VERSION "HNNBNNNYNNNNNNNNNNNNNNNNNNNNNNNNNNNNNNNNNN/4/%%%/4/'%**4NNN///"

NS_ :

BS_:

BU_: AEM BAP_Tester E_Sound FBK FLA Gateway Gateway_PAG ISE MRR_HL MRR_HR NightVision RDK SAK SAK2 SCR STH_MLBevo TopView

BO_ 917 LWR_AFS_01: 8 Gateway
 SG_ AFS_Abbiegelicht_li_Anf : 0|1@1+ (1.0,0.0) [0.0|1] ""  Vector__XXX
 SG_ AFS_Abbiegelicht_re_Anf : 1|1@1+ (1.0,0.0) [0.0|1] ""  Vector__XXX
 SG_ AFS_Abbiegelicht_Dimm_Anf : 2|1@1+ (1.0,0.0) [0.0|1] ""  Vector__XXX
 SG_ AFS_Verfuegbarkeit_GLW : 3|1@1+ (1.0,0.0) [0.0|1] ""  Vector__XXX
 SG_ AFS_Status_adaptive_LV : 4|1@1+ (1.0,0.0) [0.0|1] ""  Vector__XXX
 SG_ AFS_Fernlicht_li_defekt : 5|1@1+ (1.0,0.0) [0.0|1] ""  Vector__XXX
 SG_ AFS_Fernlicht_re_defekt : 6|1@1+ (1.0,0.0) [0.0|1] ""  Vector__XXX
 SG_ AFS_Fernlicht_Status : 7|1@1+ (1.0,0.0) [0.0|1] ""  Vector__XXX
 SG_ LWR_AFS_01_BZ : 8|4@1+ (1,0) [0|15] ""  Vector__XXX
 SG_ AFS_Lampe : 12|1@1+ (1.0,0.0) [0.0|1] ""  Vector__XXX
 SG_ LWR_Lampe : 13|1@1+ (1.0,0.0) [0.0|1] ""  Vector__XXX
 SG_ AFS_Fehlertext : 14|1@1+ (1.0,0.0) [0.0|1] ""  Vector__XXX
 SG_ AFS_LED_Blinkmode : 15|1@1+ (1.0,0.0) [0.0|1] ""  Vector__XXX
 SG_ LWR_Touristenmodus_aktiv : 16|1@1+ (1.0,0.0) [0.0|1] ""  Vector__XXX
 SG_ AFS_Charisma_FahrPr : 17|4@1+ (1.0,0.0) [0.0|15] ""  Vector__XXX
 SG_ AFS_Charisma_Status : 21|2@1+ (1.0,0.0) [0.0|3] ""  Vector__XXX
 SG_ LWR_Sicherheitsposition_re : 23|1@1+ (1.0,0.0) [0.0|1] ""  Vector__XXX
 SG_ AFS_Allwetterlicht : 24|1@1+ (1.0,0.0) [0.0|1] ""  Vector__XXX
 SG_ LWR_Touristenmodus_verbaut : 25|1@1+ (1.0,0.0) [0.0|1] ""  Vector__XXX
 SG_ AFS_adaptive_LV_verbaut : 26|1@1+ (1.0,0.0) [0.0|1] ""  Vector__XXX
 SG_ LWR_Reisemodus_Texte : 27|2@1+ (1.0,0.0) [0.0|3] ""  Vector__XXX
 SG_ GLW_Sensor_blockiert : 29|1@1+ (1.0,0.0) [0.0|1] ""  Vector__XXX
 SG_ AFS_Charisma_Umschaltung : 30|2@1+ (1.0,0.0) [0.0|3] ""  Vector__XXX
 SG_ LWR_Pos_Schrittmotor : 32|8@1+ (0.4,0) [0.0|100.0] "Unit_PerCent"  Vector__XXX
 SG_ LWR_Hoehenwert_VL : 40|8@1+ (1,-127) [-127|126] ""  NightVision,TopView
 SG_ LWR_Hoehenwert_HL : 48|8@1+ (1,-127) [-127|126] ""  NightVision,TopView
 SG_ AFS_Ersatzlicht_Links : 56|1@1+ (1.0,0.0) [0.0|1] ""  Vector__XXX
 SG_ AFS_Ersatzlicht_Rechts : 57|1@1+ (1.0,0.0) [0.0|1] ""  Vector__XXX
 SG_ LWR_AFS_Grundeinstellung : 58|1@1+ (1.0,0.0) [0.0|1] ""  NightVision
 SG_ LWR_AFS_Parametrisierung : 59|1@1+ (1.0,0.0) [0.0|1] ""  Vector__XXX
 SG_ LWR_Initialisierungslauf : 60|1@1+ (1.0,0.0) [0.0|1] ""  Vector__XXX
 SG_ LWR_Sicherheitsposition_li : 61|1@1+ (1.0,0.0) [0.0|1] ""  Vector__XXX
 SG_ LWR_Modus : 62|1@1+ (1.0,0.0) [0.0|1] ""  Vector__XXX

BO_ 1153 MainUnit_01: 8 Gateway
 SG_ ZR_LoGeWa_Event_Kombiwarnung : 0|4@1+ (1.0,0.0) [0.0|15] ""  Vector__XXX
 SG_ Nav_FoD_Status : 4|3@1+ (1.0,0.0) [0.0|7] ""  NightVision
 SG_ MIB_Tongenerator_PH_verfuegbar : 9|3@1+ (1.0,0.0) [0.0|7] ""  Vector__XXX
 SG_ MMI_Counter_Bedienevent : 12|4@1+ (1.0,0.0) [0.0|15] ""  Vector__XXX
 SG_ DSSS_Warning : 16|5@1+ (1.0,0.0) [0.0|31] ""  Vector__XXX
 SG_ ZR_Kindersicherung_RSE : 21|1@1+ (1.0,0.0) [0.0|1] ""  Vector__XXX
 SG_ ZR_RSE_aktivieren : 22|1@1+ (1.0,0.0) [0.0|1] ""  Vector__XXX
 SG_ MMI_SDS_aktiv : 23|1@1+ (1.0,0.0) [0.0|1] ""  Vector__XXX
 SG_ MU_SecondDisplay : 24|3@1+ (1.0,0.0) [0.0|7] ""  Vector__XXX
 SG_ MMI_Telefon_aktiv : 27|1@1+ (1.0,0.0) [0.0|1] ""  Vector__XXX
 SG_ MMI_Gurt_Mic_ref : 28|1@1+ (1.0,0.0) [0.0|1] ""  Vector__XXX
 SG_ ZR_Sta_Inszenierung : 29|2@1+ (1.0,0.0) [0.0|3] ""  Vector__XXX
 SG_ MMI_Gauges_active : 31|1@1+ (1.0,0.0) [0.0|1] ""  Vector__XXX
 SG_ MU_Update_Time : 32|8@1+ (0.1,0) [0.0|25.5] "Unit_Hours"  Vector__XXX
 SG_ ZR_MXB_Manoever_Ansage : 42|2@1+ (1.0,0.0) [0.0|3] ""  Vector__XXX
 SG_ ZR_LAPP_Sondermodus_Status : 44|2@1+ (1.0,0.0) [0.0|3] ""  Vector__XXX
 SG_ MMI_StartStopp_Info : 46|2@1+ (1.0,0.0) [0.0|3] ""  Vector__XXX
 SG_ ZR_Parken_Sondermodus : 48|4@1+ (1.0,0.0) [0.0|15] ""  Vector__XXX
 SG_ ZR_Rundenbewertung : 52|4@1+ (1.0,0.0) [0.0|15] ""  Vector__XXX
 SG_ ZR_Rundenfortschritt : 56|8@1+ (0.5,0) [0.0|100.0] "Unit_PerCent"  Vector__XXX

BO_ 1600 Motor_07: 8 Gateway
 SG_ MO_QBit_Ansaugluft_Temp : 0|1@1+ (1.0,0.0) [0.0|1] ""  Vector__XXX
 SG_ MO_QBit_Oel_Temp : 1|1@1+ (1.0,0.0) [0.0|1] ""  Vector__XXX
 SG_ MO_QBit_Kuehlmittel_Temp : 2|1@1+ (1.0,0.0) [0.0|1] ""  STH_MLBevo
 SG_ MO_KL15_Abschaltempfehlung : 3|1@1+ (1.0,0.0) [0.0|1] ""  Vector__XXX
 SG_ MO_HYB_Fehler_HV_Netz : 4|1@1+ (1.0,0.0) [0.0|1] ""  Vector__XXX
 SG_ MO_aktives_Getriebeheizen : 5|1@1+ (1.0,0.0) [0.0|1] ""  Vector__XXX
 SG_ MO_Absperrventil_oeffnen : 6|2@1+ (1.0,0.0) [0.0|3] ""  STH_MLBevo
 SG_ MO_Ansaugluft_Temp : 8|8@1+ (0.75,-48) [-48.00|141.75] "Unit_DegreCelsi"  Vector__XXX
 SG_ MO_Oel_Temp : 16|8@1+ (1,-60) [-60|192] "Unit_DegreCelsi"  AEM
 SG_ MO_Kuehlmittel_Temp : 24|8@1+ (0.75,-48) [-48.00|141.75] "Unit_DegreCelsi"  AEM,STH_MLBevo
 SG_ MO_Hoeheninfo : 32|8@1+ (0.00781,0) [0.00000|1.98374] ""  STH_MLBevo
 SG_ MO_Kennfeldk : 40|1@1+ (1.0,0.0) [0.0|1] ""  Vector__XXX
 SG_ MO_Versionsinfo_02 : 41|5@1+ (1.0,0.0) [0.0|31] ""  Vector__XXX
 SG_ MO_QBit_Hoeheninfo : 46|1@1+ (1.0,0.0) [0.0|1] ""  Vector__XXX
 SG_ MO_Getriebe_kuehlen : 47|1@1+ (1.0,0.0) [0.0|1] ""  Vector__XXX
 SG_ MO_Mom_Traegheit_02 : 48|5@1+ (0.01,0) [0.00|0.31] "Unit_KiloGramMeterSquar"  Vector__XXX
 SG_ MO_Heizungspumpenansteuerung : 53|4@1+ (10,0) [0|100] "Unit_PerCent"  STH_MLBevo
 SG_ MO_SpannungsAnf : 57|1@1+ (1.0,0.0) [0.0|1] ""  Vector__XXX
 SG_ MO_Nachlaufzeit_Heizungspumpe : 58|6@1+ (15,0) [0|945] "Unit_Secon"  STH_MLBevo

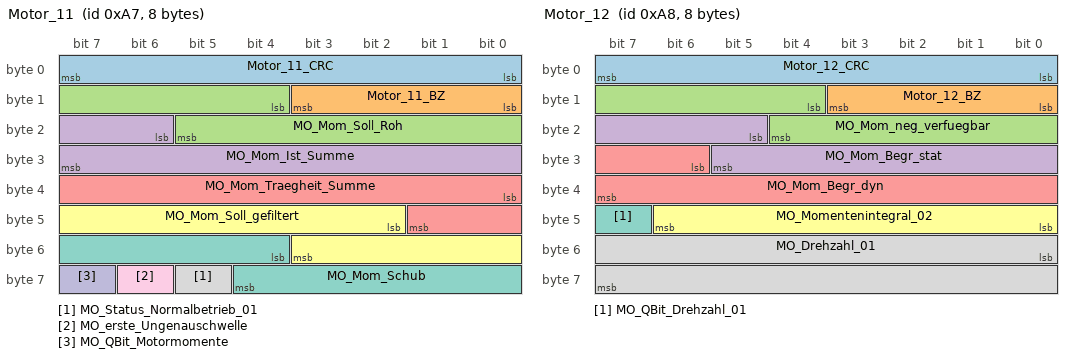
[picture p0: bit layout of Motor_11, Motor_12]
BO_ 167 Motor_11: 8 Gateway
 SG_ Motor_11_CRC : 0|8@1+ (1,0) [0|255] ""  Vector__XXX
 SG_ Motor_11_BZ : 8|4@1+ (1,0) [0|15] ""  Vector__XXX
 SG_ MO_Mom_Soll_Roh : 12|10@1+ (1,-509) [-509|509] ""  Vector__XXX
 SG_ MO_Mom_Ist_Summe : 22|10@1+ (1,-509) [-509|509] ""  AEM,E_Sound,ISE,SAK,SAK2
 SG_ MO_Mom_Traegheit_Summe : 32|10@1+ (1,-509) [-509|509] ""  Vector__XXX
 SG_ MO_Mom_Soll_gefiltert : 42|10@1+ (1,-509) [-509|509] ""  Vector__XXX
 SG_ MO_Mom_Schub : 52|9@1+ (1,-509) [-509|0] ""  Vector__XXX
 SG_ MO_Status_Normalbetrieb_01 : 61|1@1+ (1.0,0.0) [0.0|1] ""  Vector__XXX
 SG_ MO_erste_Ungenauschwelle : 62|1@1+ (1.0,0.0) [0.0|1] ""  Vector__XXX
 SG_ MO_QBit_Motormomente : 63|1@1+ (1.0,0.0) [0.0|1] ""  AEM

BO_ 168 Motor_12: 8 Gateway
 SG_ Motor_12_CRC : 0|8@1+ (1,0) [0|255] ""  Vector__XXX
 SG_ Motor_12_BZ : 8|4@1+ (1,0) [0|15] ""  Vector__XXX
 SG_ MO_Mom_neg_verfuegbar : 12|9@1+ (1,-509) [-509|0] ""  Vector__XXX
 SG_ MO_Mom_Begr_stat : 21|9@1+ (1,0) [0|509] ""  Vector__XXX
 SG_ MO_Mom_Begr_dyn : 30|10@1+ (1,-509) [-509|509] ""  Vector__XXX
 SG_ MO_Momentenintegral_02 : 40|7@1+ (1,0) [0|100] "Unit_PerCent"  Vector__XXX
 SG_ MO_QBit_Drehzahl_01 : 47|1@1+ (1.0,0.0) [0.0|1] ""  AEM,SCR,STH_MLBevo
 SG_ MO_Drehzahl_01 : 48|16@1+ (0.25,0) [0.00|16383.00] "Unit_MinutInver"  AEM,E_Sound,ISE,SAK,SAK2,SCR,STH_MLBevo

BO_ 958 Motor_14: 8 Gateway
 SG_ Motor_14_CRC : 0|8@1+ (1,0) [0|255] ""  Vector__XXX
 SG_ Motor_14_BZ : 8|4@1+ (1,0) [0|15] ""  Vector__XXX
 SG_ MO_StartStopp_Status : 12|2@1+ (1.0,0.0) [0.0|3] ""  AEM,SCR
 SG_ MO_StartStopp_Wiederstart : 14|1@1+ (1.0,0.0) [0.0|1] ""  AEM,FLA,SCR,STH_MLBevo
 SG_ MO_StartStopp_Motorstopp : 15|1@1+ (1.0,0.0) [0.0|1] ""  AEM,NightVision,SCR,STH_MLBevo
 SG_ MO_Freig_Reku : 16|2@1+ (1.0,0.0) [0.0|3] ""  Vector__XXX
 SG_ MO_Kl_75 : 18|1@1+ (1.0,0.0) [0.0|1] ""  AEM,FLA,SCR
 SG_ MO_Kl_50 : 19|1@1+ (1.0,0.0) [0.0|1] ""  AEM
 SG_ MO_Gangposition : 20|4@1+ (1.0,0.0) [0.0|15] ""  E_Sound,FLA,ISE,NightVision,SAK2
 SG_ MO_StartStopp_Fahrerwunsch : 24|2@1+ (1.0,0.0) [0.0|3] ""  AEM,SCR
 SG_ MO_HYB_Fahrbereitschaft : 26|1@1+ (1.0,0.0) [0.0|1] ""  E_Sound,ISE
 SG_ MO_Ext_E_Fahrt_aktiv : 27|1@1+ (1.0,0.0) [0.0|1] ""  Vector__XXX
 SG_ MO_Fahrer_bremst : 28|1@1+ (1.0,0.0) [0.0|1] ""  Vector__XXX
 SG_ MO_QBit_Fahrer_bremst : 29|1@1+ (1.0,0.0) [0.0|1] ""  Vector__XXX
 SG_ MO_BLS : 30|1@1+ (1.0,0.0) [0.0|1] ""  Vector__XXX
 SG_ MO_Konsistenz_Bremsped : 31|1@1+ (1.0,0.0) [0.0|1] ""  Vector__XXX
 SG_ MO_KomFehler_ESP : 32|1@1+ (1.0,0.0) [0.0|1] ""  Vector__XXX
 SG_ MO_Klima_Eingr : 33|2@1+ (1.0,0.0) [0.0|3] ""  Vector__XXX
 SG_ MO_Aussp_Anlass : 35|1@1+ (1.0,0.0) [0.0|1] ""  Vector__XXX
 SG_ MO_Freig_Anlass : 36|1@1+ (1.0,0.0) [0.0|1] ""  Vector__XXX
 SG_ MO_Kuppl_schalter : 37|1@1+ (1.0,0.0) [0.0|1] ""  SAK,SAK2
 SG_ MO_Interlock : 38|1@1+ (1.0,0.0) [0.0|1] ""  Vector__XXX
 SG_ MO_Motor_laeuft : 39|1@1+ (1.0,0.0) [0.0|1] ""  AEM,STH_MLBevo
 SG_ MO_Kickdown : 40|1@1+ (1.0,0.0) [0.0|1] ""  Vector__XXX
 SG_ MO_QBit_KL_75 : 41|1@1+ (1.0,0.0) [0.0|1] ""  SCR
 SG_ MO_EKlKomLeiRed : 42|2@1+ (1.0,0.0) [0.0|3] ""  Vector__XXX
 SG_ MO_Handshake_STH : 44|1@1+ (1.0,0.0) [0.0|1] ""  STH_MLBevo
 SG_ MO_BKV_Unterdruckwarnung : 45|1@1+ (1.0,0.0) [0.0|1] ""  Vector__XXX
 SG_ MO_Freigabe_Segeln : 46|1@1+ (1.0,0.0) [0.0|1] ""  Vector__XXX
 SG_ MO_PTC_Status : 47|3@1+ (1.0,0.0) [0.0|7] ""  Vector__XXX
 SG_ MO_QBit_Gangposition : 50|1@1+ (1.0,0.0) [0.0|1] ""  Vector__XXX
 SG_ MO_Signalquelle_Gangposition : 51|1@1+ (1.0,0.0) [0.0|1] ""  Vector__XXX
 SG_ MO_Remotestart_Betrieb : 52|1@1+ (1.0,0.0) [0.0|1] ""  Vector__XXX
 SG_ MO_Remotestart_moeglich : 53|1@1+ (1.0,0.0) [0.0|1] ""  Vector__XXX
 SG_ MO_Text_Geschw_red : 54|1@1+ (1.0,0.0) [0.0|1] ""  Vector__XXX
 SG_ MO_FMAus_aktiv : 55|1@1+ (1.0,0.0) [0.0|1] ""  Vector__XXX
 SG_ MO_FMAus_Startvariante : 56|2@1+ (1.0,0.0) [0.0|3] ""  Vector__XXX
 SG_ MO_BMS_NV_Anf_stuetzen : 58|1@1+ (1.0,0.0) [0.0|1] ""  Vector__XXX
 SG_ MO_Zylinderabschaltung : 59|2@1+ (1.0,0.0) [0.0|3] ""  AEM,SAK,SAK2
 SG_ MO_HYB_VM_aktiv : 61|1@1+ (1.0,0.0) [0.0|1] ""  E_Sound,ISE,SAK,SAK2
 SG_ MO_StartVorauss_erfuellt : 62|2@1+ (1.0,0.0) [0.0|3] ""  Vector__XXX

BO_ 1648 Motor_18: 8 Gateway
 SG_ MO_max_Ladedruck : 0|6@1+ (0.1,0) [0.0|6.3] "Unit_Bar"  Vector__XXX
 SG_ MO_ANC_Kennfeld_Anf : 6|2@1+ (1.0,0.0) [0.0|3] ""  Vector__XXX
 SG_ MO_Bremslicht_Reku : 8|1@1+ (1.0,0.0) [0.0|1] ""  Vector__XXX
 SG_ MO_StartStopp_PopUp : 9|2@1+ (1.0,0.0) [0.0|3] ""  Vector__XXX
 SG_ MO1_Sperr_Info_WFS : 11|1@1+ (1.0,0.0) [0.0|1] ""  Vector__XXX
 SG_ MO1_Freigabe_Info_WFS : 12|1@1+ (1.0,0.0) [0.0|1] ""  Vector__XXX
 SG_ MO_EPCL : 13|3@1+ (1.0,0.0) [0.0|7] ""  Vector__XXX
 SG_ MO_Zylabsch_Texte_02 : 16|4@1+ (1.0,0.0) [0.0|15] ""  Vector__XXX
 SG_ MO_Fahrzeugtyp : 20|3@1+ (1.0,0.0) [0.0|7] ""  Vector__XXX
 SG_ MO_NMAX_Schaltanzeige : 23|9@1+ (25,0) [0|12775] "Unit_MinutInver"  Vector__XXX
 SG_ MO_Abstellzeit : 32|8@1+ (8,0) [0|2024] "Unit_Minut"  SCR
 SG_ MO_Abstellzeit_Status : 40|2@1+ (1.0,0.0) [0.0|3] ""  SCR
 SG_ MO1_Freigabe_Verfallsinfo_WFS : 42|1@1+ (1.0,0.0) [0.0|1] ""  Vector__XXX
 SG_ MO_Hybrid_StartStopp_LED : 43|2@1+ (1.0,0.0) [0.0|3] ""  Vector__XXX
 SG_ MO_Fehler_Zylabsch : 45|2@1+ (1.0,0.0) [0.0|3] ""  Vector__XXX
 SG_ MO_Anzahl_Abgesch_Zyl : 47|3@1+ (1.0,0.0) [0.0|7] ""  Vector__XXX
 SG_ MO_Zylabsch_Texte : 50|2@1+ (1.0,0.0) [0.0|3] ""  Vector__XXX
 SG_ MO_Ethanol_BS_Texte : 52|3@1+ (1.0,0.0) [0.0|7] ""  Vector__XXX
 SG_ MO_Drehzahl_Warnung : 55|1@1+ (1.0,0.0) [0.0|1] ""  Vector__XXX
 SG_ MO_obere_Drehzahlgrenze : 56|8@1+ (50,0) [50|12750] "Unit_MinutInver"  Vector__XXX

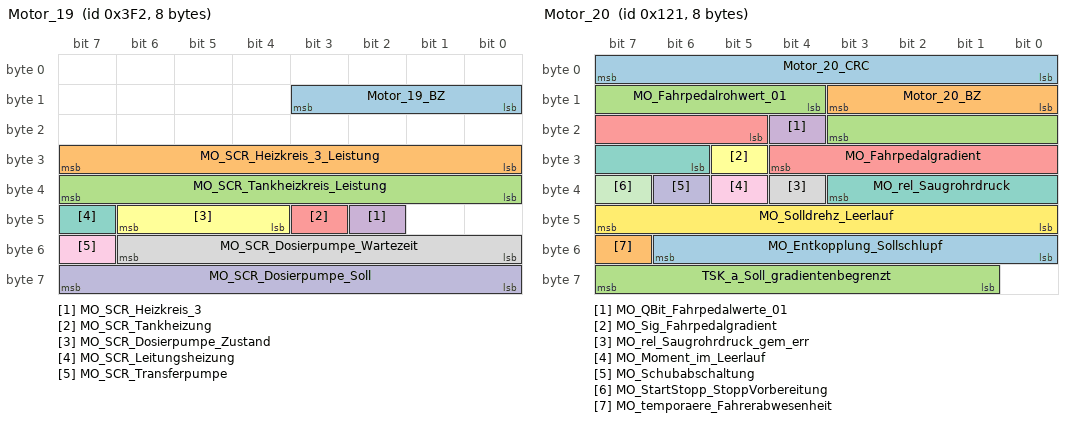
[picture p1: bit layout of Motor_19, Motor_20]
BO_ 1010 Motor_19: 8 Gateway
 SG_ Motor_19_BZ : 8|4@1+ (1,0) [0|15] ""  SCR
 SG_ MO_SCR_Heizkreis_3_Leistung : 24|8@1+ (1,0) [0|150] "Unit_Watt"  SCR
 SG_ MO_SCR_Tankheizkreis_Leistung : 32|8@1+ (1,0) [0|150] "Unit_Watt"  SCR
 SG_ MO_SCR_Heizkreis_3 : 42|1@1+ (1.0,0.0) [0.0|1] ""  SCR
 SG_ MO_SCR_Tankheizung : 43|1@1+ (1.0,0.0) [0.0|1] ""  SCR
 SG_ MO_SCR_Dosierpumpe_Zustand : 44|3@1+ (1.0,0.0) [0.0|7] ""  SCR
 SG_ MO_SCR_Leitungsheizung : 47|1@1+ (1.0,0.0) [0.0|1] ""  SCR
 SG_ MO_SCR_Dosierpumpe_Wartezeit : 48|7@1+ (1,0) [0|120] "Unit_Secon"  SCR
 SG_ MO_SCR_Transferpumpe : 55|1@1+ (1.0,0.0) [0.0|1] ""  Vector__XXX
 SG_ MO_SCR_Dosierpumpe_Soll : 56|8@1+ (0.4,0) [0.0|100.0] "Unit_PerCent"  SCR

BO_ 289 Motor_20: 8 Gateway
 SG_ Motor_20_CRC : 0|8@1+ (1,0) [0|255] ""  Vector__XXX
 SG_ Motor_20_BZ : 8|4@1+ (1,0) [0|15] ""  Vector__XXX
 SG_ MO_Fahrpedalrohwert_01 : 12|8@1+ (0.4,0) [0.0|101.6] "Unit_PerCent"  E_Sound,ISE,SAK,SAK2
 SG_ MO_QBit_Fahrpedalwerte_01 : 20|1@1+ (1.0,0.0) [0.0|1] ""  Vector__XXX
 SG_ MO_Fahrpedalgradient : 21|8@1+ (25,0) [0|6350] "Unit_PerCentPerSecon"  Vector__XXX
 SG_ MO_Sig_Fahrpedalgradient : 29|1@1+ (1.0,0.0) [0.0|1] ""  Vector__XXX
 SG_ MO_rel_Saugrohrdruck : 30|6@1+ (18,0) [0|1116] "Unit_MilliBar"  Vector__XXX
 SG_ MO_rel_Saugrohrdruck_gem_err : 36|1@1+ (1.0,0.0) [0.0|1] ""  Vector__XXX
 SG_ MO_Moment_im_Leerlauf : 37|1@1+ (1.0,0.0) [0.0|1] ""  Vector__XXX
 SG_ MO_Schubabschaltung : 38|1@1+ (1.0,0.0) [0.0|1] ""  Vector__XXX
 SG_ MO_StartStopp_StoppVorbereitung : 39|1@1+ (1.0,0.0) [0.0|1] ""  Vector__XXX
 SG_ MO_Solldrehz_Leerlauf : 40|8@1+ (10,0) [0|2540] "Unit_MinutInver"  Vector__XXX
 SG_ MO_Entkopplung_Sollschlupf : 48|7@1+ (20,0) [0|2480] "Unit_MinutInver"  Vector__XXX
 SG_ MO_temporaere_Fahrerabwesenheit : 55|1@1+ (1.0,0.0) [0.0|1] ""  Vector__XXX
 SG_ TSK_a_Soll_gradientenbegrenzt : 57|7@1+ (0.1,-7.2) [-7.2|5.4] "Unit_MeterPerSeconSquar"  Vector__XXX

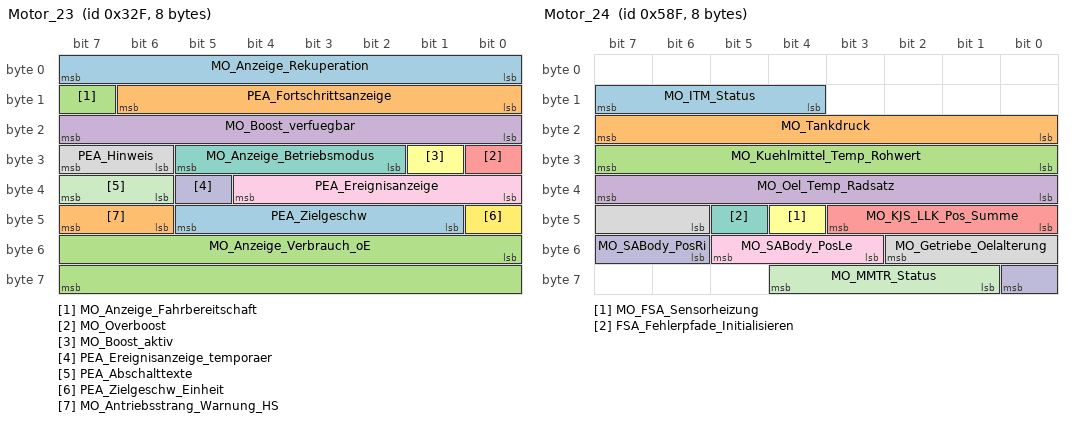
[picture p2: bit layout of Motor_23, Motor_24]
BO_ 815 Motor_23: 8 Gateway
 SG_ MO_Anzeige_Rekuperation : 0|8@1+ (0.5,-0.5) [0.0|100.0] "Unit_PerCent"  Vector__XXX
 SG_ PEA_Fortschrittsanzeige : 8|7@1+ (1,0) [0|100] "Unit_PerCent"  Vector__XXX
 SG_ MO_Anzeige_Fahrbereitschaft : 15|1@1+ (1.0,0.0) [0.0|1] ""  Vector__XXX
 SG_ MO_Boost_verfuegbar : 16|8@1+ (0.4,-0.4) [0.0|100.4] "Unit_PerCent"  Vector__XXX
 SG_ MO_Overboost : 24|1@1+ (1.0,0.0) [0.0|1] ""  Vector__XXX
 SG_ MO_Boost_aktiv : 25|1@1+ (1.0,0.0) [0.0|1] ""  E_Sound,ISE
 SG_ MO_Anzeige_Betriebsmodus : 26|4@1+ (1.0,0.0) [0.0|15] ""  Vector__XXX
 SG_ PEA_Hinweis : 30|2@1+ (1.0,0.0) [0.0|3] ""  Vector__XXX
 SG_ PEA_Ereignisanzeige : 32|5@1+ (1.0,0.0) [0.0|31] ""  Vector__XXX
 SG_ PEA_Ereignisanzeige_temporaer : 37|1@1+ (1.0,0.0) [0.0|1] ""  Vector__XXX
 SG_ PEA_Abschalttexte : 38|2@1+ (1.0,0.0) [0.0|3] ""  Vector__XXX
 SG_ PEA_Zielgeschw_Einheit : 40|1@1+ (1.0,0.0) [0.0|1] ""  Vector__XXX
 SG_ PEA_Zielgeschw : 41|5@1+ (1.0,0.0) [0.0|31] ""  Vector__XXX
 SG_ MO_Antriebsstrang_Warnung_HS : 46|2@1+ (1.0,0.0) [0.0|3] ""  Vector__XXX
 SG_ MO_Anzeige_Verbrauch_oE : 48|16@1+ (0.005,0) [0.000|327.675] "Unit_None"  Vector__XXX

BO_ 1423 Motor_24: 8 Gateway
 SG_ MO_ITM_Status : 12|4@1+ (1.0,0.0) [0.0|15] ""  Vector__XXX
 SG_ MO_Tankdruck : 16|8@1+ (2,-250) [-250|256] "Unit_MilliBar"  STH_MLBevo
 SG_ MO_Kuehlmittel_Temp_Rohwert : 24|8@1+ (0.75,-48) [-48.00|141.75] "Unit_DegreCelsi"  Vector__XXX
 SG_ MO_Oel_Temp_Radsatz : 32|8@1+ (1,-60) [-60|193] "Unit_DegreCelsi"  Vector__XXX
 SG_ MO_KJS_LLK_Pos_Summe : 40|4@1+ (10,0) [0|100] "Unit_PerCent"  Vector__XXX
 SG_ MO_FSA_Sensorheizung : 44|1@1+ (1.0,0.0) [0.0|1] ""  Vector__XXX
 SG_ FSA_Fehlerpfade_Initialisieren : 45|1@1+ (1.0,0.0) [0.0|1] ""  Vector__XXX
 SG_ MO_Getriebe_Oelalterung : 46|5@1+ (5,0) [0|100] "Unit_PerCent"  Vector__XXX
 SG_ MO_SABody_PosLe : 51|3@1+ (20,-20) [0|100] "Unit_PerCent"  Vector__XXX
 SG_ MO_SABody_PosRi : 54|3@1+ (20,-20) [0|100] "Unit_PerCent"  Vector__XXX
 SG_ MO_MMTR_Status : 57|4@1+ (1.0,0.0) [0.0|15] ""  Vector__XXX

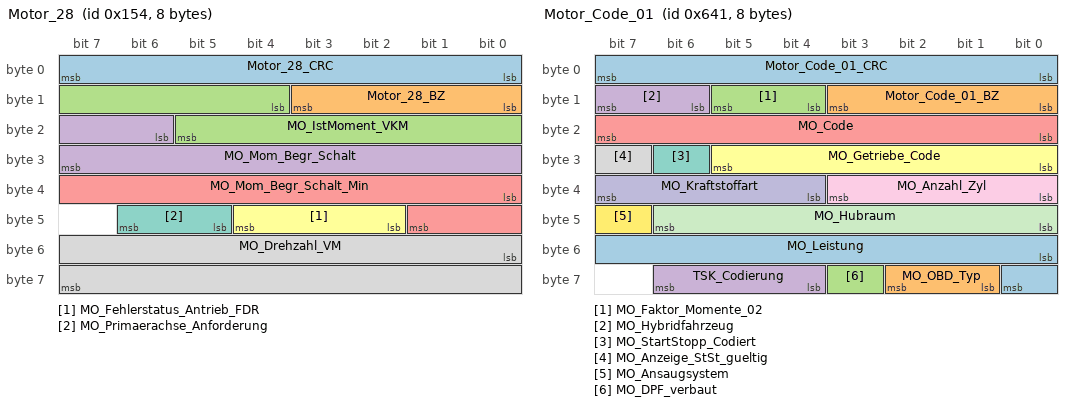
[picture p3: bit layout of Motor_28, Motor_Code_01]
BO_ 340 Motor_28: 8 Gateway
 SG_ Motor_28_CRC : 0|8@1+ (1,0) [0|255] ""  Vector__XXX
 SG_ Motor_28_BZ : 8|4@1+ (1,0) [0|15] ""  Vector__XXX
 SG_ MO_IstMoment_VKM : 12|10@1+ (1,-509) [-509|509] ""  Vector__XXX
 SG_ MO_Mom_Begr_Schalt : 22|10@1+ (1,-509) [-509|509] ""  Vector__XXX
 SG_ MO_Mom_Begr_Schalt_Min : 32|10@1+ (1,-509) [-509|509] ""  Vector__XXX
 SG_ MO_Fehlerstatus_Antrieb_FDR : 42|3@1+ (1.0,0.0) [0.0|7] ""  Vector__XXX
 SG_ MO_Primaerachse_Anforderung : 45|2@1+ (1.0,0.0) [0.0|3] ""  Vector__XXX
 SG_ MO_Drehzahl_VM : 48|16@1+ (0.25,0) [0.00|16383.00] "Unit_MinutInver"  AEM

BO_ 1601 Motor_Code_01: 8 Gateway
 SG_ Motor_Code_01_CRC : 0|8@1+ (1,0) [0|255] ""  Vector__XXX
 SG_ Motor_Code_01_BZ : 8|4@1+ (1,0) [0|15] ""  Vector__XXX
 SG_ MO_Faktor_Momente_02 : 12|2@1+ (1,0) [1|3] "Unit_NewtoMeter"  AEM
 SG_ MO_Hybridfahrzeug : 14|2@1+ (1.0,0.0) [0.0|3] ""  Vector__XXX
 SG_ MO_Code : 16|8@1+ (1,0) [0|255] ""  E_Sound,ISE,SAK,SAK2
 SG_ MO_Getriebe_Code : 24|6@1+ (1.0,0.0) [0.0|63] ""  Vector__XXX
 SG_ MO_StartStopp_Codiert : 30|1@1+ (1.0,0.0) [0.0|1] ""  Vector__XXX
 SG_ MO_Anzeige_StSt_gueltig : 31|1@1+ (1.0,0.0) [0.0|1] ""  Vector__XXX
 SG_ MO_Anzahl_Zyl : 32|4@1+ (1.0,0.0) [0.0|15] ""  Vector__XXX
 SG_ MO_Kraftstoffart : 36|4@1+ (1.0,0.0) [0.0|15] ""  STH_MLBevo
 SG_ MO_Hubraum : 40|7@1+ (0.1,0) [0.0|12.7] "Unit_Liter"  Vector__XXX
 SG_ MO_Ansaugsystem : 47|1@1+ (1.0,0.0) [0.0|1] ""  Vector__XXX
 SG_ MO_Leistung : 48|9@1+ (1,0) [0|511] "Unit_KiloWatt"  SAK,SAK2
 SG_ MO_OBD_Typ : 57|2@1+ (1.0,0.0) [0.0|3] ""  SCR
 SG_ MO_DPF_verbaut : 59|1@1+ (1.0,0.0) [0.0|1] ""  Vector__XXX
 SG_ TSK_Codierung : 60|3@1+ (1.0,0.0) [0.0|7] ""  Vector__XXX

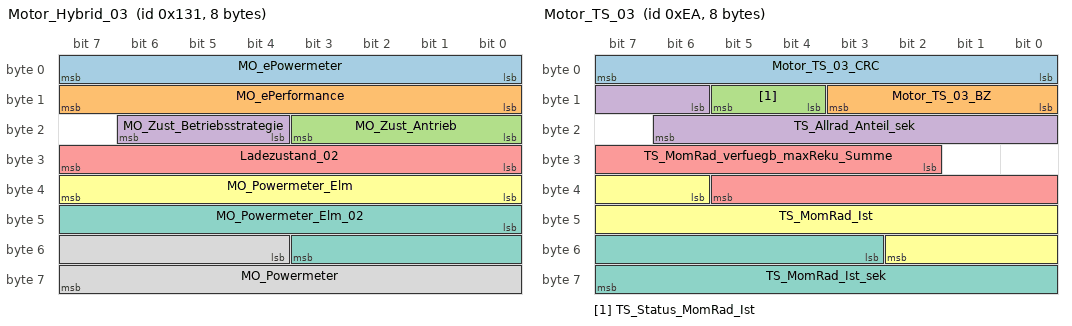
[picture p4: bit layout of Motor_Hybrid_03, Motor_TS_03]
BO_ 305 Motor_Hybrid_03: 8 Gateway
 SG_ MO_ePowermeter : 0|8@1+ (0.4,-0.4) [0.0|100.8] "Unit_PerCent"  Vector__XXX
 SG_ MO_ePerformance : 8|8@1+ (0.4,-0.4) [0.0|100.8] "Unit_PerCent"  Vector__XXX
 SG_ MO_Zust_Antrieb : 16|4@1+ (1.0,0.0) [0.0|15] ""  Vector__XXX
 SG_ MO_Zust_Betriebsstrategie : 20|3@1+ (1.0,0.0) [0.0|7] ""  Vector__XXX
 SG_ Ladezustand_02 : 24|8@1+ (0.5,0) [0.0|100.0] "Unit_PerCent"  Vector__XXX
 SG_ MO_Powermeter_Elm : 32|8@1+ (1,-128) [-100|100] "Unit_PerCent"  Vector__XXX
 SG_ MO_Powermeter_Elm_02 : 40|12@1+ (0.05,-102.4) [-100.00|100.00] "Unit_PerCent"  Vector__XXX
 SG_ MO_Powermeter : 52|12@1+ (1,0) [0|4092] ""  SAK,SAK2

BO_ 394 Motor_Hybrid_11: 8 Gateway
 SG_ MO_Ablaufstatus : 12|4@1+ (1.0,0.0) [0.0|15] ""  Vector__XXX
 SG_ MO_Ablaufstrg_Betriebszustand : 16|3@1+ (1.0,0.0) [0.0|7] ""  Vector__XXX
 SG_ MO_Ablaufstrg_Zustand_VKM_Ist : 19|1@1+ (1.0,0.0) [0.0|1] ""  Vector__XXX
 SG_ MO_Ablaufstrg_Kraftschluss_Ist : 20|1@1+ (1.0,0.0) [0.0|1] ""  Vector__XXX
 SG_ MO_Ablaufstrg_Zustand_K0_Ist : 21|1@1+ (1.0,0.0) [0.0|1] ""  Vector__XXX
 SG_ MO_Ablaufstrg_Kraftschluss2_Ist : 22|1@1+ (1.0,0.0) [0.0|1] ""  Vector__XXX
 SG_ MO_HYB_LowSpeedModus : 23|1@1+ (1.0,0.0) [0.0|1] ""  Vector__XXX
 SG_ MO_Ablaufstrg_Zustand_VKM_Ziel : 24|1@1+ (1.0,0.0) [0.0|1] ""  Vector__XXX
 SG_ MO_Ablaufstrg_Kraftschluss_Ziel : 25|1@1+ (1.0,0.0) [0.0|1] ""  Vector__XXX
 SG_ MO_Ablaufstrg_Zustand_K0_Ziel : 26|1@1+ (1.0,0.0) [0.0|1] ""  Vector__XXX
 SG_ MO_Ablaufstrg_Kraftschluss2_Ziel : 27|1@1+ (1.0,0.0) [0.0|1] ""  Vector__XXX
 SG_ MO_HYB_Stoppmodus : 28|1@1+ (1.0,0.0) [0.0|1] ""  Vector__XXX
 SG_ MO_Auth_Aufforderung_WFS : 29|1@1+ (1.0,0.0) [0.0|1] ""  Vector__XXX
 SG_ MO_Start_Dynamik : 30|3@1+ (1.0,0.0) [0.0|7] ""  Vector__XXX
 SG_ MO_Start_Art : 33|3@1+ (1.0,0.0) [0.0|7] ""  SCR
 SG_ MO_Abstellposition_02 : 36|8@1+ (2,0) [0|508] "Unit_DegreOfArc"  Vector__XXX
 SG_ MO_Mom_Freiheit_Sekundaerachse : 44|1@1+ (1.0,0.0) [0.0|1] ""  Vector__XXX
 SG_ MO_Nachlaufzeit_Kuehlerluefter : 45|6@1+ (15,0) [0|945] "Unit_Secon"  Vector__XXX
 SG_ MO_Tankklappensteuerung : 51|2@1+ (1.0,0.0) [0.0|3] ""  Vector__XXX
 SG_ MO_HYB_E_Faktor : 53|4@1+ (1.0,0.0) [0.0|15] ""  Vector__XXX
 SG_ MO_HYB_EMode_Info : 57|2@1+ (1.0,0.0) [0.0|3] ""  Vector__XXX
 SG_ MO_HYB_Adaption_aktiv : 59|1@1+ (1.0,0.0) [0.0|1] ""  Vector__XXX

BO_ 234 Motor_TS_03: 8 Gateway
 SG_ Motor_TS_03_CRC : 0|8@1+ (1,0) [0|255] ""  Vector__XXX
 SG_ Motor_TS_03_BZ : 8|4@1+ (1,0) [0|15] ""  Vector__XXX
 SG_ TS_Status_MomRad_Ist : 12|2@1+ (1.0,0.0) [0.0|3] ""  Vector__XXX
 SG_ TS_Allrad_Anteil_sek : 14|9@1+ (0.2,0) [0.0|100.0] "Unit_PerCent"  Vector__XXX
 SG_ TS_MomRad_verfuegb_maxReku_Summe : 26|12@1+ (3,-12279) [-12279|0] ""  Vector__XXX
 SG_ TS_MomRad_Ist : 38|13@1+ (3,-12279) [-12279|12279] "Unit_None"  Vector__XXX
 SG_ TS_MomRad_Ist_sek : 51|13@1+ (3,-12279) [-12279|12279] "Unit_None"  E_Sound,ISE

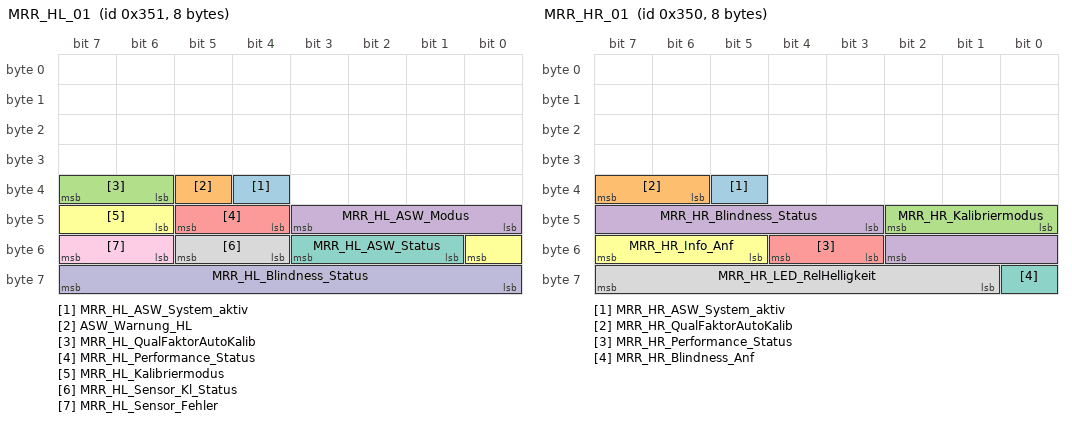
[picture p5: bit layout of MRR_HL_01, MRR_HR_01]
BO_ 849 MRR_HL_01: 8 MRR_HL
 SG_ MRR_HL_ASW_System_aktiv : 36|1@1+ (1.0,0.0) [0.0|1] ""  Gateway,Gateway_PAG,MRR_HR
 SG_ ASW_Warnung_HL : 37|1@1+ (1.0,0.0) [0.0|1] ""  Gateway,Gateway_PAG,MRR_HR
 SG_ MRR_HL_QualFaktorAutoKalib : 38|2@1+ (1.0,0.0) [0.0|3] ""  Gateway,Gateway_PAG,MRR_HR
 SG_ MRR_HL_ASW_Modus : 40|4@1+ (1.0,0.0) [0.0|15] ""  Gateway,Gateway_PAG,MRR_HR
 SG_ MRR_HL_Performance_Status : 44|2@1+ (1.0,0.0) [0.0|3] ""  Gateway,Gateway_PAG,MRR_HR
 SG_ MRR_HL_Kalibriermodus : 46|3@1+ (1.0,0.0) [0.0|7] ""  Gateway,Gateway_PAG,MRR_HR
 SG_ MRR_HL_ASW_Status : 49|3@1+ (1.0,0.0) [0.0|7] ""  Gateway,Gateway_PAG,MRR_HR
 SG_ MRR_HL_Sensor_Kl_Status : 52|2@1+ (1.0,0.0) [0.0|3] ""  Gateway,Gateway_PAG,MRR_HR
 SG_ MRR_HL_Sensor_Fehler : 54|2@1+ (1.0,0.0) [0.0|3] ""  Gateway,Gateway_PAG,MRR_HR
 SG_ MRR_HL_Blindness_Status : 56|8@1+ (1,0) [0|255] "Unit_None"  Gateway,Gateway_PAG,MRR_HR

BO_ 2463978596 MRR_HL_Info: 8 MRR_HL
 SG_ MRR_HL_Info1 : 0|32@1+ (1,0) [1|4294967295] "Unit_None"  MRR_HR

BO_ 848 MRR_HR_01: 8 MRR_HR
 SG_ MRR_HR_ASW_System_aktiv : 37|1@1+ (1.0,0.0) [0.0|1] ""  MRR_HL
 SG_ MRR_HR_QualFaktorAutoKalib : 38|2@1+ (1.0,0.0) [0.0|3] ""  MRR_HL
 SG_ MRR_HR_Kalibriermodus : 40|3@1+ (1.0,0.0) [0.0|7] ""  MRR_HL
 SG_ MRR_HR_Blindness_Status : 43|8@1+ (1,0) [0|255] "Unit_None"  MRR_HL
 SG_ MRR_HR_Performance_Status : 51|2@1+ (1.0,0.0) [0.0|3] ""  MRR_HL
 SG_ MRR_HR_Info_Anf : 53|3@1+ (1.0,0.0) [0.0|7] ""  MRR_HL
 SG_ MRR_HR_Blindness_Anf : 56|1@1+ (1.0,0.0) [0.0|1] ""  MRR_HL
 SG_ MRR_HR_LED_RelHelligkeit : 57|7@1+ (1,0) [0|127] "Unit_None"  MRR_HL

BO_ 1696 NightVision_01: 8 NightVision
 SG_ NV_aktiv : 12|1@1+ (1.0,0.0) [0.0|1] ""  Gateway,Gateway_PAG
 SG_ NV_Texte : 13|3@1+ (1.0,0.0) [0.0|7] ""  Gateway,Gateway_PAG
 SG_ NV_Gong : 16|2@1+ (1.0,0.0) [0.0|3] ""  Gateway,Gateway_PAG
 SG_ NV_Symbol : 18|1@1+ (1.0,0.0) [0.0|1] ""  Gateway,Gateway_PAG
 SG_ NV_Hinweise : 19|2@1+ (1.0,0.0) [0.0|3] ""  Gateway,Gateway_PAG
 SG_ NV_Piktogramm_aktiv : 21|1@1+ (1.0,0.0) [0.0|1] ""  Gateway,Gateway_PAG
 SG_ NV_Akustik_deaktiviert_Icon : 22|1@1+ (1.0,0.0) [0.0|1] ""  Gateway,Gateway_PAG
 SG_ NV_FGM_deaktiviert_Icon : 23|1@1+ (1.0,0.0) [0.0|1] ""  Gateway,Gateway_PAG
 SG_ NV_Markierungslicht_links : 24|1@1+ (1.0,0.0) [0.0|1] ""  Gateway,Gateway_PAG
 SG_ NV_Markierungslicht_rechts : 25|1@1+ (1.0,0.0) [0.0|1] ""  Gateway,Gateway_PAG
 SG_ NV_Symbol_Tierwarnung : 26|1@1+ (1.0,0.0) [0.0|1] ""  Gateway,Gateway_PAG
 SG_ NV_Anf_Prefill : 27|1@1+ (1.0,0.0) [0.0|1] ""  Gateway,Gateway_PAG
 SG_ NV_HBA_Parameter : 28|2@1+ (1.0,0.0) [0.0|3] ""  Gateway,Gateway_PAG
 SG_ NV_LED_Leiste : 30|2@1+ (1.0,0.0) [0.0|3] ""  Gateway,Gateway_PAG
 SG_ NV_PreSense_Status : 32|2@1+ (1.0,0.0) [0.0|3] ""  Gateway,Gateway_PAG
 SG_ NV_PreSense_Modus_System : 34|1@1+ (1.0,0.0) [0.0|1] ""  Gateway,Gateway_PAG
 SG_ NV_PreSense_Modus_Warnung : 35|3@1+ (1.0,0.0) [0.0|7] ""  Gateway,Gateway_PAG
 SG_ NV_FAS_Fkt_Status : 38|2@1+ (1.0,0.0) [0.0|3] ""  Gateway,Gateway_PAG
 SG_ NV_Akt_Status_MMI : 40|2@1+ (1.0,0.0) [0.0|3] ""  Gateway,Gateway_PAG
 SG_ NV_AnforderungBildaufschaltung : 42|1@1+ (1.0,0.0) [0.0|1] ""  Gateway,Gateway_PAG

BO_ 2600468496 NMH_Gateway: 8 Gateway
 SG_ NM_Gateway_SNI : 0|8@1+ (1.0,0.0) [0.0|255] ""  E_Sound,ISE,MRR_HL,MRR_HR,NightVision,RDK,SCR,STH_MLBevo,TopView
 SG_ NM_Gateway_CBV_AWB : 12|1@1+ (1.0,0.0) [0.0|1] ""  Vector__XXX
 SG_ NM_Gateway_CBV_CRI : 14|1@1+ (1.0,0.0) [0.0|1] ""  E_Sound,ISE,MRR_HL,MRR_HR,NightVision,RDK,SCR,STH_MLBevo,TopView
 SG_ NM_Gateway_NM_State : 16|6@1+ (1.0,0.0) [0.0|63] ""  Vector__XXX
 SG_ NM_Gateway_Car_Wakeup : 22|1@1+ (1.0,0.0) [0.0|1] ""  Vector__XXX
 SG_ NM_Gateway_UDS_CC : 23|1@1+ (1.0,0.0) [0.0|1] ""  Vector__XXX
 SG_ NM_Gateway_NM_aktiv_KL15 : 24|1@1+ (1.0,0.0) [0.0|1] ""  Vector__XXX
 SG_ NM_Gateway_NM_aktiv_Diagnose : 25|1@1+ (1.0,0.0) [0.0|1] ""  Vector__XXX
 SG_ NM_Gateway_NM_aktiv_Tmin : 26|1@1+ (1.0,0.0) [0.0|1] ""  Vector__XXX
 SG_ NM_Gateway_NM_aktiv_CWU : 27|1@1+ (1.0,0.0) [0.0|1] ""  Vector__XXX
 SG_ NM_Gateway_NM_aktiv_FC : 28|1@1+ (1.0,0.0) [0.0|1] ""  Vector__XXX
 SG_ NM_Gateway_NM_aktiv_Connect : 29|1@1+ (1.0,0.0) [0.0|1] ""  Vector__XXX
 SG_ NM_Gateway_NM_aktiv_EM : 30|1@1+ (1.0,0.0) [0.0|1] ""  Vector__XXX
 SG_ NM_Gateway_NM_aktiv_OBDC : 31|1@1+ (1.0,0.0) [0.0|1] ""  Vector__XXX
 SG_ NM_Gateway_NM_aktiv_Buskopplung : 32|1@1+ (1.0,0.0) [0.0|1] ""  Vector__XXX
 SG_ NM_Gateway_NM_aktiv_LIN2 : 33|1@1+ (1.0,0.0) [0.0|1] ""  Vector__XXX
 SG_ NM_Gateway_NM_aktiv_Fremdladung : 34|1@1+ (1.0,0.0) [0.0|1] ""  Vector__XXX
 SG_ NM_Gateway_CAB : 40|24@1+ (1.0,0.0) [0.0|16777215] ""  E_Sound,ISE,MRR_HL,MRR_HR,NightVision,RDK,SCR,STH_MLBevo,TopView

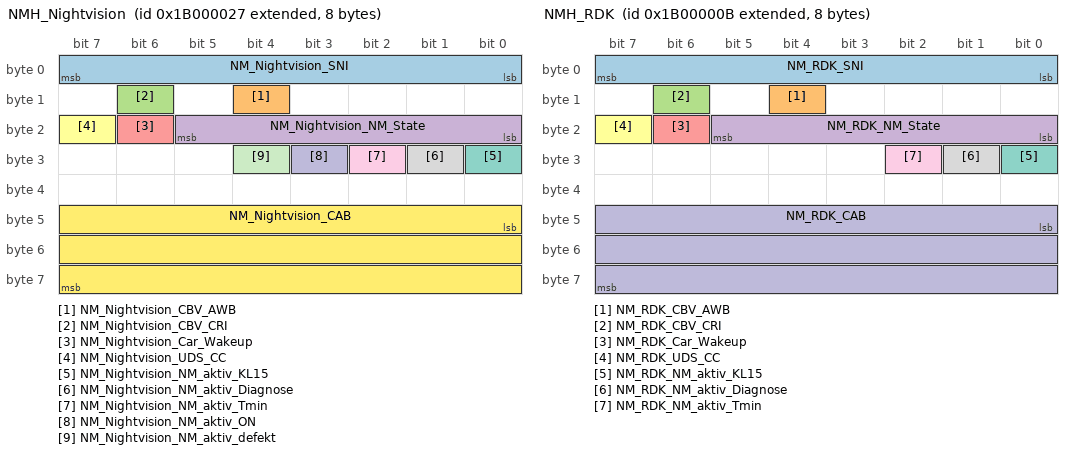
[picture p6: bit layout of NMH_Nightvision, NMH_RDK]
BO_ 2600468519 NMH_Nightvision: 8 NightVision
 SG_ NM_Nightvision_SNI : 0|8@1+ (1.0,0.0) [0.0|255] ""  Gateway,Gateway_PAG,MRR_HL,MRR_HR,RDK,SCR,STH_MLBevo,TopView
 SG_ NM_Nightvision_CBV_AWB : 12|1@1+ (1.0,0.0) [0.0|1] ""  Gateway,Gateway_PAG
 SG_ NM_Nightvision_CBV_CRI : 14|1@1+ (1.0,0.0) [0.0|1] ""  Gateway,Gateway_PAG,MRR_HL,MRR_HR,RDK,SCR,STH_MLBevo,TopView
 SG_ NM_Nightvision_NM_State : 16|6@1+ (1.0,0.0) [0.0|63] ""  Vector__XXX
 SG_ NM_Nightvision_Car_Wakeup : 22|1@1+ (1.0,0.0) [0.0|1] ""  Gateway
 SG_ NM_Nightvision_UDS_CC : 23|1@1+ (1.0,0.0) [0.0|1] ""  Vector__XXX
 SG_ NM_Nightvision_NM_aktiv_KL15 : 24|1@1+ (1.0,0.0) [0.0|1] ""  Vector__XXX
 SG_ NM_Nightvision_NM_aktiv_Diagnose : 25|1@1+ (1.0,0.0) [0.0|1] ""  Vector__XXX
 SG_ NM_Nightvision_NM_aktiv_Tmin : 26|1@1+ (1.0,0.0) [0.0|1] ""  Vector__XXX
 SG_ NM_Nightvision_NM_aktiv_ON : 27|1@1+ (1.0,0.0) [0.0|1] ""  Vector__XXX
 SG_ NM_Nightvision_NM_aktiv_defekt : 28|1@1+ (1.0,0.0) [0.0|1] ""  Vector__XXX
 SG_ NM_Nightvision_CAB : 40|24@1+ (1.0,0.0) [0.0|16777215] ""  Gateway,Gateway_PAG,MRR_HL,MRR_HR,RDK,SCR,STH_MLBevo,TopView

BO_ 2600468491 NMH_RDK: 8 RDK
 SG_ NM_RDK_SNI : 0|8@1+ (1.0,0.0) [0.0|255] ""  Gateway,Gateway_PAG,MRR_HL,MRR_HR,NightVision,SCR,STH_MLBevo,TopView
 SG_ NM_RDK_CBV_AWB : 12|1@1+ (1.0,0.0) [0.0|1] ""  Gateway,Gateway_PAG
 SG_ NM_RDK_CBV_CRI : 14|1@1+ (1.0,0.0) [0.0|1] ""  Gateway,Gateway_PAG,MRR_HL,MRR_HR,NightVision,SCR,STH_MLBevo,TopView
 SG_ NM_RDK_NM_State : 16|6@1+ (1.0,0.0) [0.0|63] ""  Vector__XXX
 SG_ NM_RDK_Car_Wakeup : 22|1@1+ (1.0,0.0) [0.0|1] ""  Gateway,Gateway_PAG
 SG_ NM_RDK_UDS_CC : 23|1@1+ (1.0,0.0) [0.0|1] ""  Vector__XXX
 SG_ NM_RDK_NM_aktiv_KL15 : 24|1@1+ (1.0,0.0) [0.0|1] ""  Vector__XXX
 SG_ NM_RDK_NM_aktiv_Diagnose : 25|1@1+ (1.0,0.0) [0.0|1] ""  Vector__XXX
 SG_ NM_RDK_NM_aktiv_Tmin : 26|1@1+ (1.0,0.0) [0.0|1] ""  Vector__XXX
 SG_ NM_RDK_CAB : 40|24@1+ (1.0,0.0) [0.0|16777215] ""  Gateway,Gateway_PAG,MRR_HL,MRR_HR,NightVision,SCR,STH_MLBevo,TopView

BO_TX_BU_ 917 :Gateway,Gateway_PAG;
BO_TX_BU_ 1153 :Gateway,Gateway_PAG;
BO_TX_BU_ 1600 :Gateway,Gateway_PAG;
BO_TX_BU_ 167 :Gateway,Gateway_PAG;
BO_TX_BU_ 168 :Gateway,Gateway_PAG;
BO_TX_BU_ 958 :Gateway,Gateway_PAG;
BO_TX_BU_ 1648 :Gateway,Gateway_PAG;
BO_TX_BU_ 1010 :Gateway,Gateway_PAG;
BO_TX_BU_ 289 :Gateway,Gateway_PAG;
BO_TX_BU_ 815 :Gateway,Gateway_PAG;
BO_TX_BU_ 1423 :Gateway,Gateway_PAG;
BO_TX_BU_ 340 :Gateway,Gateway_PAG;
BO_TX_BU_ 1601 :Gateway,Gateway_PAG;
BO_TX_BU_ 305 :Gateway,Gateway_PAG;
BO_TX_BU_ 394 :Gateway,Gateway_PAG;
BO_TX_BU_ 234 :Gateway,Gateway_PAG;
BO_TX_BU_ 2600468496 :Gateway,Gateway_PAG;
CM_ BO_ 917 "MLB";
CM_ BO_ 1600 "ab MQB mit QBit Höheneinfo und MO_Versionsinfo_02";
CM_ BO_ 168 "Teil 2 neue Momentenschnittstelle MLB";
CM_ BO_ 1648 "Kombischnittstelle";
CM_ BO_ 1010 "SCR-Schnittstelle";
CM_ BO_ 1423 "CAN-Botschaft";
CM_ BO_ 1601 "ab MQB mit CRC-8";
CM_ BO_ 1696 "MLBevo ohne KD-Bit";
CM_ BO_ 2600468519 "CAN_NM_PDU MLBevo";

CM_ SG_ 917 AFS_Abbiegelicht_Dimm_Anf "Beschreibt ob das Abbiegelicht gedimmt oder hart einschalten werden soll. Dimmkurve ist Empfänger hinterlegt.";
CM_ SG_ 917 AFS_Abbiegelicht_li_Anf "Anforderung das Abbiegelicht links einzuschalten";
CM_ SG_ 917 AFS_Abbiegelicht_re_Anf "Anforderung das Abbiegelicht rechts einzuschalten";
CM_ SG_ 917 AFS_adaptive_LV_verbaut "Verfügbarkeit der adaptiven Lichtverteilung im AFS-SG.
(Das BCM steuert mit diesem Signal die Einblendung des entsprechenden Menüs)";
CM_ SG_ 917 AFS_Allwetterlicht "Status ¿Allwetterlicht¿ - Licht für schlechte Sichtverhältnisse
(bei Defekt -> nicht aktiv)";
CM_ SG_ 917 AFS_Charisma_FahrPr "MLBevo: Aktuelles Fahrprogramm des Charisma-Teilnehmers (siehe Systemlastenheft Drive Select)
MQB: Istwert der Kennlinie (siehe Systemlastenheft MQB FPA)";
CM_ SG_ 917 AFS_Charisma_Status "Charisma Systemstatus des Charisma-Teilnehmers

Wert 0x3 ist nur für Fahrzeuge ab MQB relevant";
CM_ SG_ 917 AFS_Charisma_Umschaltung "Erkennung  Umschaltaufforderung des Charisma-Teilnehmers";
CM_ SG_ 917 AFS_Ersatzlicht_Links "Bei aktivierter Ersatzlichtfunktion wird das Abblendlicht ausgeschaltet und eine Ersatzlichtquelle eingeschaltet (z.Zt. B7)";
CM_ SG_ 917 AFS_Ersatzlicht_Rechts "Bei aktivierter Ersatzlichtfunktion wird das Abblendlicht ausgeschaltet und eine Ersatzlichtquelle eingeschaltet (z.Zt. B7)";
CM_ SG_ 917 AFS_Fehlertext "Fehlertext wird im Kombi angezeigt (z.Zt nur bei VW)";
CM_ SG_ 917 AFS_Fernlicht_li_defekt "Beschreibt ob das Fernlicht des linken Scheinwerfers defekt ist";
CM_ SG_ 917 AFS_Fernlicht_re_defekt "Beschreibt ob das Fernlicht des rechten Scheinwerfers defekt ist";
CM_ SG_ 917 AFS_Fernlicht_Status "Beschreibt ob das Fernlicht aktiv oder inaktiv ist";
CM_ SG_ 917 AFS_Lampe "Status der Fehlerlampe: aktuell anliegender Fehlerzustand des dynamischen oder statischen Kurvenlichtes";
CM_ SG_ 917 AFS_LED_Blinkmode "Lampe soll im Warnfall mit 1Hz blinken, wenn das Bit gesetzt ist (z.Zt nur bei VW)";
CM_ SG_ 917 AFS_Status_adaptive_LV "Gibt den Status der adaptiven Lichtverteilung an";
CM_ SG_ 917 AFS_Verfuegbarkeit_GLW "Beschreibt die Verfügbarkeit der Gleitenden Leuchtweite / Fernlichtassistenz - Verfügbarkeit bedeutet, dass die Funktion Gleitende Leuchtweite möglich ist";
CM_ SG_ 917 GLW_Sensor_blockiert "Das Signal zeigt an, dass die Kamera zur Zeit keine Sicht hat. 
Verhalten wie Fernlichassisten. 
Weiterleitung des Signals vom BCM an das KOMBI";
CM_ SG_ 917 LWR_AFS_Grundeinstellung "Grundeinstellung des Abblendlichtes am Lichteinstellkasten im Service oder Bandende mit Tester erfolgt! (auch für das dynamische Kurvernlicht)";
CM_ SG_ 917 LWR_AFS_Parametrisierung "Parametrisierung wählt die Fahrzeugvariante und die AFS-Variante aus";
CM_ SG_ 917 LWR_Hoehenwert_HL "Aktueller Höhensensorwert Hinten Links
MSS LB überträgt den Aktueller Höhensensorwert Vorne Rechts.

0x7F = 0 mm";
CM_ SG_ 917 LWR_Hoehenwert_VL "Aktueller Höhensensorwert Vorne Links

0x7F = 0 mm";
CM_ SG_ 917 LWR_Initialisierungslauf "Initialisierungslauf der Schrittmotoren, erfolgt defaultmäßig beim Motorstart";
CM_ SG_ 917 LWR_Lampe "Status der Fehlerlampe: aktuell anliegender Fehlerzustand";
CM_ SG_ 917 LWR_Modus "Schnelle oder langsame Regelart der LWR";
CM_ SG_ 917 LWR_Pos_Schrittmotor "Position des Aktuators in Prozent des maximalen Stellweges; vor dem Initialisierungslauf (Motorstart) wird der Initwert ausgegeben: 
0% : tiefste Stellung (auf Block) des Schrittmotors;
100% : maximaler Verstellweg des Schrittmotors (nicht die Grenze de";
CM_ SG_ 917 LWR_Reisemodus_Texte "Anzeige der eingestellten Verkehrsart bei aktivem Touristenlicht";
CM_ SG_ 917 LWR_Sicherheitsposition_li "Rechter Scheinwerfer in Sicherheitsposition.";
CM_ SG_ 917 LWR_Sicherheitsposition_re "Rechter Scheinwerfer in Sicherheitsposition.";
CM_ SG_ 917 LWR_Touristenmodus_aktiv "Über MMI sendet BCM1 eine Anforderung Touristenmodus an die LWR. Diese sendet als Rückmeldung an BCM1, dass der Touristenmodus aktiv geschaltet wurde";
CM_ SG_ 917 LWR_Touristenmodus_verbaut "Verfügbarkeit der Touristenfunktion im AFS/LWR-SG.
(Das BCM steuert mit diesem Signal die Einblendung des entsprechenden Menüs)";

CM_ SG_ 1153 DSSS_Warning "DSSS - Driving Safety Support System Meldungen";
CM_ SG_ 1153 MIB_Tongenerator_PH_verfuegbar "Verfügbarkeit des Tongenerators im MIB für die Nutzung durch die Parkhilfe";
CM_ SG_ 1153 MMI_Counter_Bedienevent "Signal wird inkrementiert, wenn Bedienevent stattgefunden hat.";
CM_ SG_ 1153 MMI_Gauges_active "Signal sent from Main Unit to Kombi instrument to give the display status of the additional gauges in the rotating display";
CM_ SG_ 1153 MMI_Gurt_Mic_ref "Referenzsignal für das Gurtmikrofon Steuergerät zur Signalisierung ob der Downlink aktiv oder inaktiv ist";
CM_ SG_ 1153 MMI_SDS_aktiv "Signal wird gesetzt, solange die Sprachbedienung aktiv ist.";
CM_ SG_ 1153 MMI_StartStopp_Info "Stopp-Freigabe und Start-Anforderung an den Start-Stopp-Koordinator
Signal gilt nur für MHEV12V im MLBevo, Stoppverbot darf nur bei Ausstattungsvariante mit 3D-Sound verwendet werden.";
CM_ SG_ 1153 MU_SecondDisplay "Dient zur Überwachung der zweiten LVDS Leitung.";
CM_ SG_ 1153 MU_Update_Time "Ermöglicht auslesen der Historiendaten, wann ein Update lief";
CM_ SG_ 1153 Nav_FoD_Status "FoD Status der Navigation";
CM_ SG_ 1153 ZR_Kindersicherung_RSE "Sperren der Rearseat Unit (Komplette Weckfähigkeit)";
CM_ SG_ 1153 ZR_LAPP_Sondermodus_Status "Statusrückmeldung zum ZR Sondermodus (BT Abschaltung)";
CM_ SG_ 1153 ZR_LoGeWa_Event_Kombiwarnung "Event für Kombiwarnung";
CM_ SG_ 1153 ZR_MXB_Manoever_Ansage "Übertragung der aktuellen Manöver-Ansage für MatrixBeam. Dient zur Veränderung des Lichtbilds abhängig von Navigationsmanövern.";
CM_ SG_ 1153 ZR_Parken_Sondermodus "Rückkanal zum pilotierten Parken zur Signalisierung Status Sondermodus";
CM_ SG_ 1153 ZR_RSE_aktivieren "Weckfähigkeit der RSE";
CM_ SG_ 1153 ZR_Rundenbewertung "Bewertung einer aktuellen Runde (langsamer, gleich schnell, schneller)";
CM_ SG_ 1153 ZR_Rundenfortschritt "Verhältnis von gefahrener Strecke in einer aktuellen Runde zur Länge einer Referenzrunde in Prozent";
CM_ SG_ 1153 ZR_Sta_Inszenierung "MIB sendet Status über Inszenierungssound (welcome sound) an BCM1
Zweck: Synchronisierung mit weiteren Teilnehmern der Startupinszenierung";

CM_ SG_ 1600 MO_Absperrventil_oeffnen "Signal an Klima-SG das Absperrrventil anzusteuern. Ab D4 auch 0x3 Ventil_schließen.

Im MQB wird hier der Soll-Status des Absperrventils ausgegeben.
Achtung: bei z. B. klemmendem Ventil entspricht das Signal nicht dem tatsächlichen Status!";
CM_ SG_ 1600 MO_aktives_Getriebeheizen "Information für Getriebe, ob ein Ventil für Getriebheizen angesteuert werden muss";
CM_ SG_ 1600 MO_Ansaugluft_Temp "In Fahrzeugen ohne Außentemperatur vom Kombi kann aus der Ansauglufttemperatur auf die Außentemperatur geschlossen werden. Beim SDI ist das mit einer gewissen Genauigkeit gegeben. Genutzt wird es vom ASG.";
CM_ SG_ 1600 MO_Getriebe_kuehlen "Anforderung Getriebekühlventilansteuerung";
CM_ SG_ 1600 MO_Heizungspumpenansteuerung "Anforderung Heizungspumpenansteuerung
MQB und Hybrid: Status der Heizungsunterstützungspumpe am MSG
";
CM_ SG_ 1600 MO_Hoeheninfo "Korrekturfaktor Höhe (1 entspricht 1013 mbar)";
CM_ SG_ 1600 MO_HYB_Fehler_HV_Netz "Im HV-Bordnetz ist fehlerbedingt kein generatorischer Betrieb möglich. Das 12V-Bordnetz wird über den DC/DC-Wandler allein aus der Traktionsbatterie gespeist. Um diesen Zustand möglichst lange aufrechterhalten zu können, sollten Komfort-Verbraucher abgesc";
CM_ SG_ 1600 MO_Kennfeldk "Die Kennfeldkühlung ist in diesem Fahrzeug verbaut und hat keinen Systemfehler";
CM_ SG_ 1600 MO_KL15_Abschaltempfehlung "Kessy Abschaltempfehlung nach Verlassen des Fahrzeugs";
CM_ SG_ 1600 MO_Kuehlmittel_Temp "Kuehlmitteltemperatur";
CM_ SG_ 1600 MO_Mom_Traegheit_02 "Massenträgheit (J) der Motors bzw. der Antriebsmaschinen in kgm².

Zur Berücksichtigung des E-Motor in Hybrid-Projekten:
in MLB-Projekten wird nur der J-Wert des Verbrennungsmotors und nicht der J-Wert des E-Motors berücksichtigt.
In MQB/MLBevo-Projek";
CM_ SG_ 1600 MO_Nachlaufzeit_Heizungspumpe "Nachlaufzeit für Heizungspumpe für Turboladerschutz";
CM_ SG_ 1600 MO_Oel_Temp "Realer Meßbereich ca. -40..150 Grad";
CM_ SG_ 1600 MO_QBit_Ansaugluft_Temp "
";
CM_ SG_ 1600 MO_QBit_Hoeheninfo "Qualifizierungsbit der Höheninfo. Gesetzt bei Ersatzwert, Init oder Fehler.";
CM_ SG_ 1600 MO_QBit_Kuehlmittel_Temp "
";
CM_ SG_ 1600 MO_SpannungsAnf "Forderung des Motor-SGs zur Spannungsanhebung";
CM_ SG_ 1600 MO_Versionsinfo_02 "Versioninformation vom Motor zur Steuerung bei inkompatiblen KMatrix-Änderung bzw. Einführung von neuen Funktionen, die in den Empfängern verriegelt werden müssen. Zu jedem Ereignis wird ein fixer Zählerstand zugeordnet, um dem Empfänger die funktionale Ä";

CM_ SG_ 167 MO_erste_Ungenauschwelle "Zusätzliche Ungenauigkeit (zur Grundungenauigkeit). Motormomente ungenau >8% (kleinste Ungenauschwelle)
";
CM_ SG_ 167 MO_Mom_Ist_Summe "Einheitenloser Wert! Faktor in MO_Faktor_Momente_02 in Motor_Code_01 beachten!

Ist-Moment als Summe aus Verbrennungsmotor und E-Motor (bei Hybrid-Konzepten) incl. allen Eingriffen und Korrekturen

In Fahrzeugen mit einer Antriebsachse bzw. mit mechan";
CM_ SG_ 167 MO_Mom_Schub "Einheitenloser Wert! Faktor in MO_Faktor_Momente_02 in Motor_Code_01 beachten!

Moment das sich einstellt, wenn der Fahrer 0% Fahrpedal gibt; bei konventionellen Projekten = alle Verluste (mechanische Reibung und sonstige Verluste) des Verbrennungsmotor";
CM_ SG_ 167 MO_Mom_Soll_gefiltert "Einheitenloser Wert! Faktor in MO_Faktor_Momente_02 in Motor_Code_01 beachten!

MO_Mom_Soll_Roh nach Fahrverhaltensfilter, begrenzt nach oben mit MO_Mom_Begr_dyn, Einrechnung der plausibilisierten Bremsen-Eingriffe; ohne Getriebe-Schalt-Eingriffe, ohne ";
CM_ SG_ 167 MO_Mom_Soll_Roh "Einheitenloser Wert! Faktor in MO_Faktor_Momente_02 in Motor_Code_01 beachten!

Momentenanforderung aus Fahrpedal bzw. von ACC/GRA bzw. aus dem Leerlaufregler (quasistatischer Anteil) bzw. aus Rekuperationsanforderung; keine Begrenzungen, keine Filterun";
CM_ SG_ 167 MO_Mom_Traegheit_Summe "Einheitenloser Wert! Faktor in MO_Faktor_Momente (CAN V6.x) bzw. MO_Faktor_Momente_02 (CAN V7.x) in Motor_Code_01 beachten!

Moment, das zur Beschleunigung der trägen Massen aufgewendet wird bzw. frei wird; Summen aus Anteilen für Verbrennungsmotor und ";
CM_ SG_ 167 MO_QBit_Motormomente "AUDI D4: Zykluszeit: 10ms (siehe Zykluszeit schnell/Cycletime Fast)

Ungenaue Momentenangaben, weil die Momente aus Ersatzwerten berechnet wurden (z.B. HFM ausgefallen). Qualifizierungsbit für die Motormomente.

Achtung:
Reduktion der Zykluszeit Moto";
CM_ SG_ 167 MO_Status_Normalbetrieb_01 "Das Motorsteuergerät sendet das Informationsbit, wenn die Initialisierungsphase des Steuergerätes abgeschlossen ist. Zusätzlich muss die Klemme 15 eingeschalten sein und eine applizierbare Mindestdrehzahlschwelle (Kennlinie in Abh. von der Kühlwassertempe";
CM_ SG_ 167 Motor_11_BZ "Botschaft asynchron geroutet. Zählerwert kann springen.";
CM_ SG_ 167 Motor_11_CRC "Für MLB:
'Berechnung siehe Lastenheft 'Kommunikationsabsicherung für FlexRay und CAN''

Ab MQB und MLBevo:
'Berechnung siehe Lastenheft 'End-to-End Kommunikationsabsicherung''

Endwerte siehe Begleitdokument 'S-PDU Kennungsfolgen'";

CM_ SG_ 168 MO_Drehzahl_01 "Im Fehlerfall wird die Motordrehzahl über die Nockenwellendrehzahl als Ersatzgrösse ausgegeben

Bei Parallelhybrid: Getriebeeingangsdrehzahl (=E-Maschinen Drehzahl)

Hinweis: 
Ehemaliger Fehlerwert 0xFFFF wird senderseitig nicht unterstützt. 
Diesen";
CM_ SG_ 168 MO_Mom_Begr_dyn "Einheitenloser Wert! Faktor in MO_Faktor_Momente (CAN V6.x) bzw. MO_Faktor_Momente_02 (CAN V7.x/V8.x) in Motor_Code_01 beachten!

Bei aktueller Drehzahl kurzfristig (ca. 100..200 ms) max. mögliches Moment (Summe aus Verbrennungsmotor und E-Motor), wird ";
CM_ SG_ 168 MO_Mom_Begr_stat "Einheitenloser Wert! Faktor in MO_Faktor_Momente (CAN V6.x) bzw. MO_Faktor_Momente_02 (CAN V7.x) in Motor_Code_01 beachten!

Bei aktueller Drehzahl quasistationär (nach ca. 3..5 s) max. mögliches Moment (Summe aus max. Moment des Verbrennungsmotors aus ";
CM_ SG_ 168 MO_Mom_neg_verfuegbar "Einheitenloser Wert! Faktor in MO_Faktor_Momente (CAN V6.x) bzw. MO_Faktor_Momente_02 (CAN V7.x) in Motor_Code_01 beachten!

Bei aktueller Drehzahl im nächsten Task (bei CAN-Übertragung z.B. 10ms) tatsächlich verfügbares negatives Moment (Summe aus Verl";
CM_ SG_ 168 MO_Momentenintegral_02 "100  %  entspricht volle Verfügbarkeit aktuell vorhanden. 0 % entspricht Integral bis Limit gefüllt, erhöhender Eingriff kann aktuell nicht berücksichtigt werden oder aufgrund eines Fehlers nicht verfügbar
";
CM_ SG_ 168 MO_QBit_Drehzahl_01 "AUDI D4: Zykluszeit: 10ms (siehe Zykluszeit schnell/Cycletime Fast)

Achtung:
Reduktion der Zykluszeit Motor_03 auf 10ms geplant.
Projektabhängig soll künftig mit 10ms gesendet werden.
Empfänger die in weiteren Konzern-Projekten eingesetzt werden müs";
CM_ SG_ 168 Motor_12_CRC "Für MLB:
'Berechnung siehe Lastenheft 'Kommunikationsabsicherung für FlexRay und CAN''

Ab MQB und MLBevo:
'Berechnung siehe Lastenheft 'End-to-End Kommunikationsabsicherung'

Endwerte siehe Begleitdokument 'S-PDU Kennungsfolgen'";

CM_ SG_ 958 MO_Aussp_Anlass "Das Signal zeigt an, ob die Wiederholstartsperre aktiv ist. D. h. eine Ansteuerung des Anlassers wird auch bei erfüllten Startvoraussetzungen (HS: Interlock betätigt bzw. AT: P/N eingelegt und Bremse betätigt) nicht erfolgen.";
CM_ SG_ 958 MO_BKV_Unterdruckwarnung "Über die Unterdruckwarnung signalisiert das MSG dem ESP, dass kein ausreichender Unterdruck für den BKV zur Verfügung gestellt werden kann.";
CM_ SG_ 958 MO_BLS "Ungefiltertes Rohsignal des Bremslichtschalters, nur wenn HW-Eingang bestückt und ausgewertet wird. Bei Motoren ohne genutzten HW-Eingang wird kein Ersatzwert (bspw. SW-Signal über CAN) ausgegeben!
Bei AUDI muss das Signal wg. Bremslichtfunktion immer be";
CM_ SG_ 958 MO_BMS_NV_Anf_stuetzen "Garantierte Unterstützung des Zusatzspeichers ist erforderlich. Zusatzspeicher muss an das Versorgungsnezt angebunden werden. ";
CM_ SG_ 958 MO_EKlKomLeiRed "Anforderung an die Klimasteuerung, die Leistungsaufnahme des E-Kompressors bei schlechtem SOC und in bestimmten Fahrsituationen zu begrenzen. (Das bereits bestehende Signal 'Klimakompressor aus' als stets umzusetzende Anforderung bleibt unverändert besteh";
CM_ SG_ 958 MO_Ext_E_Fahrt_aktiv "Funktionsrückmeldung zum erw. E-Fahr-Betrieb über Lampe/LED im E-Mode-Taster";
CM_ SG_ 958 MO_Fahrer_bremst "Redundante Bremsinformation vom Motor.

MLB:
AUDI D4: Zykluszeit: 10ms (siehe Zykluszeit schnell/Cycletime Fast)
Im AUDI B8 wird in diesem Bit der Wert der ESP-CAN-Information 'ESP_Fahrer_bremst' ausgegeben.

Achtung:
Reduktion der Zykluszeit Motor";
CM_ SG_ 958 MO_FMAus_aktiv "Das Signal gibt Rückmeldung ob Freilauf Motor aus aktiv ist. Beleibt auch 0km/h (unterhalb der StartStopp Schwelle) weiterhin aktiv.";
CM_ SG_ 958 MO_FMAus_Startvariante "Startvariante beim Motorstart aus der Freilauf-Motor-AUS Phase";
CM_ SG_ 958 MO_Freig_Anlass "Bit wird gesetzt, wenn der Motor beim Automatikstart gestartet werden darf (Motorstillstand, Emissionsmaßnahmen sind erfüllt).";
CM_ SG_ 958 MO_Freig_Reku "Empfehlung des Motor-SG's zur Spannungsabsenkung/-anhebung für den Rekuperationsbetrieb";
CM_ SG_ 958 MO_Freigabe_Segeln "Freigabebit des Segelbetriebs im Getriebe. Bedingt durch bestimmte Diagnosen und Adaptionen des MSGs, die nur im Schub möglich sind, darf nicht jede Schubphase für einen Segelbetrieb genutzt werden. Eine Freigabe bleibt auch außerhalb einer Schubphase bes";
CM_ SG_ 958 MO_Gangposition "MLB:
Stellung des Wählhebels in der Schaltgasse des Handschaltgetriebes.
MLBevo: 
Ausweitung der Bedienung auch auf Automatikgetriebe;
Routing des Signals GE_Fahrstufe: 
1. Position_R (dez. 6) auf MO_Gangposition: Gang_R (dez. 13) wegen Entfall Signa";
CM_ SG_ 958 MO_Handshake_STH "Es gilt: Signalspec MO_Handshake v1.0

Handshake zwischen MSG und STH. Wenn das MSG die EKP aufgrund einer STH-Anforderung ansteuert und kein Fehlereintrag bzgl. EKP/KPE/NDR vorliegt, wird das Bit gesetzt.";
CM_ SG_ 958 MO_HYB_Fahrbereitschaft "Signal steuert u.a. in der Lenkhilfe zusammen mit weiteren Informationen den Modewechsel in den 'Drivemode'
Grüne Anzeige im Kombiinstrument zur Signalisierung der Bereitschaft des Hybridsystems.";
CM_ SG_ 958 MO_HYB_VM_aktiv "0 = VMotor wird nicht aktiv gehalten (nVM < n_min und keine LL-Regelung aktiv)
1 = VMotor aktiv (ab der ersten Einspritzung; gilt auch für Schubbetrieb, wenn VMotor spätestens durch LLRegelung befeuert würde)
Verwendet zur Bestimmung des Ist-Zustandes";
CM_ SG_ 958 MO_Interlock "Das Motorsteuergerät gibt die Information aus, ab wann der Kupplungsschalter durch das Motorsteuergerät als getreten gesehen wird.
Bei Systemen für Start Stopp muss das Interlocksignal für einen Start durch das MSG generiert werden, sobald der Schalthebe";
CM_ SG_ 958 MO_Kickdown "Es gilt: Signalspec MO_Kickdown v1.0";
CM_ SG_ 958 MO_Kl_50 "Klemme 50: Startausführung durch Ritzelstarter

MLB: nicht von allen Motoren gesendet
MQB/MLBevo: gesendet von allen Motoren";
CM_ SG_ 958 MO_Kl_75 "Klemme X
";
CM_ SG_ 958 MO_Klima_Eingr "Eingriffe des Motor bei der Klima";
CM_ SG_ 958 MO_KomFehler_ESP "Anzeige Kommunikationsfehler bei Empfang vom ESP";
CM_ SG_ 958 MO_Konsistenz_Bremsped "MLB:

AUDI D4: Zykluszeit: 10ms (siehe Zykluszeit schnell/Cycletime Fast)
Siehe 'Funktionsspezifikation Bremslichtinfo B8'

Achtung:
Reduktion der Zykluszeit Motor_03 auf 10ms geplant.
Projektabhängig soll künftig mit 10ms gesendet werden.
Empfäng";
CM_ SG_ 958 MO_Kuppl_schalter "MLB:
Das Motorsteuergerät gibt die Information aus, ab wann der Kupplungsschalter durch das Motorsteuergerät als getreten gesehen wird
0x0: Schalter sagt betätigt (Ausgekuppelt)
0x1: Schalter sagt nicht betätigt (Eingekuppelt)

MQB:
Nur Handschalter";
CM_ SG_ 958 MO_Motor_laeuft "Das Motorsteuergerät gibt die Information aus, ab wann der Motor verbrennungsbedingt autark läuft und durch zuschaltbare Nebenaggregate mechanisch belastbar ist (z.B. durch Generator, Klimakompressor, etc.).

Die 'Motor läuft' Information wird ausgegebe";
CM_ SG_ 958 MO_PTC_Status "Status-Rückmeldung vom MSG zum aktuellen PTC-Status (stufiges PTC, Relais am MSG). Bei Ansteuerung eines stufigen PTC durch ein anderes SG beschreibt das Signal die vom MSG freigegebene PTC-Stufe.";
CM_ SG_ 958 MO_QBit_Fahrer_bremst "MLB:
AUDI D4: Zykluszeit: 10ms (siehe Zykluszeit schnell/Cycletime Fast)

Achtung:
Reduktion der Zykluszeit Motor_03 auf 10ms geplant.
Projektabhängig soll künftig mit 10ms gesendet werden.
Empfänger die in weiteren Konzern-Projekten eingesetzt werd";
CM_ SG_ 958 MO_QBit_Gangposition "Qualitätsbit zum Signal MO_Gangposition";
CM_ SG_ 958 MO_QBit_KL_75 "Q - Bit für das KL 75 Signal zur Vermeidung der fehlerhaften Erkennung von Motorstarts. 
Wird auf 1 gesetzt, solange das Motorsteuergerät KL15 = AUS erkannt hat.";
CM_ SG_ 958 MO_Remotestart_Betrieb "Das MSG ist für den Remotestart-Betrieb bereit. Nach Empfang der Motorstartanforderung für RSt-Betrieb durch BCM wird der Fahrzeugmotor gestartet und solange der Motor läuft, bleibt dieses Bit aktiv. Dieses Signal ist nur zur Verwendung durch das BCM zur ";
CM_ SG_ 958 MO_Remotestart_moeglich "Wenn Bit gesetzt, würde das MSG bei entsprechender Anforderung durch das BCM den Remotestartbetrieb einleiten, d.h. das MSG ist remotestartfähig und es liegen aktuell keine relevanten Fehler oder andere Abbruchgründe vor.";
CM_ SG_ 958 MO_Signalquelle_Gangposition "Signalquelle des Signals MO_Gangposition
0: Signalquelle Gangpositionssensor
1: Signalquelle Modellwert (v/n)";
CM_ SG_ 958 MO_StartStopp_Fahrerwunsch "Fahreraktivität Start/Stop";
CM_ SG_ 958 MO_StartStopp_Motorstopp "Motor-Stopp durch Start/Stopp-Koordinator
HYBRID:
Wenn MO_Hybridfahrzeug = 1 gilt:
Verbrennungsmotor durch Hybrid-Koordinator im MSG ausgeschaltet. 
Die definierten Start/Stopp-Signale beziehen sich nur auf den Verbrennungsmotor!";
CM_ SG_ 958 MO_StartStopp_Status "Aktivitätsstatus Start/Stopp-Koordinator
HYBRID:
Wenn MO_Hybridfahrzeug = 1 gilt:
Signal bezieht sich nur auf den Verbrennungsmotor, nicht auf den Hybridantrieb
";
CM_ SG_ 958 MO_StartStopp_Wiederstart "Motorwiederstart durch Start/Stopp-Koordinator
HYBRID:
Wenn MO_Hybridfahrzeug =1 gilt:
Warnung vor Spannungseinbruch beim Zustart des Verbrennungsmotors. 
-nicht relevant, da derzeit kein Start über 12V-Starter geplant-
Dieses Signal wird nur vom Hyb";
CM_ SG_ 958 MO_StartVorauss_erfuellt "Dient der Fallunterscheidung bei ZAT-Betätigung im Zustand 'KL15 ein' (bei nicht gesetztem Signal folgt KL15 aus, bei gesetztem Signal folgt setzen KL50-Anf.)

0: Signal nicht bedient 
1: Voraussetzungen zur Antriebsstrangaktivierung / Startvoraussetzu";
CM_ SG_ 958 MO_Text_Geschw_red "Anforderung an das Kombi die Textmeldung 'Geschwindigkeitsreduzierung' anzuzeigen";
CM_ SG_ 958 MO_Zylinderabschaltung "Status Zylinderabschaltung Motor";
CM_ SG_ 958 Motor_14_CRC "Ab MQB und MLBevo:
'Berechnung siehe Lastenheft 'End-to-End Kommunikationsabsicherung'

Endwerte siehe Begleitdokument 'S-PDU Kennungsfolgen'";

CM_ SG_ 1648 MO1_Freigabe_Info_WFS "WFS-Freigabeinformation";
CM_ SG_ 1648 MO1_Freigabe_Verfallsinfo_WFS "WFS-Freigabeverfallsinformation";
CM_ SG_ 1648 MO1_Sperr_Info_WFS "WFS-Sperrinformation";
CM_ SG_ 1648 MO_Abstellzeit "Abstelldauer nach letztem KL15 aus

Hinweis: 
Ehemaliger Fehlerwert 0xFF wird senderseitig nicht unterstützt. 
Diesen Wert aus Kompatibilitätsgründen nicht neu belegen!";
CM_ SG_ 1648 MO_Abstellzeit_Status "Statusinformation zur Abstellzeit
0: Die dem Status zugeordnete Variable konnte noch nicht berechnet werden. 
1: Die dem Status zugehörige Variable wurde korrekt berechnet. 
2: Der Wert der zugehörigen Variablen ist nur ein Minimalwert. 
3: Der Wert d";
CM_ SG_ 1648 MO_ANC_Kennfeld_Anf "Anforderung ANC Kennfeldumschaltung";
CM_ SG_ 1648 MO_Anzahl_Abgesch_Zyl "Gibt die Anzahl der abgeschalteten Zylinder an. In Übergangszuständen wird der Zielbetriebszustand angezeigt.";
CM_ SG_ 1648 MO_Bremslicht_Reku "Bremslicht (ggf. bei Rekuperation durch E-Motor) wird angesteuert";
CM_ SG_ 1648 MO_Drehzahl_Warnung "Warnhinweis zum Kombi im Fall einer fehlerbehafteten Drehzahlbegrenzung";
CM_ SG_ 1648 MO_EPCL "Die Anforderung der EPC-Lampe vom MSG ans Kombi soll durch das Bus-Signal MO_EPCL gemäß folgender Logik erfolgen:
MO_EPCL = 0 dez -> EPC Lampe aus, kein Text
MO_EPCL = 1 dez -> gelbe EPC-Symbolik, Text „Antrieb: Störung! Bitte Service aufsuchen“
MO_EPC";
CM_ SG_ 1648 MO_Ethanol_BS_Texte "Ethanol Brennstoff-Texte im Kombi

0 = kein Text
1 = E85 Warm_Up
2 = FlexFuel Warnung 3.Stufe (Too cold for ethanol)
3 = Warmfahrempfehlung MQB / FlexFuel Warnung 1.Stufe (Refuel with gasoline)
4 = FlexFuel Warnung 2. Stufe (Refuel with gasoline)
5";
CM_ SG_ 1648 MO_Fahrzeugtyp "Unterscheidet die Fahrzeugtypen bzgl. der Antriebsart";
CM_ SG_ 1648 MO_Fehler_Zylabsch "Fehlerstatus der Funktion Zylinderabschaltung ";
CM_ SG_ 1648 MO_Hybrid_StartStopp_LED "Ansteuerung der Funktions-LED der Hybrid Taste bzw. Start/Stop Deaktivierungstaste.
Der Start/Stopp-Master (derzeit im MSG) (oder ein künftiger Hybrid-Master) soll die Ansteuerung senden.";
CM_ SG_ 1648 MO_max_Ladedruck "maximal möglicher Ladedruck (zur Anpassung des Anzeigebereichs bei absoluter Ladedruckanzeige)";
CM_ SG_ 1648 MO_NMAX_Schaltanzeige "Maximaldrehzahl für Schaltanzeige";
CM_ SG_ 1648 MO_obere_Drehzahlgrenze "obere Drehzahlgrenze des Motors";
CM_ SG_ 1648 MO_StartStopp_PopUp "Das Signal zeigt an, ob der StSt-Status mittels Deaktivierungstaster geändert wurde. Ein Wechsel auf die Werte 01 oder 10 löst im Kombi ein entsprechendes PopUp aus. Bei einem Statuswechsel durch andere Signalquellen (z.B. Charisma, fehlerbedingte Abschal";
CM_ SG_ 1648 MO_Zylabsch_Texte "Zylinderabschaltung mode in Kombi, fuer Zylinderabschaltung";
CM_ SG_ 1648 MO_Zylabsch_Texte_02 "ZAS-Anzeige für den Fahrer im Kombi
0: kein ZAS (generell keinerlei ZAS-Anzeigen)  (Init für nicht ZAS-Motor)
1: ZAS im Vollmotorbetrieb  (Init für ZAS-Motor)
2: ZAS im Abschaltbetrieb: 1 Zyl aktiv
3: ZAS im Abschaltbetrieb: 2 Zyl aktiv
4: ZAS im Abs";

CM_ SG_ 1010 MO_SCR_Dosierpumpe_Soll "Sollwert zur Pumpensteuerung im eingestellten Zustand
Drehzahlregulierung 100% entspricht 4000 1/min
Druckregelung 100% entspricht 10 bar";
CM_ SG_ 1010 MO_SCR_Dosierpumpe_Wartezeit "Zeit nach der bei KL15_AUS das Rücksaugen der Leitung en beginnen soll. Abhängig von der AGA-Temperatur";
CM_ SG_ 1010 MO_SCR_Dosierpumpe_Zustand "In welchen Zustand die  Dosierpumpe geschaltet wird";
CM_ SG_ 1010 MO_SCR_Heizkreis_3 "Heizkreis 3 einschalten";
CM_ SG_ 1010 MO_SCR_Heizkreis_3_Leistung "Sollwert der Heizleistung Tankheizkreis 2";
CM_ SG_ 1010 MO_SCR_Leitungsheizung "Anforderung Leitungsheizung";
CM_ SG_ 1010 MO_SCR_Tankheizkreis_Leistung "der Tankheizer soll Leistungsgeregelt werden";
CM_ SG_ 1010 MO_SCR_Tankheizung "Anforderung Tankheizung";
CM_ SG_ 1010 MO_SCR_Transferpumpe "Ansteuern der Tansferpumpe zum Umpumpen vom Passivtank zum Aktivtank";
CM_ SG_ 1010 Motor_19_BZ "Zähler der von der Applikation inkrementiert wird";

CM_ SG_ 289 MO_Entkopplung_Sollschlupf "MSG fordert von GSG an, das Anfahrelement (Fahr-/Wandlerkupplung) zu entkoppeln; das GSG soll die gesendete Drehzahl als Schlupf einstellen und ggf. die Regler-Parameter umschalten, damit Rucke aus dem Antrieb nicht im Fahrzeug spürbar werden; nutzbar z.B";
CM_ SG_ 289 MO_Fahrpedalgradient "Das Motorsteuergerät besitzt 2 analoge Fahrpedalsignale. Das Signal des ersten Kanals wird alle 4ms abgetastet. Um Bitschwankungen des A/D-Wandler herauszufiltern wird das Signal entjittert. Anschließend wird der Gradient berechnet. Entsprechend der Zyklu";
CM_ SG_ 289 MO_Fahrpedalrohwert_01 "AUDI D4: Zykluszeit: 10ms (siehe Zykluszeit schnell/Cycletime Fast)

Stellung des Fahrpedales (Rohwert, ohne Überlagerung durch GRA-Eingriffe etc.)

Die Funktionen zur Berechung des Fahrpedalrohwerts laufen im 10ms Raster. Der Fahrpedalwert berechnet ";
CM_ SG_ 289 MO_Moment_im_Leerlauf "Fahrerwunschmoment ist minimal: keine Momentenanforderung durch Fahrpedal, ACC oder GRA+; (Das Signal ist unabhängig von Momentenerhöhungen durch Leerlaufregler oder MSR).

AUDI D4: Zykluszeit: 10ms (siehe Zykluszeit schnell/Cycletime Fast)

Achtung:";
CM_ SG_ 289 MO_QBit_Fahrpedalwerte_01 "AUDI D4: Zykluszeit: 10ms (siehe Zykluszeit schnell/Cycletime Fast)

QBit für beide Fahrpedalwerte des Motors (Fahrpedalrohsignal für ESP, EPB, ACC; Fahrpedalwert für Getriebe)

Achtung:
Reduktion der Zykluszeit Motor_03 auf 10ms geplant.
Projektabh";
CM_ SG_ 289 MO_rel_Saugrohrdruck "Der Wert gibt an, um wieviel mbar der Saugrohrdruck unterhalb des Umgebungsdrucks liegt. Überdruck im Saugrohr wird nicht ausgegeben.
0: Saugrohrdruck=Umgebungsdruck";
CM_ SG_ 289 MO_rel_Saugrohrdruck_gem_err "0: mind. eine Modellrechnung wird zur Berechnung des relativen Saugdrucks herangezogen
1: Relativer Saugrohrdruck wird ausschließlich über Messgrößen bestimmt";
CM_ SG_ 289 MO_Schubabschaltung "ESP plausibilisiert Unterdrucksensor nur bei aktiver Schubabschaltung

MLBevo:
Signal wird nur in MLBevo Projekten mit PDKII Getriebe bedient. In allen anderen MLBevo Projekten wird das Signal mit '0' bedient
PDKII berücksichtigt Verzugszeiten, die in";
CM_ SG_ 289 MO_Sig_Fahrpedalgradient "Kennzeichnet das Vorzeichen des Signal 'Fahrpedalgradient'. Die Ausgabe erfolgt nur parallel statisch mit gesendetem Signal: 'Steuerungsbit Fahrpedalgradient' ";
CM_ SG_ 289 MO_Solldrehz_Leerlauf "Leerlaufsolldrehzahl, die im Motor eingestellt ist (Bei Parallelhybrid im E-Fahr-Betrieb Leerlaufsolldrehzahl der E-Maschine). Der Motor paßt aufgrund der Anforderung von anderen Steuergeräten seine Leerlaufsolldrehzahl an, bspw. Kat-Heizen, Anforderung v";
CM_ SG_ 289 MO_StartStopp_StoppVorbereitung "Zeigt allen aktiven Start-/Stoppteilnehmern einen möglichen Motorstopp im Anhaltevorgang an (Empfänger notwendige Vorbereitungen treffen)
Es liegen keine Vetos vor.";
CM_ SG_ 289 MO_temporaere_Fahrerabwesenheit "Das Signal dient zur Signalisierung einer temporären Abwesenheit des Fahrers. In dieser Zeit ist es ihm möglich, sich durch gewisse ¿ im Verlassenskonzept definierte ¿ Fahreraktionen im aktuellen Fahrzyklus zurückzumelden.
Das Signal wird gesetzt, sobald";
CM_ SG_ 289 Motor_20_BZ "Botschaft asynchron geroutet. Zählerwert kann springen.";
CM_ SG_ 289 Motor_20_CRC "Für MLB:
'Berechnung siehe Lastenheft 'Kommunikationsabsicherung für FlexRay und CAN''

Ab MQB und MLBevo:
'Berechnung siehe Lastenheft 'End-to-End Kommunikationsabsicherung'

Endwerte siehe Begleitdokument 'S-PDU Kennungsfolgen'";
CM_ SG_ 289 TSK_a_Soll_gradientenbegrenzt "TSK Sollbeschleunigung für Fahrerassistenzsysteme mit aktiver Längsführung (GRA, ACC, IPA...). Der Wert stellt den ruckbegrenzten Sollwert der TSK-Regelung dar und ist Basis der TSK-Antriebs- und Bremsmomentenvorsteuerung.";

CM_ SG_ 815 MO_Antriebsstrang_Warnung_HS "Status der Fehlerlampen-Ansteuerung und Textausgabe für Fehlerspeichereinträge aus der Kupplungsschutz-Funktion für Handschaltgetriebe.";
CM_ SG_ 815 MO_Anzeige_Betriebsmodus "Info an das Kombi zur Anzeige verschiedener Betriebsmodi";
CM_ SG_ 815 MO_Anzeige_Fahrbereitschaft "Signalisiert dauerhaft an das Kombi, ob die Fahrbereitschaft vorhanden ist (Drehzahlmesser auf READY)";
CM_ SG_ 815 MO_Anzeige_Rekuperation "Signal steht im Kontext zu MO_Anzeige_Verbrauch und wird für die Anzeige des Reku-Bereiches im grafischen Momentanverbrauch verwendet";
CM_ SG_ 815 MO_Anzeige_Verbrauch_oE "Anzeige Verbrauchssignal fürs Kombi. Im Bezug auf Verbrennerbeteiligung. Das Signal ist einheitenlos. Die zugehörige Einheit wird in MO_Anzeige_Verbr_Einheit übertragen.";
CM_ SG_ 815 MO_Boost_aktiv "Anzeige im Kombi ob Boost aktiv ist.
Die Anzeige wird zusätzlich über das Signal MO_Boost_verfuegbar gesteuert.
";
CM_ SG_ 815 MO_Boost_verfuegbar "Anzeige des aktuell verfügbaren Boostpotentials im Kombiinstrument.";
CM_ SG_ 815 MO_Overboost "Nur Turbo. Anzeige eines Overboostpfeils im Kombi während Overboostzustand der Ladedruckregelung.";
CM_ SG_ 815 PEA_Abschalttexte "Das Signal dient dem Anzeigen von Abschalttexten, wenn PEA nicht verfügbar ist";
CM_ SG_ 815 PEA_Ereignisanzeige "Das Signal dient der Anzeige des Hinweisgrundes";
CM_ SG_ 815 PEA_Ereignisanzeige_temporaer "Signal dient zur Steuerung einer TPA Anzeige im Kombi";
CM_ SG_ 815 PEA_Fortschrittsanzeige "Ablaufbalken für PEA-Hinweise";
CM_ SG_ 815 PEA_Hinweis "Aufforderung für Fahrerhandlung durch PEA";
CM_ SG_ 815 PEA_Zielgeschw "Das Signal dient der Anzeige einer Geschwindigkeit eines Geschwindigkeitsereignisses für PEA";
CM_ SG_ 815 PEA_Zielgeschw_Einheit "Einheit der anzuzeigenden Zielgeschwindigkeit für PEA (Prädiktiver Effizienz Assistent)";

CM_ SG_ 1423 FSA_Fehlerpfade_Initialisieren "Aktivierung der Fehlerpfad-Initialisierung  beim FSP Löschen ueber Mode04";
CM_ SG_ 1423 MO_FSA_Sensorheizung "Aktivierung Sensorheizung FSA";
CM_ SG_ 1423 MO_Getriebe_Oelalterung "Prozentualer Alterungswert Getriebeöl";
CM_ SG_ 1423 MO_ITM_Status "Statusinformationen an TME-Steuergerät bzgl. Thermomanagement";
CM_ SG_ 1423 MO_KJS_LLK_Pos_Summe "Aerodynamisch wirksamer Gesamtöffnungswinkel aller Kühlerlüfter- und LLK-Jalousiesteller.

Pos_Frontendverschl_ungenau = 15 zeigt eine Fehlfunktion bzw. unbekannte Position einer oder mehrere Jalousiesteller an.";
CM_ SG_ 1423 MO_Kuehlmittel_Temp_Rohwert "Rohwert Kuehlmitteltemperatur
Das Signal wird derzeit von Diesel-Projekten nicht bedient.";
CM_ SG_ 1423 MO_MMTR_Status "Status des Antriebs zur Funktion Make me track ready";
CM_ SG_ 1423 MO_Oel_Temp_Radsatz "Öltemperatur in PDK Radsatz ";
CM_ SG_ 1423 MO_SABody_PosLe "Öffnungswinkel der Linke Front Diffusor 
(0%= geschlossen, 100% =volle Kühlung)";
CM_ SG_ 1423 MO_SABody_PosRi "Öffnungswinkel der Rechte Front Diffusor 
(0%= geschlossen, 100% =volle Kühlung)";
CM_ SG_ 1423 MO_Tankdruck "Tank Über-/Unterdruck wird für Ansteuerintensität der Treibstoffpumpe der Standheizung benötigt.";

CM_ SG_ 340 MO_Drehzahl_VM "Motordrehzahl des Verbrennungsmotors

für OBD freeze frame

Hinweis: 
Ehemaliger Fehlerwert 0xFFFF wird senderseitig nicht unterstützt. 
Diesen Wert aus Kompatibilitätsgründen nicht neu belegen!";
CM_ SG_ 340 MO_Fehlerstatus_Antrieb_FDR "Fehlerstatus Antrieb - FDR";
CM_ SG_ 340 MO_IstMoment_VKM "Ist-Moment des Verbrennungsmotors

einheitenloser Wert! MO_Faktor_Momente_02 in Motor_Code_01 berücksichtigen!";
CM_ SG_ 340 MO_Mom_Begr_Schalt "Einheitenloser Wert! Faktor in MO_Faktor_Momente (CAN V6.x) bzw. MO_Faktor_Momente_02 (CAN V7.x/8.x) in Motor_Code_01 beachten!

Bei aktueller Drehzahl kurzfristig (ca. 100..200 ms) für momentenerhöhende Getriebeeingriffe max. zur Verfügung stehendes Ge";
CM_ SG_ 340 MO_Mom_Begr_Schalt_Min "Bei aktueller Drehzahl im nächsten Task (im VKM Umsetzung zur nächsten möglichen Verbrennung) minmal stellbares Moment (Summe aus Verbrennungsmotor und E-Motor) aufgrund Momenten-Reduzierungs-Anforderung durch reduzierenden Getriebeeingriff.
Berücksichti";
CM_ SG_ 340 MO_Primaerachse_Anforderung "Das Signal dient der Steuerung der Primärachse. 

Anforderung zum Öffnen/Schließen der Getriebekupplungen und damit An-/Abkuppeln der Primärachse. 
Wird in MHEV-Projekten keine explizite Anforderung gesendet (Wert 0), ist die Freilaufsteuerung aus 'MO_";
CM_ SG_ 340 Motor_28_BZ "Botschaft asynchron geroutet. Zählerwert kann springen.";
CM_ SG_ 340 Motor_28_CRC "Für MLB:
'Berechnung siehe Lastenheft 'Kommunikationsabsicherung für FlexRay und CAN''

Ab MQB und MLBevo:
'Berechnung siehe Lastenheft 'End-to-End Kommunikationsabsicherung''

Endwerte siehe Begleitdokument 'S-PDU Kennungsfolgen'";

CM_ SG_ 1601 MO_Ansaugsystem "Art des Ansaugsystems des Verbrennungsmotors";
CM_ SG_ 1601 MO_Anzahl_Zyl "Zylinderzahl des Verbrennungsmotors";
CM_ SG_ 1601 MO_Anzeige_StSt_gueltig "Zeigt die Gültigkeit der neuen StSt-Anzeigesignale an, MO_Anzeige_StSt_Text und  MO_Anzeige_Symbol. Mo_Text_Motorstart 1..5 sind zu ignorieren.";
CM_ SG_ 1601 MO_Code "Motorcodierinformation Version 16 (Details siehe Anhang)";
CM_ SG_ 1601 MO_DPF_verbaut "Verbauinformation Diesel-Partikel-Filter
";
CM_ SG_ 1601 MO_Faktor_Momente_02 "Dieses Signal schaltet den Wertebereich aller Momente vom Motor, Getriebe, TSK, Bremse ... um! Die Momente besitzen somit einen variablen Wertebereich, weil sich durch den Faktor die Momente sowohl in Auflösung als auch Maximalwerten ändert.

0x0 nicht ";
CM_ SG_ 1601 MO_Getriebe_Code "Getriebecodierung des Motors";
CM_ SG_ 1601 MO_Hubraum "Hubraum des Verbrennungsmotors";
CM_ SG_ 1601 MO_Hybridfahrzeug "Anhand dieses Signals plausibilisiert die Lenkhilfe das Bit Fahrbereitschaft.

Im Projekt Cayenne PHEV (und ggf. auch VW526 PHEV) ist aus Gründen der Abwärtskompatibilität der Wert '2' zu senden.";
CM_ SG_ 1601 MO_Kraftstoffart "Primärkraftstoff zum Antrieb des Fahrzeugs";
CM_ SG_ 1601 MO_Leistung "Nennleistung des Verbrennungsmotors

Im reinen E-Fahrzeug (BEV): Ausgabe der elektrischen Systemleistung";
CM_ SG_ 1601 MO_OBD_Typ "Abgastyp OBD
Hinweis: In Fahrzeugen mit dem Zielmarkt China und einer Zertifizierung ab China 6 muss auf dem Signal 'MO_OBD_Typ' der Wert 'US_OBD' gesendet werden.";
CM_ SG_ 1601 MO_StartStopp_Codiert "Funktion StartStopp im aktuellen Klemmenzyklus verbaut";
CM_ SG_ 1601 Motor_Code_01_CRC "Für MLB:
'Berechnung siehe Lastenheft 'Kommunikationsabsicherung für FlexRay und CAN''

Ab MQB und MLBevo:
'Berechnung siehe Lastenheft 'End-to-End Kommunikationsabsicherung''

Endwerte siehe Begleitdokument 'S-PDU Kennungsfolgen'";
CM_ SG_ 1601 TSK_Codierung "Information über den plausibilisierten Codierungszustand des Triebstrangskoordinators auf ACC oder GRA.";

CM_ SG_ 305 Ladezustand_02 "Aktueller relativer Ladezustand der HV-Batterie
";
CM_ SG_ 305 MO_ePerformance "Zeigt die elektrische Leistungreserve bei BEV und PHEV Projekten an.
Bei Init und Fehler soll keine Anzeige erfolgen. ";
CM_ SG_ 305 MO_ePowermeter "Anzeige ePowermeter (Fahrreserve elektrisch bis Start Verbrennungsmotor (Verbrenner startet bei 100%))";
CM_ SG_ 305 MO_Powermeter "Anzeigewerte im Kombi
0       = Unteres Ende Bremsen/grau;
340   = Unteres Ende CHARGE;
1020 = READY;
1870 = Oberes Ende EFFICIENCY;
3400 = 100%;
4080 = MAX;";
CM_ SG_ 305 MO_Powermeter_Elm "Die Prozentwerte ergeben sich aus dem momentanen Moment der E-Maschine bezogen auf das im aktuellen Arbeitspunkt maximal mögliche Moment der E-Maschine (generatorisch = negativ / motorisch = positiv )";
CM_ SG_ 305 MO_Powermeter_Elm_02 "relatives Moment / relative Leistung der elektrischen Maschine";
CM_ SG_ 305 MO_Zust_Antrieb "Signalisiert die Zuordnung der Antriebsverbräuche zu den Antriebsmaschinen für die Restreichweitenberechnung, nicht gleichbedeutend mit Motorlauf EM oder VM bzw. Brennstoffzelle";
CM_ SG_ 305 MO_Zust_Betriebsstrategie "Signalisiert den aktuellen Zustand der Betriebsstrategie";

CM_ SG_ 394 MO_Ablaufstatus "aktueller Status bezüglich der Ausführung des Sollzustand

detaillierte Beschreibung der einzelnen Übergänge ist in der aktuellsten Version des Lastenhefts 'Funktionslastenheft Betriebsartenkoordination bei elektrifizierten Fahrzeugen_Vxx' zu entnehmen";
CM_ SG_ 394 MO_Ablaufstrg_Betriebszustand "Istzustand Betriebsbereitschaft

1 = Betriebsbereitschaft bedeutet: Alle Komponenten sind betriebsbereit. Fahrzeug kann kein Vortriebsmoment erzeugen.

2 = Fahrbetrieb bedeutet: Fahrzeug kann Vortriebsmoment erzeugen.";
CM_ SG_ 394 MO_Ablaufstrg_Kraftschluss2_Ist "Istzustand des Kraftschlusses der Sekundärachse in der Hybridablaufsteuerung (z.B. el. Hinterachse im B9 eQuattro).
Dieses Signal entspricht nicht einem physikalischen Zustand, sondern den Istzustand der Ablaufsteuerung.

Das Signal darf nur ausgwertet";
CM_ SG_ 394 MO_Ablaufstrg_Kraftschluss2_Ziel "Zielstatus des Kraftschlusses der Sekundärachse in der Hybridablaufsteuerung (z.B. el. Hinterachse im B9 eQuattro).
Mit dem Bit soll das Getriebe Kraftschluss herstellen oder den Kraftschluss unterbrechen.

Das Signal darf nur ausgwertet werden, wenn '";
CM_ SG_ 394 MO_Ablaufstrg_Kraftschluss_Ist "Istzustand des Kraftschlusses in der Hybridablaufsteuerung.
Dieses Signal entspricht nicht einem physikalischen Zustand, sondern den Istzustand der Ablaufsteuerung.

Das Signal darf nur ausgwertet werden, wenn 'MO_Ablaufstrg_Betriebszustand' eine Betri";
CM_ SG_ 394 MO_Ablaufstrg_Kraftschluss_Ziel "Zielstatus des Kraftschlusses in der Hybridablaufsteuerung.
Mit dem Bit soll das Getriebe Kraftschluss herstellen oder den Kraftschluss unterbrechen.

Das Signal darf nur ausgwertet werden, wenn 'MO_Ablaufstrg_Betriebszustand' eine Betriebsbereitschaft";
CM_ SG_ 394 MO_Ablaufstrg_Zustand_K0_Ist "Iststatus der K0 Kupplung in der Hybridablaufsteuerung.
Dieses Signal entspricht nicht einem physikalischen Zustand, sondern den Istzustand der Ablaufsteuerung.

Das Signal darf nur ausgwertet werden, wenn 'MO_Ablaufstrg_Betriebszustand' eine Betriebsb";
CM_ SG_ 394 MO_Ablaufstrg_Zustand_K0_Ziel "Zielstatus der K0 Kupplung in der Hybridablaufsteuerung
K0 Steuerung im Motorsteuergerät:
- Infobit an das Getriebe, dass K0 jetzt geschlossen wird
K0 Steuerung durch anderes Steuergerät:
- Bit um dem anderen SG mitzuteilen, dass dieses die K0 schlies";
CM_ SG_ 394 MO_Ablaufstrg_Zustand_VKM_Ist "Istzustand VKM
Dieses Signal entspricht nicht einem physikalischen Zustand, sondern den Istzustand der Ablaufsteuerung.

Das Signal darf nur ausgewertet werden, wenn 'MO_Ablaufstrg_Betriebszustand' eine Betriebsbereitschaft signalisiert.";
CM_ SG_ 394 MO_Ablaufstrg_Zustand_VKM_Ziel "Zielzustand VKM
Dieses Signal entspricht nicht einem physikalischen Zustand, sondern den Zielzustand der Ablaufsteuerung.

Das Signal darf nur ausgewertet werden, wenn 'MO_Ablaufstrg_Betriebszustand' eine Betriebsbereitschaft signalisiert.";
CM_ SG_ 394 MO_Abstellposition_02 "Winkelabstand (in °KW) des sog. Zielzylinders von seinem ZOT (bspw. nötig um Startmoment bei Schleppstart zu berechnen)

255 = Abstellposition kann nicht genau bestimmt werden (bspw. Rückdrehen des Motors)";
CM_ SG_ 394 MO_Auth_Aufforderung_WFS "WFS-Anforderung für Hybridumfänge";
CM_ SG_ 394 MO_HYB_Adaption_aktiv "Motor fordert Sondermaßnahmen vom Getriebe PDK2 (gültig nur für Hybridprojekte)
Das Signal wird im PDKII dazu verwendet, die Fahrkupplungen bei einem Momentenadaptionswunsch der K0-Trennkupplung nicht zu befüllen";
CM_ SG_ 394 MO_HYB_E_Faktor "Signed Nibble, verwendet vom GSG zur Interpolation zwischen VMKennfeld und dem Rekuperations-Grenzkennfeld (negative Werte des E-Faktors) bzw. dem Boost-Grenzkennfeld (positive Werte des E-Faktors).
0000 = VM-Kennfeld (keine Interpolation)
0001..0111 = ";
CM_ SG_ 394 MO_HYB_EMode_Info "Hybrid-Mode der Motorsteuerung zur Beeinflussung der Schaltkennfelder im Getriebe. Nicht-Hybridfahrzeuge senden den Initwert.";
CM_ SG_ 394 MO_HYB_LowSpeedModus "MSG legt fest:
0 = klassisches Ausrollen/Anfahren mit N_mot >= N_Leerlauf_VM
1 = elektr. Ausrollen/Anfahren mit geschl. Triebstrang mit N_mot < N_Leerlauf_VM";
CM_ SG_ 394 MO_HYB_Stoppmodus "Hybridsteuerung zeigt an, auf welche Weise gestoppt werden soll.";
CM_ SG_ 394 MO_Mom_Freiheit_Sekundaerachse "Signalisiert die Momentenfreiheit der Sekundärachse und ist damit Voraussetzung für das Abkoppeln.";
CM_ SG_ 394 MO_Nachlaufzeit_Kuehlerluefter "Nachlaufzeit Kühlerlüfter MSG für Verwendung im TME SG";
CM_ SG_ 394 MO_Start_Art "Beschreibt Art des Starts näher 

Schlupfstart kann entweder Momentenvorhalt oder Impulsstart sein oder eine Kombination aus beidem.";
CM_ SG_ 394 MO_Start_Dynamik "Zeigt die Start-Variante bzw. Start-Dynamik eines VKM-Starts an";
CM_ SG_ 394 MO_Tankklappensteuerung "Ansteuerungsanforderung der Tankklappe";

CM_ SG_ 234 Motor_TS_03_BZ "Fortlaufender Botschaftszähler";
CM_ SG_ 234 Motor_TS_03_CRC "Für MLB:
'Berechnung siehe Lastenheft 'Kommunikationsabsicherung für FlexRay und CAN''

Ab MQB und MLBevo:
'Berechnung siehe Lastenheft 'End-to-End Kommunikationsabsicherung''

Endwerte siehe Begleitdokument 'S-PDU Kennungsfolgen'";
CM_ SG_ 234 TS_Allrad_Anteil_sek "Vom Antrieb gewünschter prozentualer Anteil der sekundären Antriebsachse am Gesamtmoment";
CM_ SG_ 234 TS_MomRad_Ist "Gesamt-Istmoment der Antriebsmaschinen, umgerechnet auf Radebene, unter Berücksichtigung der Massenträgheiten der Antriebsmaschinen und des Getriebes, unter Berücksichtigung der Verluste der Antriebsmaschinen, der Nebenaggregate und des Getriebes (d.h. ke";
CM_ SG_ 234 TS_MomRad_Ist_sek "Gesamt-Istmoment der Antriebsmaschinen, umgerechnet auf Radebene, unter Berücksichtigung der Massenträgheiten der Antriebsmaschinen und des Getriebes, unter Berücksichtigung der Verluste der Antriebsmaschinen, der Nebenaggregate und des Getriebes.
Zeigt ";
CM_ SG_ 234 TS_MomRad_verfuegb_maxReku_Summe "Im aktuellen Betriebszustand kurzfristig (ca. 100..200 ms) verfügbares max. negatives Summenmoment; definiert auf Bezugsebene Rad.
Faktor in TS_Faktor_Radmomente beachten!";
CM_ SG_ 234 TS_Status_MomRad_Ist "Qualitätsstatus zu TS_MomRad_Ist und TS_MomRad_Ist_Sek
Qualifiziert bei antriebstechnisch getrennten Achsen sowohl das Moment der primären Achse als auch das Moment der sekundären Achse, und bei mechanischem Allradantrieb das Gesamtmoment für beide Achse";

CM_ SG_ 849 ASW_Warnung_HL "Warnung auf der linke Fahrzeugseite";
CM_ SG_ 849 MRR_HL_ASW_Modus "gibt die Verfügbarkeit der ASW Funktion an";
CM_ SG_ 849 MRR_HL_ASW_Status "Funktionstatus";
CM_ SG_ 849 MRR_HL_ASW_System_aktiv "Synchronisierung des Funktionszustands Ausstiegswarnung (ASW) zwischen den Steuergeräten MRR HL und MRR HR";
CM_ SG_ 849 MRR_HL_Blindness_Status "Evaluierung der MRR Blindness Heck-Sensoren";
CM_ SG_ 849 MRR_HL_Kalibriermodus "Aktueller Modus der Autokalibrierung";
CM_ SG_ 849 MRR_HL_Performance_Status "Übertragung der Fehlerzustände im Slave an den Master und umgekehrt";
CM_ SG_ 849 MRR_HL_QualFaktorAutoKalib "Geschätzte Qualität des Faktors der Autokalibrierung";
CM_ SG_ 849 MRR_HL_Sensor_Fehler "Das Signal wird für die Kalibrierung benötigt.";
CM_ SG_ 849 MRR_HL_Sensor_Kl_Status "Vom Sensor erkannter Klemmenstatus";

CM_ SG_ 2463978596 MRR_HL_Info1 "Kompatibilitätcheck";

CM_ SG_ 848 MRR_HR_ASW_System_aktiv "Synchronisierung des Funktionszustands Ausstiegswarnung (ASW) zwischen den Steuergeräten MRR HL und MRR HR";
CM_ SG_ 848 MRR_HR_Blindness_Anf "Triggert die Blindness-Erkennung im Slave.";
CM_ SG_ 848 MRR_HR_Blindness_Status "Evaluierung der MRR Blindness Heck-Sensoren";
CM_ SG_ 848 MRR_HR_Info_Anf "Kompatibilitaetcheck";
CM_ SG_ 848 MRR_HR_Kalibriermodus "Aktueller Modus der Autokalibrierung";
CM_ SG_ 848 MRR_HR_LED_RelHelligkeit "Helligkeit der LEDs";
CM_ SG_ 848 MRR_HR_Performance_Status "Übertragung der Fehlerzustände im Slave an den Master und umgekehrt";
CM_ SG_ 848 MRR_HR_QualFaktorAutoKalib "Geschätzte Qualität des Faktors der Autokalibrierung";

CM_ SG_ 1696 NV_Akt_Status_MMI "Zustand des Nightvison Systems im MMI: Warnalgo & NV-Reiter Ein/Aus

";
CM_ SG_ 1696 NV_aktiv "Nightvision aktiviert (liefert Bild)";
CM_ SG_ 1696 NV_Akustik_deaktiviert_Icon "Ansteuerungssignal für das  Akustik-deaktiviert-Icon";
CM_ SG_ 1696 NV_Anf_Prefill "Anforderung an ESP, dass die Prefill-Funktion aktiviert werden soll.";
CM_ SG_ 1696 NV_AnforderungBildaufschaltung "Automatische Bildaufschaltung im Warnfall";
CM_ SG_ 1696 NV_FAS_Fkt_Status "Signal für FAS Profile-Master";
CM_ SG_ 1696 NV_FGM_deaktiviert_Icon "Ansteuerungssignal für das  Fussgängermarkierung-deaktiviert-Icon";
CM_ SG_ 1696 NV_Gong "Das Signal löst einen Gong des NightVision-Systems im Kombidisplay aus";
CM_ SG_ 1696 NV_HBA_Parameter "Anforderung an ESP, welcher HBA-Parametersatz verwendet werden soll. Die Festlegung der Empfindlichkeitsschwellen der verschiedenen Parametersätze erfolgt mit der Applikation des Gesamtsystems ESP/ACC bzw. des HBA.
Nur Audi B8: Umsetzung der Anforderung ";
CM_ SG_ 1696 NV_Hinweise "Das Signal dient dazu Hinweistexte in das NightVision Bild im Kombiinstrument einzublenden.Die Anzeigedauer der Hinweistexte ist Signalgesteuert. D.h., sie werden angezeigt bis das CAN-Signal s_NV_Texte seinen Wert ändert.";
CM_ SG_ 1696 NV_LED_Leiste "Ansteuerung_LED_Warnleiste";
CM_ SG_ 1696 NV_Markierungslicht_links "Das Signal steuert die Aktivierung des Markierungslicht links bei Fußgängerwarnung";
CM_ SG_ 1696 NV_Markierungslicht_rechts "Das Signal steuert die Aktivierung des Markierungslicht rechts bei Fußgängerwarnung";
CM_ SG_ 1696 NV_Piktogramm_aktiv "Signal sagt, dass das Piktogramm im NightVision-Reiter geändert werden soll";
CM_ SG_ 1696 NV_PreSense_Modus_System "Signal zur Realisierung der BAP-Kommunikation für PreSense";
CM_ SG_ 1696 NV_PreSense_Modus_Warnung "Signal zur Realisierung der BAP-Kommunikation für PreSense";
CM_ SG_ 1696 NV_PreSense_Status "Signal zur Realisierung der BAP-Kommunikation für PreSense";
CM_ SG_ 1696 NV_Symbol "Wenn das NV-System einen Fußgänger findet, fordert es mit dem Signal das HUD auf, ein Symbol zu zeigen";
CM_ SG_ 1696 NV_Symbol_Tierwarnung "Signal zur Anforderung einer Symbolanzeige für Tierwarnung.";
CM_ SG_ 1696 NV_Texte "Angeforderte Textmeldung";

CM_ SG_ 2600468496 NM_Gateway_CAB "CAB = Clusteraktivbits";
CM_ SG_ 2600468496 NM_Gateway_Car_Wakeup "Car Wakeup (Subbusmaster wertet aus)

MQB: 
-Diagnose- oder Komponentenschutzmaster-Funktion weckt den schlafenden Subbus (z.B. MOST)

E3_Volumen:
- Diagnose aktiv -aktive Diagnosekommunikation am OBD-Stecker

MQBw_Baseline:
- Diagnose aktiv -akt";
CM_ SG_ 2600468496 NM_Gateway_CBV_AWB "Das Signal ist zu setzen, wenn das SG aktiv den Bus geweckt hat
0 = Passiver_WakeUp = SG hat das Netzwerk nicht aktiv geweckt
1 = Akitiver_WakeUp = SG hat das Netzwerk aktiv geweckt";
CM_ SG_ 2600468496 NM_Gateway_CBV_CRI "Das Signal ist dauerhaft gesetzt, wenn das NM-Layout Cluster- Anforderungen enthält";
CM_ SG_ 2600468496 NM_Gateway_NM_aktiv_Buskopplung "Nachlauf aufgrund Kopplung zweier Busse. z.B. K-CAN und K2-CAN";
CM_ SG_ 2600468496 NM_Gateway_NM_aktiv_Connect "Nachlauf aufgrund Connect";
CM_ SG_ 2600468496 NM_Gateway_NM_aktiv_CWU "Nachlauf aufgrund CWU Anforderung";
CM_ SG_ 2600468496 NM_Gateway_NM_aktiv_Diagnose "Diagnose befindet sich nach VW80124 in einer NonDefaultDiagnostic-Session, z.B. ExtendedDiagnostic-Session";
CM_ SG_ 2600468496 NM_Gateway_NM_aktiv_EM "Nachlauf aufgrund Energiemanagement";
CM_ SG_ 2600468496 NM_Gateway_NM_aktiv_FC "Nachlauf aufgrund Funktionscluster Anforderung";
CM_ SG_ 2600468496 NM_Gateway_NM_aktiv_Fremdladung "Nachlauf aufgrund Fremdladung";
CM_ SG_ 2600468496 NM_Gateway_NM_aktiv_KL15 "Steuergerät hat KL15-EIN erkannt";
CM_ SG_ 2600468496 NM_Gateway_NM_aktiv_LIN2 "Bus aktiv aufgrund aktivem LIN2 (Hupe betätigt)";
CM_ SG_ 2600468496 NM_Gateway_NM_aktiv_OBDC "Nachlauf aufgrund OBDC";
CM_ SG_ 2600468496 NM_Gateway_NM_aktiv_Tmin "Mindestaktivzeit ist noch nicht abgelaufen (bei jedem Weckereignis wird die Mindestaktivzeit neu gestartet)";
CM_ SG_ 2600468496 NM_Gateway_NM_State "1 = Zustand Repeat Message (<-- Bus-Sleep Mode)
2 = Zustand Repeat Message (<-- Prepare Bus-Sleep Mode)
4 = Zustand Normal Operation (<-- Repeat Message)
8 = Zustand Normal Operation (<-- Ready Sleep)";
CM_ SG_ 2600468496 NM_Gateway_SNI "Source Node-Identifier (SNI) identifiziert den Sender der NM-Botschaft (Knotenadresse) eindeutig im Fahrzeug";
CM_ SG_ 2600468496 NM_Gateway_UDS_CC "Funktionseinschränkung aufgrund aktivem UDS-Communication Control, siehe VW80124";

CM_ SG_ 2600468519 NM_Nightvision_CAB "CAB = Clusteraktivbits";
CM_ SG_ 2600468519 NM_Nightvision_Car_Wakeup "Car Wakeup (Gateway wertet aus)";
CM_ SG_ 2600468519 NM_Nightvision_CBV_AWB "Das Signal ist zu setzen, wenn das SG aktiv den Bus geweckt hat";
CM_ SG_ 2600468519 NM_Nightvision_CBV_CRI "Das Signal ist dauerhaft gesetzt, wenn das NM-Layout dem neuen NM-Layout für Teilnetzbetrieb entspricht";
CM_ SG_ 2600468519 NM_Nightvision_NM_aktiv_defekt "NV hat Fehler erkannt der zu einer Kombimeldung führt";
CM_ SG_ 2600468519 NM_Nightvision_NM_aktiv_Diagnose "Diagnose befindet sich nach VW80124 in einer NonDefaultDiagnostic-Session, z.B. ExtendedDiagnostic-Session";
CM_ SG_ 2600468519 NM_Nightvision_NM_aktiv_KL15 "Steuergerät hat KL15-EIN erkannt";
CM_ SG_ 2600468519 NM_Nightvision_NM_aktiv_ON "Nightvision ist aktiviert";
CM_ SG_ 2600468519 NM_Nightvision_NM_aktiv_Tmin "Mindestaktivzeit ist noch nicht abgelaufen (bei jedem Weckereignis wird die Mindestaktivzeit neu gestartet)";
CM_ SG_ 2600468519 NM_Nightvision_NM_State "1 = Zustand Repeat Message (<-- Bus-Sleep Mode)
2 = Zustand Repeat Message (<-- Prepare Bus-Sleep Mode)
4 = Zustand Normal Operation (<-- Repeat Message)
8 = Zustand Normal Operation (<-- Ready Sleep)
16 = Zustand Repeat Message (<-- Ready Sleep)
32 ";
CM_ SG_ 2600468519 NM_Nightvision_SNI "Source Node-Identifier (SNI) identifiziert den Sender der NM-Botschaft (Knotenadresse) eindeutig im Fahrzeug";
CM_ SG_ 2600468519 NM_Nightvision_UDS_CC "Funktionseinschränkung aufgrund aktivem UDS-Communication Control; siehe VW80124";

CM_ SG_ 2600468491 NM_RDK_CAB "CAB = Clusteraktivbits";
CM_ SG_ 2600468491 NM_RDK_Car_Wakeup "Car Wakeup (Gateway wertet aus)";
CM_ SG_ 2600468491 NM_RDK_CBV_AWB "Das Signal ist zu setzen, wenn das SG aktiv den Bus geweckt hat";
CM_ SG_ 2600468491 NM_RDK_CBV_CRI "Das Signal ist dauerhaft gesetzt, wenn das NM-Layout Cluster- Anforderungen enthält";
CM_ SG_ 2600468491 NM_RDK_NM_aktiv_Diagnose "Diagnose befindet sich nach VW80124 in einer NonDefaultDiagnostic-Session, z.B. ExtendedDiagnostic-Session";
CM_ SG_ 2600468491 NM_RDK_NM_aktiv_KL15 "Steuergerät hat KL15-EIN erkannt";
CM_ SG_ 2600468491 NM_RDK_NM_aktiv_Tmin "Mindestaktivzeit ist noch nicht abgelaufen (bei jedem Weckereignis wird die Mindestaktivzeit neu gestartet)";
CM_ SG_ 2600468491 NM_RDK_NM_State "1 = Zustand Repeat Message (<-- Bus-Sleep Mode)
2 = Zustand Repeat Message (<-- Prepare Bus-Sleep Mode)
4 = Zustand Normal Operation (<-- Repeat Message)
8 = Zustand Normal Operation (<-- Ready Sleep)";
CM_ SG_ 2600468491 NM_RDK_SNI "Source Node-Identifier (SNI) identifiziert den Sender der NM-Botschaft (Knotenadresse) eindeutig im Fahrzeug";
CM_ SG_ 2600468491 NM_RDK_UDS_CC "Funktionseinschränkung aufgrund aktivem UDS-Communication Control, siehe VW80124";
BA_DEF_REL_ BU_SG_REL_  "GenSigTimeoutTime" INT 0 65535;
BA_DEF_ BO_  "DiagRequest" ENUM "No", "Yes";
BA_DEF_ BO_  "DiagResponse" ENUM "No", "Yes";
BA_DEF_ BO_  "DiagState" ENUM "No", "Yes";
BA_DEF_ BO_  "GenMsgChkConstant" HEX 0 4095;
BA_DEF_ BO_  "GenMsgCycleTime" INT 0 65535;
BA_DEF_ BO_  "GenMsgCycleTimeFast" INT 0 65535;
BA_DEF_ BO_  "GenMsgDelayTime" INT 0 100000;
BA_DEF_ BO_  "GenMsgILSupport" ENUM "No", "Yes";
BA_DEF_ BO_  "GenMsgNrOfRepetition" INT 0 100;
BA_DEF_ BO_  "GenMsgPDUConstants" STRING;
BA_DEF_ BO_  "GenMsgSendType" ENUM "Cyclic", "not_used", "not_used", "not_used", "not_used", "not_used", "not_used", "IfActive", "NoMsgSendType";
BA_DEF_ BO_  "GenMsgStartDelayTime" INT 0 100000;
BA_DEF_ BO_  "NmMessage" ENUM "No", "Yes";
BA_DEF_ BO_  "NmhMessage" ENUM "No", "Yes";
BA_DEF_ BO_  "MsgType" ENUM "Application", "NM ", "NMH", "TP2.0", "ISO-TP ", "BAP", "EID", "KS", "XCP_PRE_CONFIGURED", "XCP_RUNTIME_CONFIGURED";
BA_DEF_ BO_  "VAGTP20_API" HEX 0 255;
BA_DEF_ BO_  "VAGTP20_DynConnection" ENUM "No", "Yes";
BA_DEF_ BO_  "VAGTP20_DynSetup" ENUM "No", "Yes";
BA_DEF_ BO_  "VAGTP20_StatConnection" ENUM "No", "Yes";
BA_DEF_ SG_  "GenSigActiveRepetitions" INT -2147483648 2147483647;
BA_DEF_ SG_  "GenSigInactiveValue" INT -2147483648 2147483647;
BA_DEF_ SG_  "GenSigSendType" ENUM "Cyclic", "OnWrite", "OnWriteWithRepetition", "OnChange", "OnChangeWithRepetition", "IfActive", "IfActiveWithRepetition", "NoSigSendType", "OnChangeAndIfActive", "OnChangeAndIfActiveWithRepetition";
BA_DEF_ SG_  "GenSigStartValue" INT -2147483648 2147483647;
BA_DEF_ SG_  "NWM-WakeupAllowed" ENUM "No", "Yes";
BA_DEF_ SG_  "GenSigFuncType" ENUM "NoFunction", "MsgCounter", "CRC-8", "XOR", "XOR-2", "DatedBit", "SW-Kl15", "CHK", "Constant", "Protocol", "CRC-8-SAE_J1850", "CRC-32", "DataLength", "DataID", "MsgCounter16", "SOK-Signatur", "Cluster";
BA_DEF_ SG_  "GenSigSwitchedByIgnition" ENUM "No", "Yes";
BA_DEF_ SG_  "Fehlerwert" HEX 0 2147483647;
BA_DEF_ SG_  "GenSigMissingSourceValue" HEX 0 2147483647;
BA_DEF_DEF_REL_  "GenSigTimeoutTime" 0;
BA_DEF_DEF_  "DiagRequest" "No";
BA_DEF_DEF_  "DiagResponse" "No";
BA_DEF_DEF_  "DiagState" "No";
BA_DEF_DEF_  "GenMsgChkConstant" 0;
BA_DEF_DEF_  "GenMsgCycleTime" 0;
BA_DEF_DEF_  "GenMsgCycleTimeFast" 0;
BA_DEF_DEF_  "GenMsgDelayTime" 0;
BA_DEF_DEF_  "GenMsgILSupport" "No";
BA_DEF_DEF_  "GenMsgNrOfRepetition" 0;
BA_DEF_DEF_  "GenMsgPDUConstants" "";
BA_DEF_DEF_  "GenMsgSendType" "NoMsgSendType";
BA_DEF_DEF_  "GenMsgStartDelayTime" 0;
BA_DEF_DEF_  "NmMessage" "No";
BA_DEF_DEF_  "NmhMessage" "No";
BA_DEF_DEF_  "MsgType" "Application";
BA_DEF_DEF_  "VAGTP20_API" 0;
BA_DEF_DEF_  "VAGTP20_DynConnection" "No";
BA_DEF_DEF_  "VAGTP20_DynSetup" "No";
BA_DEF_DEF_  "VAGTP20_StatConnection" "No";
BA_DEF_DEF_  "GenSigActiveRepetitions" 0;
BA_DEF_DEF_  "GenSigInactiveValue" 0;
BA_DEF_DEF_  "GenSigSendType" "NoSigSendType";
BA_DEF_DEF_  "GenSigStartValue" 0;
BA_DEF_DEF_  "NWM-WakeupAllowed" "No";
BA_DEF_DEF_  "GenSigFuncType" "NoFunction";
BA_DEF_DEF_  "GenSigSwitchedByIgnition" "Yes";
BA_DEF_DEF_  "Fehlerwert" 0;
BA_DEF_DEF_  "GenSigMissingSourceValue" 0;
BA_ "GenMsgCycleTime" BO_ 917 100;
BA_ "GenMsgDelayTime" BO_ 917 10;
BA_ "GenMsgILSupport" BO_ 917 1;
BA_ "GenMsgSendType" BO_ 917 0;
BA_ "GenMsgCycleTime" BO_ 1153 500;
BA_ "GenMsgCycleTimeFast" BO_ 1153 50;
BA_ "GenMsgDelayTime" BO_ 1153 50;
BA_ "GenMsgILSupport" BO_ 1153 1;
BA_ "GenMsgNrOfRepetition" BO_ 1153 5;
BA_ "GenMsgSendType" BO_ 1153 0;
BA_ "GenMsgCycleTime" BO_ 1600 320;
BA_ "GenMsgILSupport" BO_ 1600 1;
BA_ "GenMsgSendType" BO_ 1600 0;
BA_ "GenMsgCycleTime" BO_ 167 20;
BA_ "GenMsgILSupport" BO_ 167 1;
BA_ "GenMsgPDUConstants" BO_ 167 "0xd2,0x3d,0xcd,0x28,0x4c,0x14,0x22,0x4b,0x24,0xac,0xfa,0x55,0x66,0x80,0x0d,0x6c";
BA_ "GenMsgSendType" BO_ 167 0;
BA_ "GenMsgCycleTime" BO_ 168 10;
BA_ "GenMsgILSupport" BO_ 168 1;
BA_ "GenMsgPDUConstants" BO_ 168 "0x52,0x8c,0x50,0xee,0x4f,0xa6,0xcc,0xcf,0x7d,0x2f,0x98,0x6b,0x27,0x41,0x9f,0x93";
BA_ "GenMsgSendType" BO_ 168 0;
BA_ "GenMsgCycleTime" BO_ 958 100;
BA_ "GenMsgDelayTime" BO_ 958 10;
BA_ "GenMsgILSupport" BO_ 958 1;
BA_ "GenMsgPDUConstants" BO_ 958 "0x1f,0x28,0xc6,0x85,0xe6,0xf8,0xb0,0x19,0x5b,0x64,0x35,0x21,0xe4,0xf7,0x9c,0x24";
BA_ "GenMsgSendType" BO_ 958 0;
BA_ "GenMsgCycleTime" BO_ 1648 500;
BA_ "GenMsgDelayTime" BO_ 1648 20;
BA_ "GenMsgILSupport" BO_ 1648 1;
BA_ "GenMsgSendType" BO_ 1648 0;
BA_ "GenMsgCycleTime" BO_ 1010 80;
BA_ "GenMsgILSupport" BO_ 1010 1;
BA_ "GenMsgSendType" BO_ 1010 0;
BA_ "GenMsgCycleTime" BO_ 289 50;
BA_ "GenMsgILSupport" BO_ 289 1;
BA_ "GenMsgPDUConstants" BO_ 289 "0xe9,0x65,0xae,0x6b,0x7b,0x35,0xe5,0x5f,0x4e,0xc7,0x86,0xa2,0xbb,0xdd,0xeb,0xb4";
BA_ "GenMsgSendType" BO_ 289 0;
BA_ "GenMsgCycleTime" BO_ 815 40;
BA_ "GenMsgILSupport" BO_ 815 1;
BA_ "GenMsgSendType" BO_ 815 0;
BA_ "GenMsgCycleTime" BO_ 1423 320;
BA_ "GenMsgILSupport" BO_ 1423 1;
BA_ "GenMsgSendType" BO_ 1423 0;
BA_ "GenMsgCycleTime" BO_ 340 200;
BA_ "GenMsgILSupport" BO_ 340 1;
BA_ "GenMsgPDUConstants" BO_ 340 "0x21,0x93,0x4a,0x04,0x5c,0x18,0xe0,0x69,0x14,0xce,0x26,0x8f,0x5e,0xb1,0xdf,0x53";
BA_ "GenMsgSendType" BO_ 340 0;
BA_ "GenMsgChkConstant" BO_ 1601 71;
BA_ "GenMsgCycleTime" BO_ 1601 960;
BA_ "GenMsgILSupport" BO_ 1601 1;
BA_ "GenMsgPDUConstants" BO_ 1601 "0x47,0x47,0x47,0x47,0x47,0x47,0x47,0x47,0x47,0x47,0x47,0x47,0x47,0x47,0x47,0x47";
BA_ "GenMsgSendType" BO_ 1601 0;
BA_ "GenMsgCycleTime" BO_ 305 20;
BA_ "GenMsgILSupport" BO_ 305 1;
BA_ "GenMsgSendType" BO_ 305 0;
BA_ "GenMsgCycleTime" BO_ 394 200;
BA_ "GenMsgDelayTime" BO_ 394 10;
BA_ "GenMsgILSupport" BO_ 394 1;
BA_ "GenMsgSendType" BO_ 394 0;
BA_ "GenMsgStartDelayTime" BO_ 394 20;
BA_ "GenMsgCycleTime" BO_ 234 10.0;
BA_ "GenMsgILSupport" BO_ 234 1;
BA_ "GenMsgPDUConstants" BO_ 234 "0x79,0xdb,0x11,0x86,0xb6,0x29,0x9c,0x0d,0xdc,0x1c,0x4a,0xbd,0xb8,0x2d,0xc1,0xab";
BA_ "GenMsgSendType" BO_ 234 0;
BA_ "GenMsgCycleTime" BO_ 849 320;
BA_ "GenMsgDelayTime" BO_ 849 80;
BA_ "GenMsgILSupport" BO_ 849 1;
BA_ "GenMsgSendType" BO_ 849 0;
BA_ "GenMsgCycleTime" BO_ 2463978596 2000;
BA_ "GenMsgDelayTime" BO_ 2463978596 50;
BA_ "GenMsgILSupport" BO_ 2463978596 1;
BA_ "GenMsgSendType" BO_ 2463978596 0;
BA_ "GenMsgCycleTime" BO_ 848 500;
BA_ "GenMsgDelayTime" BO_ 848 100;
BA_ "GenMsgILSupport" BO_ 848 1;
BA_ "GenMsgSendType" BO_ 848 0;
BA_ "GenMsgCycleTime" BO_ 1696 200;
BA_ "GenMsgDelayTime" BO_ 1696 20;
BA_ "GenMsgILSupport" BO_ 1696 1;
BA_ "GenMsgSendType" BO_ 1696 0;
BA_ "GenMsgCycleTime" BO_ 2600468496 200;
BA_ "GenMsgCycleTimeFast" BO_ 2600468496 10;
BA_ "GenMsgNrOfRepetition" BO_ 2600468496 3;
BA_ "GenMsgSendType" BO_ 2600468496 7;
BA_ "NmhMessage" BO_ 2600468496 1;
BA_ "MsgType" BO_ 2600468496 2;
BA_ "GenMsgCycleTime" BO_ 2600468519 200;
BA_ "GenMsgCycleTimeFast" BO_ 2600468519 10;
BA_ "GenMsgNrOfRepetition" BO_ 2600468519 3;
BA_ "GenMsgSendType" BO_ 2600468519 7;
BA_ "NmhMessage" BO_ 2600468519 1;
BA_ "MsgType" BO_ 2600468519 2;
BA_ "GenMsgCycleTime" BO_ 2600468491 200;
BA_ "GenMsgCycleTimeFast" BO_ 2600468491 10;
BA_ "GenMsgNrOfRepetition" BO_ 2600468491 3;
BA_ "GenMsgSendType" BO_ 2600468491 7;
BA_ "NmhMessage" BO_ 2600468491 1;
BA_ "MsgType" BO_ 2600468491 2;
BA_ "GenSigSendType" SG_ 917 AFS_Abbiegelicht_Dimm_Anf 0;
BA_ "GenSigSendType" SG_ 917 AFS_Abbiegelicht_li_Anf 0;
BA_ "GenSigSendType" SG_ 917 AFS_Abbiegelicht_re_Anf 0;
BA_ "GenSigSendType" SG_ 917 AFS_adaptive_LV_verbaut 0;
BA_ "GenSigSendType" SG_ 917 AFS_Allwetterlicht 0;
BA_ "GenSigSendType" SG_ 917 AFS_Charisma_FahrPr 0;
BA_ "GenSigSendType" SG_ 917 AFS_Charisma_Status 0;
BA_ "GenSigSendType" SG_ 917 AFS_Charisma_Umschaltung 3;
BA_ "GenSigSendType" SG_ 917 AFS_Ersatzlicht_Links 0;
BA_ "GenSigSendType" SG_ 917 AFS_Ersatzlicht_Rechts 0;
BA_ "GenSigSendType" SG_ 917 AFS_Fehlertext 0;
BA_ "GenSigSendType" SG_ 917 AFS_Fernlicht_li_defekt 0;
BA_ "GenSigSendType" SG_ 917 AFS_Fernlicht_re_defekt 0;
BA_ "GenSigSendType" SG_ 917 AFS_Fernlicht_Status 3;
BA_ "GenSigSendType" SG_ 917 AFS_Lampe 0;
BA_ "GenSigSendType" SG_ 917 AFS_LED_Blinkmode 0;
BA_ "GenSigSendType" SG_ 917 AFS_Status_adaptive_LV 0;
BA_ "GenSigStartValue" SG_ 917 AFS_Status_adaptive_LV 1;
BA_ "GenSigSendType" SG_ 917 AFS_Verfuegbarkeit_GLW 0;
BA_ "GenSigStartValue" SG_ 917 AFS_Verfuegbarkeit_GLW 1;
BA_ "GenSigSendType" SG_ 917 GLW_Sensor_blockiert 0;
BA_ "GenSigSendType" SG_ 917 LWR_AFS_01_BZ 0;
BA_ "GenSigFuncType" SG_ 917 LWR_AFS_01_BZ 1;
BA_ "GenSigSendType" SG_ 917 LWR_AFS_Grundeinstellung 0;
BA_ "GenSigSendType" SG_ 917 LWR_AFS_Parametrisierung 0;
BA_ "GenSigSendType" SG_ 917 LWR_Hoehenwert_HL 0;
BA_ "GenSigStartValue" SG_ 917 LWR_Hoehenwert_HL 254;
BA_ "Fehlerwert" SG_ 917 LWR_Hoehenwert_HL 255;
BA_ "GenSigSendType" SG_ 917 LWR_Hoehenwert_VL 0;
BA_ "GenSigStartValue" SG_ 917 LWR_Hoehenwert_VL 254;
BA_ "Fehlerwert" SG_ 917 LWR_Hoehenwert_VL 255;
BA_ "GenSigSendType" SG_ 917 LWR_Initialisierungslauf 0;
BA_ "GenSigSendType" SG_ 917 LWR_Lampe 0;
BA_ "GenSigSendType" SG_ 917 LWR_Modus 0;
BA_ "GenSigSendType" SG_ 917 LWR_Pos_Schrittmotor 0;
BA_ "GenSigStartValue" SG_ 917 LWR_Pos_Schrittmotor 254;
BA_ "Fehlerwert" SG_ 917 LWR_Pos_Schrittmotor 255;
BA_ "GenSigSendType" SG_ 917 LWR_Reisemodus_Texte 0;
BA_ "GenSigSendType" SG_ 917 LWR_Sicherheitsposition_li 0;
BA_ "GenSigSendType" SG_ 917 LWR_Sicherheitsposition_re 0;
BA_ "GenSigSendType" SG_ 917 LWR_Touristenmodus_aktiv 0;
BA_ "GenSigSendType" SG_ 917 LWR_Touristenmodus_verbaut 0;
BA_ "GenSigSendType" SG_ 1153 DSSS_Warning 3;
BA_ "GenSigSwitchedByIgnition" SG_ 1153 DSSS_Warning 0;
BA_ "GenSigSendType" SG_ 1153 MIB_Tongenerator_PH_verfuegbar 3;
BA_ "GenSigSwitchedByIgnition" SG_ 1153 MIB_Tongenerator_PH_verfuegbar 0;
BA_ "GenSigSendType" SG_ 1153 MMI_Counter_Bedienevent 0;
BA_ "GenSigSwitchedByIgnition" SG_ 1153 MMI_Counter_Bedienevent 0;
BA_ "GenSigSendType" SG_ 1153 MMI_Gauges_active 3;
BA_ "GenSigSwitchedByIgnition" SG_ 1153 MMI_Gauges_active 0;
BA_ "GenSigSendType" SG_ 1153 MMI_Gurt_Mic_ref 0;
BA_ "GenSigSwitchedByIgnition" SG_ 1153 MMI_Gurt_Mic_ref 0;
BA_ "GenSigSendType" SG_ 1153 MMI_SDS_aktiv 3;
BA_ "GenSigSwitchedByIgnition" SG_ 1153 MMI_SDS_aktiv 0;
BA_ "GenSigSendType" SG_ 1153 MMI_StartStopp_Info 3;
BA_ "GenSigSwitchedByIgnition" SG_ 1153 MMI_StartStopp_Info 0;
BA_ "Fehlerwert" SG_ 1153 MMI_StartStopp_Info 3;
BA_ "GenSigSendType" SG_ 1153 MMI_Telefon_aktiv 3;
BA_ "GenSigSwitchedByIgnition" SG_ 1153 MMI_Telefon_aktiv 0;
BA_ "GenSigSendType" SG_ 1153 MU_SecondDisplay 3;
BA_ "GenSigSwitchedByIgnition" SG_ 1153 MU_SecondDisplay 0;
BA_ "GenSigSendType" SG_ 1153 MU_Update_Time 0;
BA_ "GenSigSwitchedByIgnition" SG_ 1153 MU_Update_Time 0;
BA_ "GenSigSendType" SG_ 1153 Nav_FoD_Status 3;
BA_ "GenSigSwitchedByIgnition" SG_ 1153 Nav_FoD_Status 0;
BA_ "GenSigSendType" SG_ 1153 ZR_Kindersicherung_RSE 3;
BA_ "GenSigSwitchedByIgnition" SG_ 1153 ZR_Kindersicherung_RSE 0;
BA_ "GenSigSendType" SG_ 1153 ZR_LAPP_Sondermodus_Status 3;
BA_ "GenSigSendType" SG_ 1153 ZR_LoGeWa_Event_Kombiwarnung 3;
BA_ "GenSigSwitchedByIgnition" SG_ 1153 ZR_LoGeWa_Event_Kombiwarnung 0;
BA_ "GenSigSendType" SG_ 1153 ZR_MXB_Manoever_Ansage 3;
BA_ "GenSigSwitchedByIgnition" SG_ 1153 ZR_MXB_Manoever_Ansage 0;
BA_ "GenSigSendType" SG_ 1153 ZR_Parken_Sondermodus 3;
BA_ "GenSigSwitchedByIgnition" SG_ 1153 ZR_Parken_Sondermodus 0;
BA_ "GenSigSendType" SG_ 1153 ZR_RSE_aktivieren 3;
BA_ "GenSigSwitchedByIgnition" SG_ 1153 ZR_RSE_aktivieren 0;
BA_ "GenSigSendType" SG_ 1153 ZR_Rundenbewertung 3;
BA_ "GenSigStartValue" SG_ 1153 ZR_Rundenbewertung 14;
BA_ "GenSigSwitchedByIgnition" SG_ 1153 ZR_Rundenbewertung 0;
BA_ "GenSigSendType" SG_ 1153 ZR_Rundenfortschritt 3;
BA_ "GenSigStartValue" SG_ 1153 ZR_Rundenfortschritt 254;
BA_ "GenSigSwitchedByIgnition" SG_ 1153 ZR_Rundenfortschritt 0;
BA_ "GenSigActiveRepetitions" SG_ 1153 ZR_Sta_Inszenierung 5;
BA_ "GenSigSendType" SG_ 1153 ZR_Sta_Inszenierung 4;
BA_ "GenSigSwitchedByIgnition" SG_ 1153 ZR_Sta_Inszenierung 0;
BA_ "GenSigSendType" SG_ 1600 MO_Absperrventil_oeffnen 0;
BA_ "GenSigSwitchedByIgnition" SG_ 1600 MO_Absperrventil_oeffnen 0;
BA_ "GenSigSendType" SG_ 1600 MO_aktives_Getriebeheizen 0;
BA_ "GenSigSwitchedByIgnition" SG_ 1600 MO_aktives_Getriebeheizen 0;
BA_ "GenSigSendType" SG_ 1600 MO_Ansaugluft_Temp 0;
BA_ "GenSigStartValue" SG_ 1600 MO_Ansaugluft_Temp 254;
BA_ "GenSigSwitchedByIgnition" SG_ 1600 MO_Ansaugluft_Temp 0;
BA_ "Fehlerwert" SG_ 1600 MO_Ansaugluft_Temp 255;
BA_ "GenSigSendType" SG_ 1600 MO_Getriebe_kuehlen 0;
BA_ "GenSigSwitchedByIgnition" SG_ 1600 MO_Getriebe_kuehlen 0;
BA_ "GenSigSendType" SG_ 1600 MO_Heizungspumpenansteuerung 0;
BA_ "GenSigStartValue" SG_ 1600 MO_Heizungspumpenansteuerung 14;
BA_ "GenSigSwitchedByIgnition" SG_ 1600 MO_Heizungspumpenansteuerung 0;
BA_ "Fehlerwert" SG_ 1600 MO_Heizungspumpenansteuerung 13;
BA_ "GenSigSendType" SG_ 1600 MO_Hoeheninfo 0;
BA_ "GenSigSwitchedByIgnition" SG_ 1600 MO_Hoeheninfo 0;
BA_ "Fehlerwert" SG_ 1600 MO_Hoeheninfo 255;
BA_ "GenSigSendType" SG_ 1600 MO_HYB_Fehler_HV_Netz 0;
BA_ "GenSigSwitchedByIgnition" SG_ 1600 MO_HYB_Fehler_HV_Netz 0;
BA_ "GenSigSendType" SG_ 1600 MO_Kennfeldk 0;
BA_ "GenSigSwitchedByIgnition" SG_ 1600 MO_Kennfeldk 0;
BA_ "GenSigSendType" SG_ 1600 MO_KL15_Abschaltempfehlung 0;
BA_ "GenSigSwitchedByIgnition" SG_ 1600 MO_KL15_Abschaltempfehlung 0;
BA_ "GenSigSendType" SG_ 1600 MO_Kuehlmittel_Temp 0;
BA_ "GenSigStartValue" SG_ 1600 MO_Kuehlmittel_Temp 254;
BA_ "GenSigSwitchedByIgnition" SG_ 1600 MO_Kuehlmittel_Temp 0;
BA_ "Fehlerwert" SG_ 1600 MO_Kuehlmittel_Temp 255;
BA_ "GenSigSendType" SG_ 1600 MO_Mom_Traegheit_02 0;
BA_ "GenSigSwitchedByIgnition" SG_ 1600 MO_Mom_Traegheit_02 0;
BA_ "GenSigSendType" SG_ 1600 MO_Nachlaufzeit_Heizungspumpe 0;
BA_ "GenSigSwitchedByIgnition" SG_ 1600 MO_Nachlaufzeit_Heizungspumpe 0;
BA_ "GenSigSendType" SG_ 1600 MO_Oel_Temp 0;
BA_ "GenSigStartValue" SG_ 1600 MO_Oel_Temp 254;
BA_ "GenSigSwitchedByIgnition" SG_ 1600 MO_Oel_Temp 0;
BA_ "Fehlerwert" SG_ 1600 MO_Oel_Temp 255;
BA_ "GenSigSendType" SG_ 1600 MO_QBit_Ansaugluft_Temp 0;
BA_ "GenSigStartValue" SG_ 1600 MO_QBit_Ansaugluft_Temp 1;
BA_ "GenSigSwitchedByIgnition" SG_ 1600 MO_QBit_Ansaugluft_Temp 0;
BA_ "GenSigSendType" SG_ 1600 MO_QBit_Hoeheninfo 0;
BA_ "GenSigStartValue" SG_ 1600 MO_QBit_Hoeheninfo 1;
BA_ "GenSigSwitchedByIgnition" SG_ 1600 MO_QBit_Hoeheninfo 0;
BA_ "GenSigSendType" SG_ 1600 MO_QBit_Kuehlmittel_Temp 0;
BA_ "GenSigStartValue" SG_ 1600 MO_QBit_Kuehlmittel_Temp 1;
BA_ "GenSigSwitchedByIgnition" SG_ 1600 MO_QBit_Kuehlmittel_Temp 0;
BA_ "GenSigSendType" SG_ 1600 MO_QBit_Oel_Temp 0;
BA_ "GenSigStartValue" SG_ 1600 MO_QBit_Oel_Temp 1;
BA_ "GenSigSwitchedByIgnition" SG_ 1600 MO_QBit_Oel_Temp 0;
BA_ "GenSigSendType" SG_ 1600 MO_SpannungsAnf 0;
BA_ "GenSigSwitchedByIgnition" SG_ 1600 MO_SpannungsAnf 0;
BA_ "GenSigSendType" SG_ 1600 MO_Versionsinfo_02 0;
BA_ "GenSigSwitchedByIgnition" SG_ 1600 MO_Versionsinfo_02 0;
BA_ "GenSigSendType" SG_ 167 MO_erste_Ungenauschwelle 0;
BA_ "GenSigSwitchedByIgnition" SG_ 167 MO_erste_Ungenauschwelle 0;
BA_ "GenSigSendType" SG_ 167 MO_Mom_Ist_Summe 0;
BA_ "GenSigStartValue" SG_ 167 MO_Mom_Ist_Summe 1022;
BA_ "GenSigSwitchedByIgnition" SG_ 167 MO_Mom_Ist_Summe 0;
BA_ "GenSigSendType" SG_ 167 MO_Mom_Schub 0;
BA_ "GenSigStartValue" SG_ 167 MO_Mom_Schub 510;
BA_ "GenSigSwitchedByIgnition" SG_ 167 MO_Mom_Schub 0;
BA_ "GenSigSendType" SG_ 167 MO_Mom_Soll_gefiltert 0;
BA_ "GenSigStartValue" SG_ 167 MO_Mom_Soll_gefiltert 1022;
BA_ "GenSigSwitchedByIgnition" SG_ 167 MO_Mom_Soll_gefiltert 0;
BA_ "GenSigSendType" SG_ 167 MO_Mom_Soll_Roh 0;
BA_ "GenSigStartValue" SG_ 167 MO_Mom_Soll_Roh 1022;
BA_ "GenSigSwitchedByIgnition" SG_ 167 MO_Mom_Soll_Roh 0;
BA_ "GenSigSendType" SG_ 167 MO_Mom_Traegheit_Summe 0;
BA_ "GenSigStartValue" SG_ 167 MO_Mom_Traegheit_Summe 1022;
BA_ "GenSigSwitchedByIgnition" SG_ 167 MO_Mom_Traegheit_Summe 0;
BA_ "GenSigSendType" SG_ 167 MO_QBit_Motormomente 0;
BA_ "GenSigStartValue" SG_ 167 MO_QBit_Motormomente 1;
BA_ "GenSigSwitchedByIgnition" SG_ 167 MO_QBit_Motormomente 0;
BA_ "GenSigSendType" SG_ 167 MO_Status_Normalbetrieb_01 0;
BA_ "GenSigSwitchedByIgnition" SG_ 167 MO_Status_Normalbetrieb_01 0;
BA_ "GenSigSendType" SG_ 167 Motor_11_BZ 0;
BA_ "GenSigFuncType" SG_ 167 Motor_11_BZ 1;
BA_ "GenSigSwitchedByIgnition" SG_ 167 Motor_11_BZ 0;
BA_ "GenSigSendType" SG_ 167 Motor_11_CRC 0;
BA_ "GenSigFuncType" SG_ 167 Motor_11_CRC 2;
BA_ "GenSigSwitchedByIgnition" SG_ 167 Motor_11_CRC 0;
BA_ "GenSigSendType" SG_ 168 MO_Drehzahl_01 0;
BA_ "GenSigSwitchedByIgnition" SG_ 168 MO_Drehzahl_01 0;
BA_ "GenSigSendType" SG_ 168 MO_Mom_Begr_dyn 0;
BA_ "GenSigStartValue" SG_ 168 MO_Mom_Begr_dyn 1022;
BA_ "GenSigSwitchedByIgnition" SG_ 168 MO_Mom_Begr_dyn 0;
BA_ "GenSigSendType" SG_ 168 MO_Mom_Begr_stat 0;
BA_ "GenSigStartValue" SG_ 168 MO_Mom_Begr_stat 510;
BA_ "GenSigSwitchedByIgnition" SG_ 168 MO_Mom_Begr_stat 0;
BA_ "GenSigSendType" SG_ 168 MO_Mom_neg_verfuegbar 0;
BA_ "GenSigStartValue" SG_ 168 MO_Mom_neg_verfuegbar 510;
BA_ "GenSigSwitchedByIgnition" SG_ 168 MO_Mom_neg_verfuegbar 0;
BA_ "Fehlerwert" SG_ 168 MO_Mom_neg_verfuegbar 511;
BA_ "GenSigSendType" SG_ 168 MO_Momentenintegral_02 0;
BA_ "GenSigSwitchedByIgnition" SG_ 168 MO_Momentenintegral_02 0;
BA_ "GenSigSendType" SG_ 168 MO_QBit_Drehzahl_01 0;
BA_ "GenSigStartValue" SG_ 168 MO_QBit_Drehzahl_01 1;
BA_ "GenSigSwitchedByIgnition" SG_ 168 MO_QBit_Drehzahl_01 0;
BA_ "GenSigSendType" SG_ 168 Motor_12_BZ 0;
BA_ "GenSigFuncType" SG_ 168 Motor_12_BZ 1;
BA_ "GenSigSwitchedByIgnition" SG_ 168 Motor_12_BZ 0;
BA_ "GenSigSendType" SG_ 168 Motor_12_CRC 0;
BA_ "GenSigFuncType" SG_ 168 Motor_12_CRC 2;
BA_ "GenSigSwitchedByIgnition" SG_ 168 Motor_12_CRC 0;
BA_ "GenSigSendType" SG_ 958 MO_Aussp_Anlass 3;
BA_ "GenSigSwitchedByIgnition" SG_ 958 MO_Aussp_Anlass 0;
BA_ "GenSigSendType" SG_ 958 MO_BKV_Unterdruckwarnung 0;
BA_ "GenSigSwitchedByIgnition" SG_ 958 MO_BKV_Unterdruckwarnung 0;
BA_ "GenSigSendType" SG_ 958 MO_BLS 3;
BA_ "GenSigSwitchedByIgnition" SG_ 958 MO_BLS 0;
BA_ "GenSigSendType" SG_ 958 MO_BMS_NV_Anf_stuetzen 3;
BA_ "GenSigSwitchedByIgnition" SG_ 958 MO_BMS_NV_Anf_stuetzen 0;
BA_ "GenSigSendType" SG_ 958 MO_EKlKomLeiRed 0;
BA_ "GenSigSwitchedByIgnition" SG_ 958 MO_EKlKomLeiRed 0;
BA_ "GenSigSendType" SG_ 958 MO_Ext_E_Fahrt_aktiv 3;
BA_ "NWM-WakeupAllowed" SG_ 958 MO_Ext_E_Fahrt_aktiv 1;
BA_ "GenSigSwitchedByIgnition" SG_ 958 MO_Ext_E_Fahrt_aktiv 0;
BA_ "GenSigSendType" SG_ 958 MO_Fahrer_bremst 3;
BA_ "GenSigSwitchedByIgnition" SG_ 958 MO_Fahrer_bremst 0;
BA_ "GenSigSendType" SG_ 958 MO_FMAus_aktiv 3;
BA_ "GenSigSwitchedByIgnition" SG_ 958 MO_FMAus_aktiv 0;
BA_ "GenSigSendType" SG_ 958 MO_FMAus_Startvariante 3;
BA_ "GenSigSwitchedByIgnition" SG_ 958 MO_FMAus_Startvariante 0;
BA_ "GenSigSendType" SG_ 958 MO_Freig_Anlass 3;
BA_ "GenSigSwitchedByIgnition" SG_ 958 MO_Freig_Anlass 0;
BA_ "GenSigSendType" SG_ 958 MO_Freig_Reku 0;
BA_ "GenSigSwitchedByIgnition" SG_ 958 MO_Freig_Reku 0;
BA_ "GenSigSendType" SG_ 958 MO_Freigabe_Segeln 0;
BA_ "GenSigSwitchedByIgnition" SG_ 958 MO_Freigabe_Segeln 0;
BA_ "GenSigSendType" SG_ 958 MO_Gangposition 3;
BA_ "GenSigStartValue" SG_ 958 MO_Gangposition 14;
BA_ "GenSigSwitchedByIgnition" SG_ 958 MO_Gangposition 0;
BA_ "Fehlerwert" SG_ 958 MO_Gangposition 15;
BA_ "GenSigSendType" SG_ 958 MO_Handshake_STH 0;
BA_ "GenSigSwitchedByIgnition" SG_ 958 MO_Handshake_STH 0;
BA_ "GenSigSendType" SG_ 958 MO_HYB_Fahrbereitschaft 0;
BA_ "GenSigSwitchedByIgnition" SG_ 958 MO_HYB_Fahrbereitschaft 0;
BA_ "GenSigSendType" SG_ 958 MO_HYB_VM_aktiv 3;
BA_ "GenSigSwitchedByIgnition" SG_ 958 MO_HYB_VM_aktiv 0;
BA_ "GenSigSendType" SG_ 958 MO_Interlock 3;
BA_ "GenSigSwitchedByIgnition" SG_ 958 MO_Interlock 0;
BA_ "GenSigSendType" SG_ 958 MO_Kickdown 3;
BA_ "GenSigSwitchedByIgnition" SG_ 958 MO_Kickdown 0;
BA_ "GenSigSendType" SG_ 958 MO_Kl_50 3;
BA_ "GenSigSwitchedByIgnition" SG_ 958 MO_Kl_50 0;
BA_ "GenSigSendType" SG_ 958 MO_Kl_75 3;
BA_ "GenSigSwitchedByIgnition" SG_ 958 MO_Kl_75 0;
BA_ "GenSigSendType" SG_ 958 MO_Klima_Eingr 0;
BA_ "GenSigSwitchedByIgnition" SG_ 958 MO_Klima_Eingr 0;
BA_ "GenSigSendType" SG_ 958 MO_KomFehler_ESP 3;
BA_ "GenSigSwitchedByIgnition" SG_ 958 MO_KomFehler_ESP 0;
BA_ "Fehlerwert" SG_ 958 MO_KomFehler_ESP 1;
BA_ "GenSigSendType" SG_ 958 MO_Konsistenz_Bremsped 3;
BA_ "GenSigSwitchedByIgnition" SG_ 958 MO_Konsistenz_Bremsped 0;
BA_ "GenSigSendType" SG_ 958 MO_Kuppl_schalter 3;
BA_ "GenSigSwitchedByIgnition" SG_ 958 MO_Kuppl_schalter 0;
BA_ "GenSigSendType" SG_ 958 MO_Motor_laeuft 3;
BA_ "GenSigSwitchedByIgnition" SG_ 958 MO_Motor_laeuft 0;
BA_ "GenSigSendType" SG_ 958 MO_PTC_Status 0;
BA_ "GenSigSwitchedByIgnition" SG_ 958 MO_PTC_Status 0;
BA_ "GenSigSendType" SG_ 958 MO_QBit_Fahrer_bremst 3;
BA_ "GenSigStartValue" SG_ 958 MO_QBit_Fahrer_bremst 1;
BA_ "GenSigSwitchedByIgnition" SG_ 958 MO_QBit_Fahrer_bremst 0;
BA_ "GenSigSendType" SG_ 958 MO_QBit_Gangposition 3;
BA_ "GenSigStartValue" SG_ 958 MO_QBit_Gangposition 1;
BA_ "GenSigSwitchedByIgnition" SG_ 958 MO_QBit_Gangposition 0;
BA_ "GenSigSendType" SG_ 958 MO_QBit_KL_75 3;
BA_ "GenSigStartValue" SG_ 958 MO_QBit_KL_75 1;
BA_ "GenSigSwitchedByIgnition" SG_ 958 MO_QBit_KL_75 0;
BA_ "GenSigSendType" SG_ 958 MO_Remotestart_Betrieb 3;
BA_ "GenSigSwitchedByIgnition" SG_ 958 MO_Remotestart_Betrieb 0;
BA_ "GenSigSendType" SG_ 958 MO_Remotestart_moeglich 0;
BA_ "GenSigSwitchedByIgnition" SG_ 958 MO_Remotestart_moeglich 0;
BA_ "GenSigSendType" SG_ 958 MO_Signalquelle_Gangposition 0;
BA_ "GenSigSwitchedByIgnition" SG_ 958 MO_Signalquelle_Gangposition 0;
BA_ "GenSigSendType" SG_ 958 MO_StartStopp_Fahrerwunsch 0;
BA_ "GenSigSwitchedByIgnition" SG_ 958 MO_StartStopp_Fahrerwunsch 0;
BA_ "GenSigSendType" SG_ 958 MO_StartStopp_Motorstopp 3;
BA_ "GenSigSwitchedByIgnition" SG_ 958 MO_StartStopp_Motorstopp 0;
BA_ "GenSigSendType" SG_ 958 MO_StartStopp_Status 3;
BA_ "GenSigSwitchedByIgnition" SG_ 958 MO_StartStopp_Status 0;
BA_ "GenSigSendType" SG_ 958 MO_StartStopp_Wiederstart 3;
BA_ "GenSigSwitchedByIgnition" SG_ 958 MO_StartStopp_Wiederstart 0;
BA_ "GenSigSendType" SG_ 958 MO_StartVorauss_erfuellt 3;
BA_ "GenSigStartValue" SG_ 958 MO_StartVorauss_erfuellt 1;
BA_ "GenSigSwitchedByIgnition" SG_ 958 MO_StartVorauss_erfuellt 0;
BA_ "GenSigSendType" SG_ 958 MO_Text_Geschw_red 0;
BA_ "GenSigSwitchedByIgnition" SG_ 958 MO_Text_Geschw_red 0;
BA_ "GenSigSendType" SG_ 958 MO_Zylinderabschaltung 3;
BA_ "GenSigSwitchedByIgnition" SG_ 958 MO_Zylinderabschaltung 0;
BA_ "GenSigSendType" SG_ 958 Motor_14_BZ 0;
BA_ "GenSigFuncType" SG_ 958 Motor_14_BZ 1;
BA_ "GenSigSwitchedByIgnition" SG_ 958 Motor_14_BZ 0;
BA_ "GenSigSendType" SG_ 958 Motor_14_CRC 0;
BA_ "GenSigFuncType" SG_ 958 Motor_14_CRC 2;
BA_ "GenSigSwitchedByIgnition" SG_ 958 Motor_14_CRC 0;
BA_ "GenSigSendType" SG_ 1648 MO1_Freigabe_Info_WFS 3;
BA_ "GenSigSwitchedByIgnition" SG_ 1648 MO1_Freigabe_Info_WFS 0;
BA_ "GenSigSendType" SG_ 1648 MO1_Freigabe_Verfallsinfo_WFS 3;
BA_ "GenSigSwitchedByIgnition" SG_ 1648 MO1_Freigabe_Verfallsinfo_WFS 0;
BA_ "GenSigSendType" SG_ 1648 MO1_Sperr_Info_WFS 3;
BA_ "GenSigSwitchedByIgnition" SG_ 1648 MO1_Sperr_Info_WFS 0;
BA_ "GenSigSendType" SG_ 1648 MO_Abstellzeit 0;
BA_ "GenSigStartValue" SG_ 1648 MO_Abstellzeit 254;
BA_ "GenSigSwitchedByIgnition" SG_ 1648 MO_Abstellzeit 0;
BA_ "GenSigSendType" SG_ 1648 MO_Abstellzeit_Status 0;
BA_ "GenSigSwitchedByIgnition" SG_ 1648 MO_Abstellzeit_Status 0;
BA_ "GenSigSendType" SG_ 1648 MO_ANC_Kennfeld_Anf 3;
BA_ "GenSigSwitchedByIgnition" SG_ 1648 MO_ANC_Kennfeld_Anf 0;
BA_ "GenSigSendType" SG_ 1648 MO_Anzahl_Abgesch_Zyl 3;
BA_ "GenSigSwitchedByIgnition" SG_ 1648 MO_Anzahl_Abgesch_Zyl 0;
BA_ "GenSigSendType" SG_ 1648 MO_Bremslicht_Reku 3;
BA_ "GenSigSwitchedByIgnition" SG_ 1648 MO_Bremslicht_Reku 0;
BA_ "GenSigSendType" SG_ 1648 MO_Drehzahl_Warnung 0;
BA_ "GenSigSwitchedByIgnition" SG_ 1648 MO_Drehzahl_Warnung 0;
BA_ "GenSigSendType" SG_ 1648 MO_EPCL 0;
BA_ "GenSigSwitchedByIgnition" SG_ 1648 MO_EPCL 0;
BA_ "GenSigSendType" SG_ 1648 MO_Ethanol_BS_Texte 0;
BA_ "GenSigSwitchedByIgnition" SG_ 1648 MO_Ethanol_BS_Texte 0;
BA_ "GenSigSendType" SG_ 1648 MO_Fahrzeugtyp 0;
BA_ "GenSigFuncType" SG_ 1648 MO_Fahrzeugtyp 8;
BA_ "GenSigSwitchedByIgnition" SG_ 1648 MO_Fahrzeugtyp 0;
BA_ "GenSigSendType" SG_ 1648 MO_Fehler_Zylabsch 0;
BA_ "GenSigSwitchedByIgnition" SG_ 1648 MO_Fehler_Zylabsch 0;
BA_ "GenSigSendType" SG_ 1648 MO_Hybrid_StartStopp_LED 3;
BA_ "GenSigSwitchedByIgnition" SG_ 1648 MO_Hybrid_StartStopp_LED 0;
BA_ "GenSigSendType" SG_ 1648 MO_max_Ladedruck 0;
BA_ "GenSigFuncType" SG_ 1648 MO_max_Ladedruck 8;
BA_ "GenSigSwitchedByIgnition" SG_ 1648 MO_max_Ladedruck 0;
BA_ "GenSigSendType" SG_ 1648 MO_NMAX_Schaltanzeige 3;
BA_ "GenSigSwitchedByIgnition" SG_ 1648 MO_NMAX_Schaltanzeige 0;
BA_ "GenSigSendType" SG_ 1648 MO_obere_Drehzahlgrenze 0;
BA_ "GenSigSwitchedByIgnition" SG_ 1648 MO_obere_Drehzahlgrenze 0;
BA_ "GenSigSendType" SG_ 1648 MO_StartStopp_PopUp 3;
BA_ "GenSigSwitchedByIgnition" SG_ 1648 MO_StartStopp_PopUp 0;
BA_ "GenSigSendType" SG_ 1648 MO_Zylabsch_Texte 0;
BA_ "GenSigSwitchedByIgnition" SG_ 1648 MO_Zylabsch_Texte 0;
BA_ "GenSigSendType" SG_ 1648 MO_Zylabsch_Texte_02 3;
BA_ "GenSigSwitchedByIgnition" SG_ 1648 MO_Zylabsch_Texte_02 0;
BA_ "GenSigSendType" SG_ 1010 MO_SCR_Dosierpumpe_Soll 0;
BA_ "GenSigSwitchedByIgnition" SG_ 1010 MO_SCR_Dosierpumpe_Soll 0;
BA_ "GenSigSendType" SG_ 1010 MO_SCR_Dosierpumpe_Wartezeit 0;
BA_ "GenSigStartValue" SG_ 1010 MO_SCR_Dosierpumpe_Wartezeit 126;
BA_ "GenSigSwitchedByIgnition" SG_ 1010 MO_SCR_Dosierpumpe_Wartezeit 0;
BA_ "Fehlerwert" SG_ 1010 MO_SCR_Dosierpumpe_Wartezeit 127;
BA_ "GenSigSendType" SG_ 1010 MO_SCR_Dosierpumpe_Zustand 0;
BA_ "GenSigSwitchedByIgnition" SG_ 1010 MO_SCR_Dosierpumpe_Zustand 0;
BA_ "GenSigSendType" SG_ 1010 MO_SCR_Heizkreis_3 0;
BA_ "GenSigSwitchedByIgnition" SG_ 1010 MO_SCR_Heizkreis_3 0;
BA_ "GenSigSendType" SG_ 1010 MO_SCR_Heizkreis_3_Leistung 0;
BA_ "GenSigStartValue" SG_ 1010 MO_SCR_Heizkreis_3_Leistung 254;
BA_ "GenSigSwitchedByIgnition" SG_ 1010 MO_SCR_Heizkreis_3_Leistung 0;
BA_ "GenSigSendType" SG_ 1010 MO_SCR_Leitungsheizung 0;
BA_ "GenSigSwitchedByIgnition" SG_ 1010 MO_SCR_Leitungsheizung 0;
BA_ "GenSigSendType" SG_ 1010 MO_SCR_Tankheizkreis_Leistung 0;
BA_ "GenSigStartValue" SG_ 1010 MO_SCR_Tankheizkreis_Leistung 254;
BA_ "GenSigSwitchedByIgnition" SG_ 1010 MO_SCR_Tankheizkreis_Leistung 0;
BA_ "GenSigSendType" SG_ 1010 MO_SCR_Tankheizung 0;
BA_ "GenSigSwitchedByIgnition" SG_ 1010 MO_SCR_Tankheizung 0;
BA_ "GenSigSendType" SG_ 1010 MO_SCR_Transferpumpe 0;
BA_ "GenSigSwitchedByIgnition" SG_ 1010 MO_SCR_Transferpumpe 0;
BA_ "GenSigSendType" SG_ 1010 Motor_19_BZ 0;
BA_ "GenSigFuncType" SG_ 1010 Motor_19_BZ 1;
BA_ "GenSigSwitchedByIgnition" SG_ 1010 Motor_19_BZ 0;
BA_ "GenSigSendType" SG_ 289 MO_Entkopplung_Sollschlupf 0;
BA_ "GenSigStartValue" SG_ 289 MO_Entkopplung_Sollschlupf 126;
BA_ "GenSigSwitchedByIgnition" SG_ 289 MO_Entkopplung_Sollschlupf 0;
BA_ "GenSigSendType" SG_ 289 MO_Fahrpedalgradient 0;
BA_ "GenSigSwitchedByIgnition" SG_ 289 MO_Fahrpedalgradient 0;
BA_ "Fehlerwert" SG_ 289 MO_Fahrpedalgradient 255;
BA_ "GenSigSendType" SG_ 289 MO_Fahrpedalrohwert_01 0;
BA_ "GenSigSwitchedByIgnition" SG_ 289 MO_Fahrpedalrohwert_01 0;
BA_ "Fehlerwert" SG_ 289 MO_Fahrpedalrohwert_01 255;
BA_ "GenSigSendType" SG_ 289 MO_Moment_im_Leerlauf 0;
BA_ "GenSigSwitchedByIgnition" SG_ 289 MO_Moment_im_Leerlauf 0;
BA_ "GenSigSendType" SG_ 289 MO_QBit_Fahrpedalwerte_01 0;
BA_ "GenSigStartValue" SG_ 289 MO_QBit_Fahrpedalwerte_01 1;
BA_ "GenSigSwitchedByIgnition" SG_ 289 MO_QBit_Fahrpedalwerte_01 0;
BA_ "GenSigSendType" SG_ 289 MO_rel_Saugrohrdruck 0;
BA_ "GenSigSwitchedByIgnition" SG_ 289 MO_rel_Saugrohrdruck 0;
BA_ "Fehlerwert" SG_ 289 MO_rel_Saugrohrdruck 63;
BA_ "GenSigSendType" SG_ 289 MO_rel_Saugrohrdruck_gem_err 0;
BA_ "GenSigSwitchedByIgnition" SG_ 289 MO_rel_Saugrohrdruck_gem_err 0;
BA_ "GenSigSendType" SG_ 289 MO_Schubabschaltung 0;
BA_ "GenSigSwitchedByIgnition" SG_ 289 MO_Schubabschaltung 0;
BA_ "GenSigSendType" SG_ 289 MO_Sig_Fahrpedalgradient 0;
BA_ "GenSigSwitchedByIgnition" SG_ 289 MO_Sig_Fahrpedalgradient 0;
BA_ "GenSigSendType" SG_ 289 MO_Solldrehz_Leerlauf 0;
BA_ "GenSigSwitchedByIgnition" SG_ 289 MO_Solldrehz_Leerlauf 0;
BA_ "GenSigSendType" SG_ 289 MO_StartStopp_StoppVorbereitung 0;
BA_ "GenSigSwitchedByIgnition" SG_ 289 MO_StartStopp_StoppVorbereitung 0;
BA_ "GenSigSendType" SG_ 289 MO_temporaere_Fahrerabwesenheit 0;
BA_ "GenSigSwitchedByIgnition" SG_ 289 MO_temporaere_Fahrerabwesenheit 0;
BA_ "GenSigSendType" SG_ 289 Motor_20_BZ 0;
BA_ "GenSigFuncType" SG_ 289 Motor_20_BZ 1;
BA_ "GenSigSwitchedByIgnition" SG_ 289 Motor_20_BZ 0;
BA_ "GenSigSendType" SG_ 289 Motor_20_CRC 0;
BA_ "GenSigFuncType" SG_ 289 Motor_20_CRC 2;
BA_ "GenSigSwitchedByIgnition" SG_ 289 Motor_20_CRC 0;
BA_ "GenSigSendType" SG_ 289 TSK_a_Soll_gradientenbegrenzt 0;
BA_ "GenSigStartValue" SG_ 289 TSK_a_Soll_gradientenbegrenzt 127;
BA_ "GenSigSwitchedByIgnition" SG_ 289 TSK_a_Soll_gradientenbegrenzt 0;
BA_ "GenSigSendType" SG_ 815 MO_Antriebsstrang_Warnung_HS 0;
BA_ "GenSigSwitchedByIgnition" SG_ 815 MO_Antriebsstrang_Warnung_HS 0;
BA_ "GenSigSendType" SG_ 815 MO_Anzeige_Betriebsmodus 0;
BA_ "GenSigSwitchedByIgnition" SG_ 815 MO_Anzeige_Betriebsmodus 0;
BA_ "GenSigSendType" SG_ 815 MO_Anzeige_Fahrbereitschaft 0;
BA_ "GenSigSwitchedByIgnition" SG_ 815 MO_Anzeige_Fahrbereitschaft 0;
BA_ "GenSigSendType" SG_ 815 MO_Anzeige_Rekuperation 0;
BA_ "GenSigSwitchedByIgnition" SG_ 815 MO_Anzeige_Rekuperation 0;
BA_ "GenSigSendType" SG_ 815 MO_Anzeige_Verbrauch_oE 0;
BA_ "GenSigSwitchedByIgnition" SG_ 815 MO_Anzeige_Verbrauch_oE 0;
BA_ "GenSigSendType" SG_ 815 MO_Boost_aktiv 0;
BA_ "GenSigSwitchedByIgnition" SG_ 815 MO_Boost_aktiv 0;
BA_ "GenSigSendType" SG_ 815 MO_Boost_verfuegbar 0;
BA_ "GenSigSwitchedByIgnition" SG_ 815 MO_Boost_verfuegbar 0;
BA_ "Fehlerwert" SG_ 815 MO_Boost_verfuegbar 255;
BA_ "GenSigSendType" SG_ 815 MO_Overboost 0;
BA_ "GenSigSwitchedByIgnition" SG_ 815 MO_Overboost 0;
BA_ "GenSigSendType" SG_ 815 PEA_Abschalttexte 0;
BA_ "GenSigSwitchedByIgnition" SG_ 815 PEA_Abschalttexte 0;
BA_ "GenSigSendType" SG_ 815 PEA_Ereignisanzeige 0;
BA_ "GenSigSwitchedByIgnition" SG_ 815 PEA_Ereignisanzeige 0;
BA_ "GenSigSendType" SG_ 815 PEA_Ereignisanzeige_temporaer 0;
BA_ "GenSigSwitchedByIgnition" SG_ 815 PEA_Ereignisanzeige_temporaer 0;
BA_ "GenSigSendType" SG_ 815 PEA_Fortschrittsanzeige 0;
BA_ "GenSigStartValue" SG_ 815 PEA_Fortschrittsanzeige 127;
BA_ "GenSigSwitchedByIgnition" SG_ 815 PEA_Fortschrittsanzeige 0;
BA_ "GenSigSendType" SG_ 815 PEA_Hinweis 0;
BA_ "GenSigSwitchedByIgnition" SG_ 815 PEA_Hinweis 0;
BA_ "GenSigSendType" SG_ 815 PEA_Zielgeschw 0;
BA_ "GenSigSwitchedByIgnition" SG_ 815 PEA_Zielgeschw 0;
BA_ "GenSigSendType" SG_ 815 PEA_Zielgeschw_Einheit 0;
BA_ "GenSigSwitchedByIgnition" SG_ 815 PEA_Zielgeschw_Einheit 0;
BA_ "GenSigSendType" SG_ 1423 FSA_Fehlerpfade_Initialisieren 0;
BA_ "GenSigSwitchedByIgnition" SG_ 1423 FSA_Fehlerpfade_Initialisieren 0;
BA_ "GenSigSendType" SG_ 1423 MO_FSA_Sensorheizung 0;
BA_ "GenSigSwitchedByIgnition" SG_ 1423 MO_FSA_Sensorheizung 0;
BA_ "GenSigSendType" SG_ 1423 MO_Getriebe_Oelalterung 0;
BA_ "GenSigSwitchedByIgnition" SG_ 1423 MO_Getriebe_Oelalterung 0;
BA_ "GenSigSendType" SG_ 1423 MO_ITM_Status 0;
BA_ "GenSigStartValue" SG_ 1423 MO_ITM_Status 14;
BA_ "GenSigSwitchedByIgnition" SG_ 1423 MO_ITM_Status 0;
BA_ "Fehlerwert" SG_ 1423 MO_ITM_Status 15;
BA_ "GenSigSendType" SG_ 1423 MO_KJS_LLK_Pos_Summe 0;
BA_ "GenSigStartValue" SG_ 1423 MO_KJS_LLK_Pos_Summe 14;
BA_ "GenSigSwitchedByIgnition" SG_ 1423 MO_KJS_LLK_Pos_Summe 0;
BA_ "GenSigSendType" SG_ 1423 MO_Kuehlmittel_Temp_Rohwert 0;
BA_ "GenSigStartValue" SG_ 1423 MO_Kuehlmittel_Temp_Rohwert 254;
BA_ "GenSigSwitchedByIgnition" SG_ 1423 MO_Kuehlmittel_Temp_Rohwert 0;
BA_ "Fehlerwert" SG_ 1423 MO_Kuehlmittel_Temp_Rohwert 255;
BA_ "GenSigSendType" SG_ 1423 MO_MMTR_Status 0;
BA_ "GenSigStartValue" SG_ 1423 MO_MMTR_Status 14;
BA_ "GenSigSwitchedByIgnition" SG_ 1423 MO_MMTR_Status 0;
BA_ "Fehlerwert" SG_ 1423 MO_MMTR_Status 15;
BA_ "GenSigSendType" SG_ 1423 MO_Oel_Temp_Radsatz 0;
BA_ "GenSigStartValue" SG_ 1423 MO_Oel_Temp_Radsatz 254;
BA_ "GenSigSwitchedByIgnition" SG_ 1423 MO_Oel_Temp_Radsatz 0;
BA_ "Fehlerwert" SG_ 1423 MO_Oel_Temp_Radsatz 255;
BA_ "GenSigSendType" SG_ 1423 MO_SABody_PosLe 0;
BA_ "GenSigSwitchedByIgnition" SG_ 1423 MO_SABody_PosLe 0;
BA_ "GenSigSendType" SG_ 1423 MO_SABody_PosRi 0;
BA_ "GenSigSwitchedByIgnition" SG_ 1423 MO_SABody_PosRi 0;
BA_ "GenSigSendType" SG_ 1423 MO_Tankdruck 0;
BA_ "GenSigStartValue" SG_ 1423 MO_Tankdruck 254;
BA_ "GenSigSwitchedByIgnition" SG_ 1423 MO_Tankdruck 0;
BA_ "Fehlerwert" SG_ 1423 MO_Tankdruck 255;
BA_ "GenSigSendType" SG_ 340 MO_Drehzahl_VM 0;
BA_ "GenSigSwitchedByIgnition" SG_ 340 MO_Drehzahl_VM 0;
BA_ "GenSigSendType" SG_ 340 MO_Fehlerstatus_Antrieb_FDR 0;
BA_ "GenSigSendType" SG_ 340 MO_IstMoment_VKM 0;
BA_ "GenSigStartValue" SG_ 340 MO_IstMoment_VKM 1022;
BA_ "GenSigSwitchedByIgnition" SG_ 340 MO_IstMoment_VKM 0;
BA_ "GenSigSendType" SG_ 340 MO_Mom_Begr_Schalt 0;
BA_ "GenSigStartValue" SG_ 340 MO_Mom_Begr_Schalt 1022;
BA_ "GenSigSwitchedByIgnition" SG_ 340 MO_Mom_Begr_Schalt 0;
BA_ "GenSigSendType" SG_ 340 MO_Mom_Begr_Schalt_Min 0;
BA_ "GenSigStartValue" SG_ 340 MO_Mom_Begr_Schalt_Min 1022;
BA_ "GenSigSwitchedByIgnition" SG_ 340 MO_Mom_Begr_Schalt_Min 0;
BA_ "GenSigSendType" SG_ 340 MO_Primaerachse_Anforderung 0;
BA_ "GenSigSwitchedByIgnition" SG_ 340 MO_Primaerachse_Anforderung 0;
BA_ "GenSigSendType" SG_ 340 Motor_28_BZ 0;
BA_ "GenSigFuncType" SG_ 340 Motor_28_BZ 1;
BA_ "GenSigSwitchedByIgnition" SG_ 340 Motor_28_BZ 0;
BA_ "GenSigSendType" SG_ 340 Motor_28_CRC 0;
BA_ "GenSigFuncType" SG_ 340 Motor_28_CRC 2;
BA_ "GenSigSwitchedByIgnition" SG_ 340 Motor_28_CRC 0;
BA_ "GenSigSendType" SG_ 1601 MO_Ansaugsystem 0;
BA_ "GenSigFuncType" SG_ 1601 MO_Ansaugsystem 8;
BA_ "GenSigSwitchedByIgnition" SG_ 1601 MO_Ansaugsystem 0;
BA_ "GenSigSendType" SG_ 1601 MO_Anzahl_Zyl 0;
BA_ "GenSigFuncType" SG_ 1601 MO_Anzahl_Zyl 8;
BA_ "GenSigSwitchedByIgnition" SG_ 1601 MO_Anzahl_Zyl 0;
BA_ "GenSigSendType" SG_ 1601 MO_Anzeige_StSt_gueltig 0;
BA_ "GenSigSwitchedByIgnition" SG_ 1601 MO_Anzeige_StSt_gueltig 0;
BA_ "GenSigSendType" SG_ 1601 MO_Code 0;
BA_ "GenSigSwitchedByIgnition" SG_ 1601 MO_Code 0;
BA_ "GenSigSendType" SG_ 1601 MO_DPF_verbaut 0;
BA_ "GenSigFuncType" SG_ 1601 MO_DPF_verbaut 8;
BA_ "GenSigSwitchedByIgnition" SG_ 1601 MO_DPF_verbaut 0;
BA_ "GenSigSendType" SG_ 1601 MO_Faktor_Momente_02 0;
BA_ "GenSigFuncType" SG_ 1601 MO_Faktor_Momente_02 8;
BA_ "GenSigSwitchedByIgnition" SG_ 1601 MO_Faktor_Momente_02 0;
BA_ "GenSigSendType" SG_ 1601 MO_Getriebe_Code 0;
BA_ "GenSigSwitchedByIgnition" SG_ 1601 MO_Getriebe_Code 0;
BA_ "GenSigSendType" SG_ 1601 MO_Hubraum 0;
BA_ "GenSigFuncType" SG_ 1601 MO_Hubraum 8;
BA_ "GenSigSwitchedByIgnition" SG_ 1601 MO_Hubraum 0;
BA_ "GenSigSendType" SG_ 1601 MO_Hybridfahrzeug 0;
BA_ "GenSigFuncType" SG_ 1601 MO_Hybridfahrzeug 8;
BA_ "GenSigSwitchedByIgnition" SG_ 1601 MO_Hybridfahrzeug 0;
BA_ "GenSigSendType" SG_ 1601 MO_Kraftstoffart 0;
BA_ "GenSigFuncType" SG_ 1601 MO_Kraftstoffart 8;
BA_ "GenSigSwitchedByIgnition" SG_ 1601 MO_Kraftstoffart 0;
BA_ "GenSigSendType" SG_ 1601 MO_Leistung 0;
BA_ "GenSigSwitchedByIgnition" SG_ 1601 MO_Leistung 0;
BA_ "GenSigSendType" SG_ 1601 MO_OBD_Typ 0;
BA_ "GenSigSwitchedByIgnition" SG_ 1601 MO_OBD_Typ 0;
BA_ "GenSigSendType" SG_ 1601 MO_StartStopp_Codiert 0;
BA_ "GenSigFuncType" SG_ 1601 MO_StartStopp_Codiert 8;
BA_ "GenSigSwitchedByIgnition" SG_ 1601 MO_StartStopp_Codiert 0;
BA_ "GenSigSendType" SG_ 1601 Motor_Code_01_BZ 0;
BA_ "GenSigFuncType" SG_ 1601 Motor_Code_01_BZ 1;
BA_ "GenSigSwitchedByIgnition" SG_ 1601 Motor_Code_01_BZ 0;
BA_ "GenSigSendType" SG_ 1601 Motor_Code_01_CRC 0;
BA_ "GenSigFuncType" SG_ 1601 Motor_Code_01_CRC 2;
BA_ "GenSigSwitchedByIgnition" SG_ 1601 Motor_Code_01_CRC 0;
BA_ "GenSigSendType" SG_ 1601 TSK_Codierung 0;
BA_ "GenSigStartValue" SG_ 1601 TSK_Codierung 7;
BA_ "GenSigSwitchedByIgnition" SG_ 1601 TSK_Codierung 0;
BA_ "GenSigSendType" SG_ 305 Ladezustand_02 0;
BA_ "GenSigStartValue" SG_ 305 Ladezustand_02 254;
BA_ "GenSigSwitchedByIgnition" SG_ 305 Ladezustand_02 0;
BA_ "Fehlerwert" SG_ 305 Ladezustand_02 255;
BA_ "GenSigSendType" SG_ 305 MO_ePerformance 0;
BA_ "GenSigSwitchedByIgnition" SG_ 305 MO_ePerformance 0;
BA_ "Fehlerwert" SG_ 305 MO_ePerformance 255;
BA_ "GenSigSendType" SG_ 305 MO_ePowermeter 0;
BA_ "GenSigSwitchedByIgnition" SG_ 305 MO_ePowermeter 0;
BA_ "GenSigSendType" SG_ 305 MO_Powermeter 0;
BA_ "GenSigStartValue" SG_ 305 MO_Powermeter 4093;
BA_ "GenSigSwitchedByIgnition" SG_ 305 MO_Powermeter 0;
BA_ "GenSigSendType" SG_ 305 MO_Powermeter_Elm 0;
BA_ "GenSigStartValue" SG_ 305 MO_Powermeter_Elm 128;
BA_ "GenSigSwitchedByIgnition" SG_ 305 MO_Powermeter_Elm 0;
BA_ "GenSigSendType" SG_ 305 MO_Powermeter_Elm_02 0;
BA_ "GenSigStartValue" SG_ 305 MO_Powermeter_Elm_02 4094;
BA_ "GenSigSwitchedByIgnition" SG_ 305 MO_Powermeter_Elm_02 0;
BA_ "GenSigSendType" SG_ 305 MO_Zust_Antrieb 0;
BA_ "GenSigSwitchedByIgnition" SG_ 305 MO_Zust_Antrieb 0;
BA_ "GenSigSendType" SG_ 305 MO_Zust_Betriebsstrategie 0;
BA_ "GenSigSwitchedByIgnition" SG_ 305 MO_Zust_Betriebsstrategie 0;
BA_ "GenSigSendType" SG_ 394 MO_Ablaufstatus 0;
BA_ "GenSigSwitchedByIgnition" SG_ 394 MO_Ablaufstatus 0;
BA_ "Fehlerwert" SG_ 394 MO_Ablaufstatus 15;
BA_ "GenSigSendType" SG_ 394 MO_Ablaufstrg_Betriebszustand 0;
BA_ "GenSigSwitchedByIgnition" SG_ 394 MO_Ablaufstrg_Betriebszustand 0;
BA_ "Fehlerwert" SG_ 394 MO_Ablaufstrg_Betriebszustand 7;
BA_ "GenSigSendType" SG_ 394 MO_Ablaufstrg_Kraftschluss2_Ist 0;
BA_ "GenSigSwitchedByIgnition" SG_ 394 MO_Ablaufstrg_Kraftschluss2_Ist 0;
BA_ "GenSigSendType" SG_ 394 MO_Ablaufstrg_Kraftschluss2_Ziel 0;
BA_ "GenSigSwitchedByIgnition" SG_ 394 MO_Ablaufstrg_Kraftschluss2_Ziel 0;
BA_ "GenSigSendType" SG_ 394 MO_Ablaufstrg_Kraftschluss_Ist 0;
BA_ "GenSigSwitchedByIgnition" SG_ 394 MO_Ablaufstrg_Kraftschluss_Ist 0;
BA_ "GenSigSendType" SG_ 394 MO_Ablaufstrg_Kraftschluss_Ziel 0;
BA_ "GenSigSwitchedByIgnition" SG_ 394 MO_Ablaufstrg_Kraftschluss_Ziel 0;
BA_ "GenSigSendType" SG_ 394 MO_Ablaufstrg_Zustand_K0_Ist 0;
BA_ "GenSigSwitchedByIgnition" SG_ 394 MO_Ablaufstrg_Zustand_K0_Ist 0;
BA_ "GenSigSendType" SG_ 394 MO_Ablaufstrg_Zustand_K0_Ziel 0;
BA_ "GenSigSwitchedByIgnition" SG_ 394 MO_Ablaufstrg_Zustand_K0_Ziel 0;
BA_ "GenSigSendType" SG_ 394 MO_Ablaufstrg_Zustand_VKM_Ist 0;
BA_ "GenSigSwitchedByIgnition" SG_ 394 MO_Ablaufstrg_Zustand_VKM_Ist 0;
BA_ "GenSigSendType" SG_ 394 MO_Ablaufstrg_Zustand_VKM_Ziel 0;
BA_ "GenSigSwitchedByIgnition" SG_ 394 MO_Ablaufstrg_Zustand_VKM_Ziel 0;
BA_ "GenSigSendType" SG_ 394 MO_Abstellposition_02 0;
BA_ "GenSigStartValue" SG_ 394 MO_Abstellposition_02 255;
BA_ "GenSigSwitchedByIgnition" SG_ 394 MO_Abstellposition_02 0;
BA_ "GenSigSendType" SG_ 394 MO_Auth_Aufforderung_WFS 0;
BA_ "GenSigSwitchedByIgnition" SG_ 394 MO_Auth_Aufforderung_WFS 0;
BA_ "GenSigSendType" SG_ 394 MO_HYB_Adaption_aktiv 0;
BA_ "GenSigSendType" SG_ 394 MO_HYB_E_Faktor 0;
BA_ "GenSigSwitchedByIgnition" SG_ 394 MO_HYB_E_Faktor 0;
BA_ "GenSigSendType" SG_ 394 MO_HYB_EMode_Info 0;
BA_ "GenSigSwitchedByIgnition" SG_ 394 MO_HYB_EMode_Info 0;
BA_ "GenSigSendType" SG_ 394 MO_HYB_LowSpeedModus 0;
BA_ "GenSigSwitchedByIgnition" SG_ 394 MO_HYB_LowSpeedModus 0;
BA_ "GenSigSendType" SG_ 394 MO_HYB_Stoppmodus 0;
BA_ "GenSigSendType" SG_ 394 MO_Mom_Freiheit_Sekundaerachse 0;
BA_ "GenSigSwitchedByIgnition" SG_ 394 MO_Mom_Freiheit_Sekundaerachse 0;
BA_ "GenSigSendType" SG_ 394 MO_Nachlaufzeit_Kuehlerluefter 0;
BA_ "GenSigSwitchedByIgnition" SG_ 394 MO_Nachlaufzeit_Kuehlerluefter 0;
BA_ "GenSigSendType" SG_ 394 MO_Start_Art 3;
BA_ "GenSigSwitchedByIgnition" SG_ 394 MO_Start_Art 0;
BA_ "GenSigSendType" SG_ 394 MO_Start_Dynamik 0;
BA_ "GenSigSwitchedByIgnition" SG_ 394 MO_Start_Dynamik 0;
BA_ "GenSigSendType" SG_ 394 MO_Tankklappensteuerung 3;
BA_ "GenSigSwitchedByIgnition" SG_ 394 MO_Tankklappensteuerung 0;
BA_ "GenSigSendType" SG_ 234 Motor_TS_03_BZ 0;
BA_ "GenSigFuncType" SG_ 234 Motor_TS_03_BZ 1;
BA_ "GenSigSwitchedByIgnition" SG_ 234 Motor_TS_03_BZ 0;
BA_ "GenSigSendType" SG_ 234 Motor_TS_03_CRC 0;
BA_ "GenSigFuncType" SG_ 234 Motor_TS_03_CRC 2;
BA_ "GenSigSwitchedByIgnition" SG_ 234 Motor_TS_03_CRC 0;
BA_ "GenSigSendType" SG_ 234 TS_Allrad_Anteil_sek 0;
BA_ "GenSigStartValue" SG_ 234 TS_Allrad_Anteil_sek 510;
BA_ "GenSigSwitchedByIgnition" SG_ 234 TS_Allrad_Anteil_sek 0;
BA_ "Fehlerwert" SG_ 234 TS_Allrad_Anteil_sek 511;
BA_ "GenSigSendType" SG_ 234 TS_MomRad_Ist 0;
BA_ "GenSigStartValue" SG_ 234 TS_MomRad_Ist 8190;
BA_ "GenSigSwitchedByIgnition" SG_ 234 TS_MomRad_Ist 0;
BA_ "GenSigSendType" SG_ 234 TS_MomRad_Ist_sek 0;
BA_ "GenSigStartValue" SG_ 234 TS_MomRad_Ist_sek 8190;
BA_ "GenSigSwitchedByIgnition" SG_ 234 TS_MomRad_Ist_sek 0;
BA_ "GenSigSendType" SG_ 234 TS_MomRad_verfuegb_maxReku_Summe 0;
BA_ "GenSigStartValue" SG_ 234 TS_MomRad_verfuegb_maxReku_Summe 4094;
BA_ "GenSigSwitchedByIgnition" SG_ 234 TS_MomRad_verfuegb_maxReku_Summe 0;
BA_ "GenSigSendType" SG_ 234 TS_Status_MomRad_Ist 0;
BA_ "GenSigStartValue" SG_ 234 TS_Status_MomRad_Ist 2;
BA_ "GenSigSwitchedByIgnition" SG_ 234 TS_Status_MomRad_Ist 0;
BA_ "GenSigSendType" SG_ 849 ASW_Warnung_HL 3;
BA_ "GenSigSwitchedByIgnition" SG_ 849 ASW_Warnung_HL 0;
BA_ "GenSigSendType" SG_ 849 MRR_HL_ASW_Modus 3;
BA_ "GenSigStartValue" SG_ 849 MRR_HL_ASW_Modus 4;
BA_ "GenSigSwitchedByIgnition" SG_ 849 MRR_HL_ASW_Modus 0;
BA_ "GenSigSendType" SG_ 849 MRR_HL_ASW_Status 3;
BA_ "GenSigSwitchedByIgnition" SG_ 849 MRR_HL_ASW_Status 0;
BA_ "Fehlerwert" SG_ 849 MRR_HL_ASW_Status 2;
BA_ "GenSigSendType" SG_ 849 MRR_HL_ASW_System_aktiv 0;
BA_ "GenSigSwitchedByIgnition" SG_ 849 MRR_HL_ASW_System_aktiv 0;
BA_ "GenSigSendType" SG_ 849 MRR_HL_Blindness_Status 0;
BA_ "GenSigSendType" SG_ 849 MRR_HL_Kalibriermodus 3;
BA_ "GenSigSendType" SG_ 849 MRR_HL_Performance_Status 3;
BA_ "GenSigSendType" SG_ 849 MRR_HL_QualFaktorAutoKalib 3;
BA_ "GenSigSendType" SG_ 849 MRR_HL_Sensor_Fehler 3;
BA_ "GenSigSwitchedByIgnition" SG_ 849 MRR_HL_Sensor_Fehler 0;
BA_ "GenSigSendType" SG_ 849 MRR_HL_Sensor_Kl_Status 3;
BA_ "GenSigSwitchedByIgnition" SG_ 849 MRR_HL_Sensor_Kl_Status 0;
BA_ "GenSigSendType" SG_ 2463978596 MRR_HL_Info1 3;
BA_ "GenSigSwitchedByIgnition" SG_ 2463978596 MRR_HL_Info1 0;
BA_ "GenSigSendType" SG_ 848 MRR_HR_ASW_System_aktiv 0;
BA_ "GenSigSwitchedByIgnition" SG_ 848 MRR_HR_ASW_System_aktiv 0;
BA_ "GenSigSendType" SG_ 848 MRR_HR_Blindness_Anf 3;
BA_ "GenSigSwitchedByIgnition" SG_ 848 MRR_HR_Blindness_Anf 0;
BA_ "GenSigSendType" SG_ 848 MRR_HR_Blindness_Status 3;
BA_ "GenSigSendType" SG_ 848 MRR_HR_Info_Anf 3;
BA_ "GenSigSwitchedByIgnition" SG_ 848 MRR_HR_Info_Anf 0;
BA_ "GenSigSendType" SG_ 848 MRR_HR_Kalibriermodus 3;
BA_ "GenSigSendType" SG_ 848 MRR_HR_LED_RelHelligkeit 0;
BA_ "GenSigSwitchedByIgnition" SG_ 848 MRR_HR_LED_RelHelligkeit 0;
BA_ "GenSigSendType" SG_ 848 MRR_HR_Performance_Status 3;
BA_ "GenSigSendType" SG_ 848 MRR_HR_QualFaktorAutoKalib 3;
BA_ "GenSigSendType" SG_ 1696 NV_Akt_Status_MMI 3;
BA_ "GenSigStartValue" SG_ 1696 NV_Akt_Status_MMI 3;
BA_ "GenSigSendType" SG_ 1696 NV_aktiv 3;
BA_ "GenSigSendType" SG_ 1696 NV_Akustik_deaktiviert_Icon 3;
BA_ "GenSigSendType" SG_ 1696 NV_Anf_Prefill 3;
BA_ "GenSigSendType" SG_ 1696 NV_AnforderungBildaufschaltung 3;
BA_ "GenSigSendType" SG_ 1696 NV_FAS_Fkt_Status 0;
BA_ "Fehlerwert" SG_ 1696 NV_FAS_Fkt_Status 3;
BA_ "GenSigSendType" SG_ 1696 NV_FGM_deaktiviert_Icon 3;
BA_ "GenSigSendType" SG_ 1696 NV_Gong 3;
BA_ "GenSigSendType" SG_ 1696 NV_HBA_Parameter 3;
BA_ "GenSigSendType" SG_ 1696 NV_Hinweise 3;
BA_ "GenSigSendType" SG_ 1696 NV_LED_Leiste 3;
BA_ "GenSigSendType" SG_ 1696 NV_Markierungslicht_links 3;
BA_ "GenSigSendType" SG_ 1696 NV_Markierungslicht_rechts 3;
BA_ "GenSigSendType" SG_ 1696 NV_Piktogramm_aktiv 3;
BA_ "GenSigSendType" SG_ 1696 NV_PreSense_Modus_System 3;
BA_ "GenSigSendType" SG_ 1696 NV_PreSense_Modus_Warnung 3;
BA_ "GenSigSendType" SG_ 1696 NV_PreSense_Status 3;
BA_ "GenSigSendType" SG_ 1696 NV_Symbol 3;
BA_ "GenSigSendType" SG_ 1696 NV_Symbol_Tierwarnung 3;
BA_ "GenSigSendType" SG_ 1696 NV_Texte 3;
BA_ "GenSigActiveRepetitions" SG_ 2600468496 NM_Gateway_CAB 3;
BA_ "GenSigSendType" SG_ 2600468496 NM_Gateway_CAB 4;
BA_ "GenSigFuncType" SG_ 2600468496 NM_Gateway_CAB 16;
BA_ "GenSigSwitchedByIgnition" SG_ 2600468496 NM_Gateway_CAB 0;
BA_ "GenSigSendType" SG_ 2600468496 NM_Gateway_Car_Wakeup 3;
BA_ "GenSigSwitchedByIgnition" SG_ 2600468496 NM_Gateway_Car_Wakeup 0;
BA_ "GenSigSwitchedByIgnition" SG_ 2600468496 NM_Gateway_CBV_AWB 0;
BA_ "GenSigSwitchedByIgnition" SG_ 2600468496 NM_Gateway_CBV_CRI 0;
BA_ "GenSigSwitchedByIgnition" SG_ 2600468496 NM_Gateway_NM_aktiv_Buskopplung 0;
BA_ "GenSigSwitchedByIgnition" SG_ 2600468496 NM_Gateway_NM_aktiv_Connect 0;
BA_ "GenSigSwitchedByIgnition" SG_ 2600468496 NM_Gateway_NM_aktiv_CWU 0;
BA_ "GenSigSwitchedByIgnition" SG_ 2600468496 NM_Gateway_NM_aktiv_Diagnose 0;
BA_ "GenSigSwitchedByIgnition" SG_ 2600468496 NM_Gateway_NM_aktiv_EM 0;
BA_ "GenSigSwitchedByIgnition" SG_ 2600468496 NM_Gateway_NM_aktiv_FC 0;
BA_ "GenSigSwitchedByIgnition" SG_ 2600468496 NM_Gateway_NM_aktiv_Fremdladung 0;
BA_ "GenSigSwitchedByIgnition" SG_ 2600468496 NM_Gateway_NM_aktiv_KL15 0;
BA_ "GenSigSwitchedByIgnition" SG_ 2600468496 NM_Gateway_NM_aktiv_LIN2 0;
BA_ "GenSigSwitchedByIgnition" SG_ 2600468496 NM_Gateway_NM_aktiv_OBDC 0;
BA_ "GenSigSwitchedByIgnition" SG_ 2600468496 NM_Gateway_NM_aktiv_Tmin 0;
BA_ "GenSigSwitchedByIgnition" SG_ 2600468496 NM_Gateway_NM_State 0;
BA_ "GenSigStartValue" SG_ 2600468496 NM_Gateway_SNI 16;
BA_ "GenSigSwitchedByIgnition" SG_ 2600468496 NM_Gateway_SNI 0;
BA_ "GenSigSwitchedByIgnition" SG_ 2600468496 NM_Gateway_UDS_CC 0;
BA_ "GenSigActiveRepetitions" SG_ 2600468519 NM_Nightvision_CAB 3;
BA_ "GenSigSendType" SG_ 2600468519 NM_Nightvision_CAB 4;
BA_ "GenSigSendType" SG_ 2600468519 NM_Nightvision_Car_Wakeup 3;
BA_ "GenSigFuncType" SG_ 2600468519 NM_Nightvision_CBV_CRI 8;
BA_ "GenSigStartValue" SG_ 2600468519 NM_Nightvision_SNI 39;
BA_ "GenSigActiveRepetitions" SG_ 2600468491 NM_RDK_CAB 3;
BA_ "GenSigSendType" SG_ 2600468491 NM_RDK_CAB 4;
BA_ "GenSigSwitchedByIgnition" SG_ 2600468491 NM_RDK_CAB 0;
BA_ "GenSigSendType" SG_ 2600468491 NM_RDK_Car_Wakeup 3;
BA_ "GenSigSwitchedByIgnition" SG_ 2600468491 NM_RDK_Car_Wakeup 0;
BA_ "GenSigSwitchedByIgnition" SG_ 2600468491 NM_RDK_CBV_AWB 0;
BA_ "GenSigSwitchedByIgnition" SG_ 2600468491 NM_RDK_CBV_CRI 0;
BA_ "GenSigSwitchedByIgnition" SG_ 2600468491 NM_RDK_NM_aktiv_Diagnose 0;
BA_ "GenSigSwitchedByIgnition" SG_ 2600468491 NM_RDK_NM_aktiv_KL15 0;
BA_ "GenSigSwitchedByIgnition" SG_ 2600468491 NM_RDK_NM_aktiv_Tmin 0;
BA_ "GenSigSwitchedByIgnition" SG_ 2600468491 NM_RDK_NM_State 0;
BA_ "GenSigStartValue" SG_ 2600468491 NM_RDK_SNI 11;
BA_ "GenSigSwitchedByIgnition" SG_ 2600468491 NM_RDK_SNI 0;
BA_ "GenSigSwitchedByIgnition" SG_ 2600468491 NM_RDK_UDS_CC 0;
BA_REL_ "GenSigTimeoutTime" BU_SG_REL_ AEM SG_ 1600 MO_Oel_Temp 3200;
BA_REL_ "GenSigTimeoutTime" BU_SG_REL_ AEM SG_ 1600 MO_Kuehlmittel_Temp 3200;
BA_REL_ "GenSigTimeoutTime" BU_SG_REL_ AEM SG_ 167 MO_Mom_Ist_Summe 500;
BA_REL_ "GenSigTimeoutTime" BU_SG_REL_ AEM SG_ 167 MO_QBit_Motormomente 500;
BA_REL_ "GenSigTimeoutTime" BU_SG_REL_ AEM SG_ 168 MO_QBit_Drehzahl_01 500;
BA_REL_ "GenSigTimeoutTime" BU_SG_REL_ AEM SG_ 168 MO_Drehzahl_01 500;
BA_REL_ "GenSigTimeoutTime" BU_SG_REL_ AEM SG_ 958 MO_StartStopp_Status 1000;
BA_REL_ "GenSigTimeoutTime" BU_SG_REL_ AEM SG_ 958 MO_StartStopp_Wiederstart 1000;
BA_REL_ "GenSigTimeoutTime" BU_SG_REL_ AEM SG_ 958 MO_StartStopp_Motorstopp 1000;
BA_REL_ "GenSigTimeoutTime" BU_SG_REL_ AEM SG_ 958 MO_Kl_75 1000;
BA_REL_ "GenSigTimeoutTime" BU_SG_REL_ AEM SG_ 958 MO_Kl_50 1000;
BA_REL_ "GenSigTimeoutTime" BU_SG_REL_ AEM SG_ 958 MO_StartStopp_Fahrerwunsch 1000;
BA_REL_ "GenSigTimeoutTime" BU_SG_REL_ AEM SG_ 958 MO_Motor_laeuft 1000;
BA_REL_ "GenSigTimeoutTime" BU_SG_REL_ AEM SG_ 958 MO_Zylinderabschaltung 1000;
BA_REL_ "GenSigTimeoutTime" BU_SG_REL_ AEM SG_ 340 MO_Drehzahl_VM 2000;
BA_REL_ "GenSigTimeoutTime" BU_SG_REL_ AEM SG_ 1601 MO_Faktor_Momente_02 5000;
BA_REL_ "GenSigTimeoutTime" BU_SG_REL_ E_Sound SG_ 167 MO_Mom_Ist_Summe 500;
BA_REL_ "GenSigTimeoutTime" BU_SG_REL_ E_Sound SG_ 168 MO_Drehzahl_01 500;
BA_REL_ "GenSigTimeoutTime" BU_SG_REL_ E_Sound SG_ 958 MO_Gangposition 1000;
BA_REL_ "GenSigTimeoutTime" BU_SG_REL_ E_Sound SG_ 958 MO_HYB_Fahrbereitschaft 1000;
BA_REL_ "GenSigTimeoutTime" BU_SG_REL_ E_Sound SG_ 958 MO_HYB_VM_aktiv 1000;
BA_REL_ "GenSigTimeoutTime" BU_SG_REL_ E_Sound SG_ 289 MO_Fahrpedalrohwert_01 500;
BA_REL_ "GenSigTimeoutTime" BU_SG_REL_ E_Sound SG_ 815 MO_Boost_aktiv 500;
BA_REL_ "GenSigTimeoutTime" BU_SG_REL_ E_Sound SG_ 1601 MO_Code 5000;
BA_REL_ "GenSigTimeoutTime" BU_SG_REL_ E_Sound SG_ 234 TS_MomRad_Ist_sek 500;
BA_REL_ "GenSigTimeoutTime" BU_SG_REL_ E_Sound SG_ 2600468496 NM_Gateway_SNI 2000;
BA_REL_ "GenSigTimeoutTime" BU_SG_REL_ E_Sound SG_ 2600468496 NM_Gateway_CBV_CRI 2000;
BA_REL_ "GenSigTimeoutTime" BU_SG_REL_ E_Sound SG_ 2600468496 NM_Gateway_CAB 2000;
BA_REL_ "GenSigTimeoutTime" BU_SG_REL_ FLA SG_ 958 MO_StartStopp_Wiederstart 1000;
BA_REL_ "GenSigTimeoutTime" BU_SG_REL_ FLA SG_ 958 MO_Kl_75 1000;
BA_REL_ "GenSigTimeoutTime" BU_SG_REL_ FLA SG_ 958 MO_Gangposition 1000;
BA_REL_ "GenSigTimeoutTime" BU_SG_REL_ Gateway SG_ 2600468519 NM_Nightvision_SNI 2000;
BA_REL_ "GenSigTimeoutTime" BU_SG_REL_ Gateway SG_ 2600468519 NM_Nightvision_CBV_AWB 2000;
BA_REL_ "GenSigTimeoutTime" BU_SG_REL_ Gateway SG_ 2600468519 NM_Nightvision_CBV_CRI 2000;
BA_REL_ "GenSigTimeoutTime" BU_SG_REL_ Gateway SG_ 2600468519 NM_Nightvision_Car_Wakeup 2000;
BA_REL_ "GenSigTimeoutTime" BU_SG_REL_ Gateway SG_ 2600468519 NM_Nightvision_CAB 2000;
BA_REL_ "GenSigTimeoutTime" BU_SG_REL_ Gateway SG_ 2600468491 NM_RDK_SNI 2000;
BA_REL_ "GenSigTimeoutTime" BU_SG_REL_ Gateway SG_ 2600468491 NM_RDK_CBV_AWB 2000;
BA_REL_ "GenSigTimeoutTime" BU_SG_REL_ Gateway SG_ 2600468491 NM_RDK_CBV_CRI 2000;
BA_REL_ "GenSigTimeoutTime" BU_SG_REL_ Gateway SG_ 2600468491 NM_RDK_Car_Wakeup 2000;
BA_REL_ "GenSigTimeoutTime" BU_SG_REL_ Gateway SG_ 2600468491 NM_RDK_CAB 2000;
BA_REL_ "GenSigTimeoutTime" BU_SG_REL_ Gateway_PAG SG_ 2600468519 NM_Nightvision_SNI 2000;
BA_REL_ "GenSigTimeoutTime" BU_SG_REL_ Gateway_PAG SG_ 2600468519 NM_Nightvision_CBV_AWB 2000;
BA_REL_ "GenSigTimeoutTime" BU_SG_REL_ Gateway_PAG SG_ 2600468519 NM_Nightvision_CBV_CRI 2000;
BA_REL_ "GenSigTimeoutTime" BU_SG_REL_ Gateway_PAG SG_ 2600468519 NM_Nightvision_CAB 2000;
BA_REL_ "GenSigTimeoutTime" BU_SG_REL_ Gateway_PAG SG_ 2600468491 NM_RDK_SNI 2000;
BA_REL_ "GenSigTimeoutTime" BU_SG_REL_ Gateway_PAG SG_ 2600468491 NM_RDK_CBV_AWB 2000;
BA_REL_ "GenSigTimeoutTime" BU_SG_REL_ Gateway_PAG SG_ 2600468491 NM_RDK_CBV_CRI 2000;
BA_REL_ "GenSigTimeoutTime" BU_SG_REL_ Gateway_PAG SG_ 2600468491 NM_RDK_Car_Wakeup 2000;
BA_REL_ "GenSigTimeoutTime" BU_SG_REL_ Gateway_PAG SG_ 2600468491 NM_RDK_CAB 2000;
BA_REL_ "GenSigTimeoutTime" BU_SG_REL_ ISE SG_ 167 MO_Mom_Ist_Summe 500;
BA_REL_ "GenSigTimeoutTime" BU_SG_REL_ ISE SG_ 168 MO_Drehzahl_01 500;
BA_REL_ "GenSigTimeoutTime" BU_SG_REL_ ISE SG_ 958 MO_Gangposition 1000;
BA_REL_ "GenSigTimeoutTime" BU_SG_REL_ ISE SG_ 958 MO_HYB_Fahrbereitschaft 1000;
BA_REL_ "GenSigTimeoutTime" BU_SG_REL_ ISE SG_ 958 MO_HYB_VM_aktiv 1000;
BA_REL_ "GenSigTimeoutTime" BU_SG_REL_ ISE SG_ 289 MO_Fahrpedalrohwert_01 500;
BA_REL_ "GenSigTimeoutTime" BU_SG_REL_ ISE SG_ 815 MO_Boost_aktiv 500;
BA_REL_ "GenSigTimeoutTime" BU_SG_REL_ ISE SG_ 1601 MO_Code 5000;
BA_REL_ "GenSigTimeoutTime" BU_SG_REL_ ISE SG_ 234 TS_MomRad_Ist_sek 500;
BA_REL_ "GenSigTimeoutTime" BU_SG_REL_ ISE SG_ 2600468496 NM_Gateway_SNI 2000;
BA_REL_ "GenSigTimeoutTime" BU_SG_REL_ ISE SG_ 2600468496 NM_Gateway_CBV_CRI 2000;
BA_REL_ "GenSigTimeoutTime" BU_SG_REL_ ISE SG_ 2600468496 NM_Gateway_CAB 2000;
BA_REL_ "GenSigTimeoutTime" BU_SG_REL_ NightVision SG_ 917 LWR_Hoehenwert_VL 1000;
BA_REL_ "GenSigTimeoutTime" BU_SG_REL_ NightVision SG_ 917 LWR_Hoehenwert_HL 1000;
BA_REL_ "GenSigTimeoutTime" BU_SG_REL_ NightVision SG_ 917 LWR_AFS_Grundeinstellung 1000;
BA_REL_ "GenSigTimeoutTime" BU_SG_REL_ NightVision SG_ 1153 Nav_FoD_Status 5000;
BA_REL_ "GenSigTimeoutTime" BU_SG_REL_ NightVision SG_ 958 MO_StartStopp_Motorstopp 1000;
BA_REL_ "GenSigTimeoutTime" BU_SG_REL_ NightVision SG_ 958 MO_Gangposition 1000;
BA_REL_ "GenSigTimeoutTime" BU_SG_REL_ NightVision SG_ 2600468496 NM_Gateway_SNI 2000;
BA_REL_ "GenSigTimeoutTime" BU_SG_REL_ NightVision SG_ 2600468496 NM_Gateway_CBV_CRI 2000;
BA_REL_ "GenSigTimeoutTime" BU_SG_REL_ NightVision SG_ 2600468496 NM_Gateway_CAB 2000;
BA_REL_ "GenSigTimeoutTime" BU_SG_REL_ NightVision SG_ 2600468491 NM_RDK_SNI 2000;
BA_REL_ "GenSigTimeoutTime" BU_SG_REL_ NightVision SG_ 2600468491 NM_RDK_CBV_CRI 2000;
BA_REL_ "GenSigTimeoutTime" BU_SG_REL_ NightVision SG_ 2600468491 NM_RDK_CAB 2000;
BA_REL_ "GenSigTimeoutTime" BU_SG_REL_ RDK SG_ 2600468496 NM_Gateway_SNI 2000;
BA_REL_ "GenSigTimeoutTime" BU_SG_REL_ RDK SG_ 2600468496 NM_Gateway_CBV_CRI 2000;
BA_REL_ "GenSigTimeoutTime" BU_SG_REL_ RDK SG_ 2600468496 NM_Gateway_CAB 2000;
BA_REL_ "GenSigTimeoutTime" BU_SG_REL_ RDK SG_ 2600468519 NM_Nightvision_SNI 2000;
BA_REL_ "GenSigTimeoutTime" BU_SG_REL_ RDK SG_ 2600468519 NM_Nightvision_CBV_CRI 2000;
BA_REL_ "GenSigTimeoutTime" BU_SG_REL_ RDK SG_ 2600468519 NM_Nightvision_CAB 2000;
BA_REL_ "GenSigTimeoutTime" BU_SG_REL_ SAK SG_ 167 MO_Mom_Ist_Summe 500;
BA_REL_ "GenSigTimeoutTime" BU_SG_REL_ SAK SG_ 168 MO_Drehzahl_01 500;
BA_REL_ "GenSigTimeoutTime" BU_SG_REL_ SAK SG_ 958 MO_Kuppl_schalter 1000;
BA_REL_ "GenSigTimeoutTime" BU_SG_REL_ SAK SG_ 958 MO_Zylinderabschaltung 1000;
BA_REL_ "GenSigTimeoutTime" BU_SG_REL_ SAK SG_ 958 MO_HYB_VM_aktiv 1000;
BA_REL_ "GenSigTimeoutTime" BU_SG_REL_ SAK SG_ 289 MO_Fahrpedalrohwert_01 500;
BA_REL_ "GenSigTimeoutTime" BU_SG_REL_ SAK SG_ 1601 MO_Code 5000;
BA_REL_ "GenSigTimeoutTime" BU_SG_REL_ SAK SG_ 1601 MO_Leistung 5000;
BA_REL_ "GenSigTimeoutTime" BU_SG_REL_ SAK SG_ 305 MO_Powermeter 500;
BA_REL_ "GenSigTimeoutTime" BU_SG_REL_ SAK2 SG_ 167 MO_Mom_Ist_Summe 500;
BA_REL_ "GenSigTimeoutTime" BU_SG_REL_ SAK2 SG_ 168 MO_Drehzahl_01 500;
BA_REL_ "GenSigTimeoutTime" BU_SG_REL_ SAK2 SG_ 958 MO_Gangposition 1000;
BA_REL_ "GenSigTimeoutTime" BU_SG_REL_ SAK2 SG_ 958 MO_Kuppl_schalter 1000;
BA_REL_ "GenSigTimeoutTime" BU_SG_REL_ SAK2 SG_ 958 MO_Zylinderabschaltung 1000;
BA_REL_ "GenSigTimeoutTime" BU_SG_REL_ SAK2 SG_ 958 MO_HYB_VM_aktiv 1000;
BA_REL_ "GenSigTimeoutTime" BU_SG_REL_ SAK2 SG_ 289 MO_Fahrpedalrohwert_01 500;
BA_REL_ "GenSigTimeoutTime" BU_SG_REL_ SAK2 SG_ 1601 MO_Code 5000;
BA_REL_ "GenSigTimeoutTime" BU_SG_REL_ SAK2 SG_ 1601 MO_Leistung 5000;
BA_REL_ "GenSigTimeoutTime" BU_SG_REL_ SAK2 SG_ 305 MO_Powermeter 500;
BA_REL_ "GenSigTimeoutTime" BU_SG_REL_ SCR SG_ 168 MO_QBit_Drehzahl_01 500;
BA_REL_ "GenSigTimeoutTime" BU_SG_REL_ SCR SG_ 168 MO_Drehzahl_01 500;
BA_REL_ "GenSigTimeoutTime" BU_SG_REL_ SCR SG_ 958 MO_StartStopp_Status 1000;
BA_REL_ "GenSigTimeoutTime" BU_SG_REL_ SCR SG_ 958 MO_StartStopp_Wiederstart 1000;
BA_REL_ "GenSigTimeoutTime" BU_SG_REL_ SCR SG_ 958 MO_StartStopp_Motorstopp 1000;
BA_REL_ "GenSigTimeoutTime" BU_SG_REL_ SCR SG_ 958 MO_Kl_75 1000;
BA_REL_ "GenSigTimeoutTime" BU_SG_REL_ SCR SG_ 958 MO_StartStopp_Fahrerwunsch 1000;
BA_REL_ "GenSigTimeoutTime" BU_SG_REL_ SCR SG_ 958 MO_QBit_KL_75 1000;
BA_REL_ "GenSigTimeoutTime" BU_SG_REL_ SCR SG_ 1648 MO_Abstellzeit 5000;
BA_REL_ "GenSigTimeoutTime" BU_SG_REL_ SCR SG_ 1648 MO_Abstellzeit_Status 5000;
BA_REL_ "GenSigTimeoutTime" BU_SG_REL_ SCR SG_ 1010 Motor_19_BZ 800;
BA_REL_ "GenSigTimeoutTime" BU_SG_REL_ SCR SG_ 1010 MO_SCR_Heizkreis_3_Leistung 800;
BA_REL_ "GenSigTimeoutTime" BU_SG_REL_ SCR SG_ 1010 MO_SCR_Tankheizkreis_Leistung 800;
BA_REL_ "GenSigTimeoutTime" BU_SG_REL_ SCR SG_ 1010 MO_SCR_Heizkreis_3 800;
BA_REL_ "GenSigTimeoutTime" BU_SG_REL_ SCR SG_ 1010 MO_SCR_Tankheizung 800;
BA_REL_ "GenSigTimeoutTime" BU_SG_REL_ SCR SG_ 1010 MO_SCR_Dosierpumpe_Zustand 800;
BA_REL_ "GenSigTimeoutTime" BU_SG_REL_ SCR SG_ 1010 MO_SCR_Leitungsheizung 800;
BA_REL_ "GenSigTimeoutTime" BU_SG_REL_ SCR SG_ 1010 MO_SCR_Dosierpumpe_Wartezeit 800;
BA_REL_ "GenSigTimeoutTime" BU_SG_REL_ SCR SG_ 1010 MO_SCR_Dosierpumpe_Soll 800;
BA_REL_ "GenSigTimeoutTime" BU_SG_REL_ SCR SG_ 1601 MO_OBD_Typ 5000;
BA_REL_ "GenSigTimeoutTime" BU_SG_REL_ SCR SG_ 394 MO_Start_Art 2000;
BA_REL_ "GenSigTimeoutTime" BU_SG_REL_ SCR SG_ 2600468496 NM_Gateway_SNI 2000;
BA_REL_ "GenSigTimeoutTime" BU_SG_REL_ SCR SG_ 2600468496 NM_Gateway_CBV_CRI 2000;
BA_REL_ "GenSigTimeoutTime" BU_SG_REL_ SCR SG_ 2600468496 NM_Gateway_CAB 2000;
BA_REL_ "GenSigTimeoutTime" BU_SG_REL_ SCR SG_ 2600468519 NM_Nightvision_SNI 2000;
BA_REL_ "GenSigTimeoutTime" BU_SG_REL_ SCR SG_ 2600468519 NM_Nightvision_CBV_CRI 2000;
BA_REL_ "GenSigTimeoutTime" BU_SG_REL_ SCR SG_ 2600468519 NM_Nightvision_CAB 2000;
BA_REL_ "GenSigTimeoutTime" BU_SG_REL_ SCR SG_ 2600468491 NM_RDK_SNI 2000;
BA_REL_ "GenSigTimeoutTime" BU_SG_REL_ SCR SG_ 2600468491 NM_RDK_CBV_CRI 2000;
BA_REL_ "GenSigTimeoutTime" BU_SG_REL_ SCR SG_ 2600468491 NM_RDK_CAB 2000;
BA_REL_ "GenSigTimeoutTime" BU_SG_REL_ STH_MLBevo SG_ 1600 MO_QBit_Kuehlmittel_Temp 3200;
BA_REL_ "GenSigTimeoutTime" BU_SG_REL_ STH_MLBevo SG_ 1600 MO_Absperrventil_oeffnen 3200;
BA_REL_ "GenSigTimeoutTime" BU_SG_REL_ STH_MLBevo SG_ 1600 MO_Kuehlmittel_Temp 3200;
BA_REL_ "GenSigTimeoutTime" BU_SG_REL_ STH_MLBevo SG_ 1600 MO_Hoeheninfo 3200;
BA_REL_ "GenSigTimeoutTime" BU_SG_REL_ STH_MLBevo SG_ 1600 MO_Heizungspumpenansteuerung 3200;
BA_REL_ "GenSigTimeoutTime" BU_SG_REL_ STH_MLBevo SG_ 1600 MO_Nachlaufzeit_Heizungspumpe 3200;
BA_REL_ "GenSigTimeoutTime" BU_SG_REL_ STH_MLBevo SG_ 168 MO_QBit_Drehzahl_01 500;
BA_REL_ "GenSigTimeoutTime" BU_SG_REL_ STH_MLBevo SG_ 168 MO_Drehzahl_01 500;
BA_REL_ "GenSigTimeoutTime" BU_SG_REL_ STH_MLBevo SG_ 958 MO_StartStopp_Wiederstart 1000;
BA_REL_ "GenSigTimeoutTime" BU_SG_REL_ STH_MLBevo SG_ 958 MO_StartStopp_Motorstopp 1000;
BA_REL_ "GenSigTimeoutTime" BU_SG_REL_ STH_MLBevo SG_ 958 MO_Motor_laeuft 1000;
BA_REL_ "GenSigTimeoutTime" BU_SG_REL_ STH_MLBevo SG_ 958 MO_Handshake_STH 1000;
BA_REL_ "GenSigTimeoutTime" BU_SG_REL_ STH_MLBevo SG_ 1423 MO_Tankdruck 3200;
BA_REL_ "GenSigTimeoutTime" BU_SG_REL_ STH_MLBevo SG_ 1601 MO_Kraftstoffart 5000;
BA_REL_ "GenSigTimeoutTime" BU_SG_REL_ STH_MLBevo SG_ 2600468496 NM_Gateway_SNI 2000;
BA_REL_ "GenSigTimeoutTime" BU_SG_REL_ STH_MLBevo SG_ 2600468496 NM_Gateway_CBV_CRI 2000;
BA_REL_ "GenSigTimeoutTime" BU_SG_REL_ STH_MLBevo SG_ 2600468496 NM_Gateway_CAB 2000;
BA_REL_ "GenSigTimeoutTime" BU_SG_REL_ STH_MLBevo SG_ 2600468519 NM_Nightvision_SNI 2000;
BA_REL_ "GenSigTimeoutTime" BU_SG_REL_ STH_MLBevo SG_ 2600468519 NM_Nightvision_CBV_CRI 2000;
BA_REL_ "GenSigTimeoutTime" BU_SG_REL_ STH_MLBevo SG_ 2600468519 NM_Nightvision_CAB 2000;
BA_REL_ "GenSigTimeoutTime" BU_SG_REL_ STH_MLBevo SG_ 2600468491 NM_RDK_SNI 2000;
BA_REL_ "GenSigTimeoutTime" BU_SG_REL_ STH_MLBevo SG_ 2600468491 NM_RDK_CBV_CRI 2000;
BA_REL_ "GenSigTimeoutTime" BU_SG_REL_ STH_MLBevo SG_ 2600468491 NM_RDK_CAB 2000;
BA_REL_ "GenSigTimeoutTime" BU_SG_REL_ TopView SG_ 917 LWR_Hoehenwert_VL 1000;
BA_REL_ "GenSigTimeoutTime" BU_SG_REL_ TopView SG_ 917 LWR_Hoehenwert_HL 1000;
BA_REL_ "GenSigTimeoutTime" BU_SG_REL_ TopView SG_ 2600468496 NM_Gateway_SNI 2000;
BA_REL_ "GenSigTimeoutTime" BU_SG_REL_ TopView SG_ 2600468496 NM_Gateway_CBV_CRI 2000;
BA_REL_ "GenSigTimeoutTime" BU_SG_REL_ TopView SG_ 2600468496 NM_Gateway_CAB 2000;
BA_REL_ "GenSigTimeoutTime" BU_SG_REL_ TopView SG_ 2600468519 NM_Nightvision_SNI 2000;
BA_REL_ "GenSigTimeoutTime" BU_SG_REL_ TopView SG_ 2600468519 NM_Nightvision_CBV_CRI 2000;
BA_REL_ "GenSigTimeoutTime" BU_SG_REL_ TopView SG_ 2600468519 NM_Nightvision_CAB 2000;
BA_REL_ "GenSigTimeoutTime" BU_SG_REL_ TopView SG_ 2600468491 NM_RDK_SNI 2000;
BA_REL_ "GenSigTimeoutTime" BU_SG_REL_ TopView SG_ 2600468491 NM_RDK_CBV_CRI 2000;
BA_REL_ "GenSigTimeoutTime" BU_SG_REL_ TopView SG_ 2600468491 NM_RDK_CAB 2000;
VAL_ 917 AFS_Abbiegelicht_li_Anf 0 "Abbiegelicht_aus" 1 "Abbiegelicht_ein" ;
VAL_ 917 AFS_Abbiegelicht_re_Anf 0 "Abbiegelicht_aus" 1 "Abbiegelicht_ein" ;
VAL_ 917 AFS_Abbiegelicht_Dimm_Anf 0 "Dimmung_angefordert" 1 "keine_Dimmung" ;
VAL_ 917 AFS_Verfuegbarkeit_GLW 0 "GLW_nicht_verfuegbar" 1 "GLW_verfuegbar" ;
VAL_ 917 AFS_Status_adaptive_LV 0 "adaptive_Lichtverteilung_aus" 1 "adaptive_Lichtverteilung_an" ;
VAL_ 917 AFS_Fernlicht_li_defekt 0 "Fernlicht_in_Ordnung" 1 "Fernlicht_defekt" ;
VAL_ 917 AFS_Fernlicht_re_defekt 0 "Fernlicht_in_Ordnung" 1 "Fernlicht_defekt" ;
VAL_ 917 AFS_Fernlicht_Status 0 "Fernlicht_aus" 1 "Fernlicht_ein" ;
VAL_ 917 AFS_Lampe 0 "Aus" 1 "Ein" ;
VAL_ 917 LWR_Lampe 0 "LWR Fehlerlampe aus" 1 "LWR Fehlerlampe ein" ;
VAL_ 917 AFS_Fehlertext 0 "kein Text" 1 "AFS ohne Funktion" ;
VAL_ 917 AFS_LED_Blinkmode 0 "kein Blinkmode angefordert" 1 "Blinkmode angefordert" ;
VAL_ 917 LWR_Touristenmodus_aktiv 0 "Touristenmodus inaktiv" 1 "Touristenmodus aktiv" ;
VAL_ 917 AFS_Charisma_FahrPr 0 "keine_Funktion" 1 "Programm_1" 2 "Programm_2" 3 "Programm_3" 4 "Programm_4" 5 "Programm_5" 6 "Programm_6" 7 "Programm_7" 8 "Programm_8" 9 "Programm_9" 10 "Programm_10" 11 "Programm_11" 12 "Programm_12" 13 "Programm_13" 14 "Programm_14" 15 "Programm_15" ;
VAL_ 917 AFS_Charisma_Status 0 "Init" 1 "verfuegbar" 2 "nicht_verfuegbar" 3 "asynchron_durch_Fahrerwunsch" ;
VAL_ 917 LWR_Sicherheitsposition_re 0 "inaktiv" 1 "aktiv" ;
VAL_ 917 AFS_Allwetterlicht 0 "Allwetterlicht_nicht_aktiv" 1 "Allwetterlicht_aktiv" ;
VAL_ 917 LWR_Touristenmodus_verbaut 0 "Touristenmodus_nicht_verbaut" 1 "Touristenmodus_verbaut" ;
VAL_ 917 AFS_adaptive_LV_verbaut 0 "adaptive_Lichtverteilung_nicht_verbaut" 1 "adaptive_Lichtverteilung_verbaut" ;
VAL_ 917 LWR_Reisemodus_Texte 0 "keine_Anzeige" 1 "Umschaltung_auf_Linksverkehr_aktiv" 2 "Umschaltung_auf_Rechtsverkehr_aktiv" ;
VAL_ 917 GLW_Sensor_blockiert 0 "Kamera_Sensor_nicht_blockiert" 1 "Kamera_Sensor_blockiert" ;
VAL_ 917 AFS_Charisma_Umschaltung 0 "Idle" 1 "Erkennung_Umschaltaufforderung" 2 "Steuerbotschaft_nicht_definiert" 3 "Umschaltung_verzoegert" ;
VAL_ 917 LWR_Pos_Schrittmotor 254 "Init" 255 "Fehler" ;
VAL_ 917 LWR_Hoehenwert_VL 254 "nicht_initialisiert" 255 "Fehler" ;
VAL_ 917 LWR_Hoehenwert_HL 254 "nicht_initialisiert" 255 "Fehler" ;
VAL_ 917 AFS_Ersatzlicht_Links 0 "keine Ersatzlichtfunktion links" 1 "Ersatzlichtfunktion links" ;
VAL_ 917 AFS_Ersatzlicht_Rechts 0 "keine Ersatzlichtfunktion rechts" 1 "Ersatzlichtfunktion rechts" ;
VAL_ 917 LWR_AFS_Grundeinstellung 0 "Grundeinstellung nicht erfolgt" 1 "Grundeinstellung erfolgt" ;
VAL_ 917 LWR_AFS_Parametrisierung 0 "Parametrisierung nicht erfolgt" 1 "Parametrisierung erfolgt" ;
VAL_ 917 LWR_Initialisierungslauf 0 "Initialisierungslauf nicht erfolgt" 1 "Initialisierungslauf erfolgt" ;
VAL_ 917 LWR_Sicherheitsposition_li 0 "inaktiv" 1 "aktiv" ;
VAL_ 917 LWR_Modus 0 "LWR statisch" 1 "LWR dynamisch" ;
VAL_ 1153 ZR_LoGeWa_Event_Kombiwarnung 0 "Init" 1 "Unfall" 2 "Traktionsverlust" 3 "Panne" 4 "Sichtbehinderung" 5 "Aquaplaning" 6 "EEBL" 7 "SEF_stat" 8 "SEF_dyn_allgemein" 9 "SEF_dyn_vorne" 10 "SEF_dyn_hinten" 11 "SEF_dyn_links" 12 "SEF_dyn_rechts" 13 "Stauende" ;
VAL_ 1153 Nav_FoD_Status 0 "Init" 1 "Nav_permanently_available" 2 "FoD_Nav_not_activated" 3 "FoD_Nav_activated" 4 "R4N_Nav_not_activated" ;
VAL_ 1153 MIB_Tongenerator_PH_verfuegbar 0 "Tongenerator_nicht_verfuegbar" 1 "Tongenerator_vorne_verfuegbar" 2 "Tongenerator_hinten_verfuegbar" 3 "Tongenerator_gesamt_verfuegbar" 4 "Tongenerator_im_AMP" ;
VAL_ 1153 DSSS_Warning 0 "No_Warning" 1 "Red_traffic_light_guidance" 2 "Stop_sign_warning" 3 "Rear_end_collision_avoidance_warning" 4 "Intersection_collision_avoidance_warning_right" 5 "Intersection_collision_avoidance_warning_left" 6 "turn_right_collision_avoidance" 7 "turn_left_collision_avoidance" 8 "pedestrian_crossing_right" 9 "pedestrian_crossing_left" 10 "bicycle_collision_right" 11 "bicycle_collision_left" ;
VAL_ 1153 ZR_Kindersicherung_RSE 0 "inaktiv" 1 "aktiv" ;
VAL_ 1153 ZR_RSE_aktivieren 0 "inaktiv" 1 "aktiv" ;
VAL_ 1153 MMI_SDS_aktiv 0 "inaktiv" 1 "aktiv" ;
VAL_ 1153 MU_SecondDisplay 0 "Init" 1 "gueltige_Karte" 2 "ungueltiges_Signal" 3 "Nicht_Verbaut" ;
VAL_ 1153 MMI_Telefon_aktiv 0 "Telefongespraech_nicht_aktiv" 1 "Telefongespraech_aktiv" ;
VAL_ 1153 MMI_Gurt_Mic_ref 0 "Downlink_inaktiv" 1 "Downlink_aktiv" ;
VAL_ 1153 ZR_Sta_Inszenierung 0 "Init" 1 "Inszenierung_deaktiviert" 2 "Inszenierung_Start" 3 "Inszenierung_Stop" ;
VAL_ 1153 MMI_Gauges_active 0 "gauges_inactive" 1 "gauges_active" ;
VAL_ 1153 ZR_MXB_Manoever_Ansage 0 "keine_Ansage" 1 "Ansage_ohne_Richtung" 2 "Ansage_rechte_Richtung" 3 "Ansage_linke_Richtung" ;
VAL_ 1153 ZR_LAPP_Sondermodus_Status 0 "keine_Anforderung" 1 "Sondermodus_aktiv" 2 "Aktivierung_nicht_moeglich" ;
VAL_ 1153 MMI_StartStopp_Info 0 "Stoppfreigabe" 1 "Stoppverbot" 2 "Startanforderung" 3 "Fehler" ;
VAL_ 1153 ZR_Parken_Sondermodus 0 "Init" 1 "Sondermodus_aktiv" 2 "Sondermodus_nicht_verfuegbar" 3 "WLAN_aus" 4 "WLAN_auscodiert" 15 "keine_WLAN_HW" ;
VAL_ 1153 ZR_Rundenbewertung 0 "Bewertung_nicht_aktiv" 1 "langsamer" 2 "gleich_schnell" 3 "schneller" 4 "reserviert" 5 "reserviert" 6 "reserviert" 7 "reserviert" 8 "reserviert" 9 "reserviert" 10 "reserviert" 11 "reserviert" 12 "reserviert" 13 "reserviert" 14 "Init" 15 "Funktion_nicht_verbaut" ;
VAL_ 1153 ZR_Rundenfortschritt 254 "Init" 255 "Funktion_nicht_verbaut" ;
VAL_ 1600 MO_QBit_Ansaugluft_Temp 0 "gueltiger_Wert" 1 "Ersatz_Init_oder_Fehlerwert" ;
VAL_ 1600 MO_QBit_Oel_Temp 0 "gueltiger_Wert" 1 "Ersatz_Init_oder_Fehlerwert" ;
VAL_ 1600 MO_QBit_Kuehlmittel_Temp 0 "gueltiger_Wert" 1 "Ersatz_Init_oder_Fehlerwert" ;
VAL_ 1600 MO_KL15_Abschaltempfehlung 0 "Keine Empfehlung" 1 "Abschaltempfehlung" ;
VAL_ 1600 MO_HYB_Fehler_HV_Netz 0 "i_O" 1 "kein_generatorischer_Betrieb_moeglich" ;
VAL_ 1600 MO_aktives_Getriebeheizen 0 "kein_Ventil_ansteuern" 1 "Ventil_muss_angesteuert_werden" ;
VAL_ 1600 MO_Absperrventil_oeffnen 0 "nicht_verfuegbar" 1 "Ansteuerung_Ventil_zulaessig" 2 "Ventil_oeffnen_oder_geoeffnet" 3 "Ventil_schliessen_oder_geschlossen" ;
VAL_ 1600 MO_Ansaugluft_Temp 254 "Init" 255 "Fehler" ;
VAL_ 1600 MO_Oel_Temp 253 "nicht_verbaut" 254 "Init" 255 "Fehler" ;
VAL_ 1600 MO_Kuehlmittel_Temp 254 "Init" 255 "Fehler" ;
VAL_ 1600 MO_Hoeheninfo 255 "Fehler" ;
VAL_ 1600 MO_Kennfeldk 0 "keine Kennfeldkühlung vorhanden" 1 "Kennfeldkühlung vorhanden" ;
VAL_ 1600 MO_Versionsinfo_02 0 "zum_Projektbeginn_aufgeraeumter_CAN" 1 "Motor_03_mit_10ms" 16 "MQB_mit_neuer_Momentenschnittstelle" ;
VAL_ 1600 MO_QBit_Hoeheninfo 0 "gueltiger_Wert" 1 "Ersatz_Init_oder_Fehlerwert" ;
VAL_ 1600 MO_Getriebe_kuehlen 0 "nicht_kuehlen" 1 "kuehlen" ;
VAL_ 1600 MO_Heizungspumpenansteuerung 13 "Fehler" 14 "Init" 15 "nicht_verbaut" ;
VAL_ 1600 MO_SpannungsAnf 0 "keine_Anforderung" 1 "Anforderung" ;
VAL_ 167 MO_Mom_Soll_Roh 1022 "Init" ;
VAL_ 167 MO_Mom_Ist_Summe 1022 "Init" ;
VAL_ 167 MO_Mom_Traegheit_Summe 1022 "Init" ;
VAL_ 167 MO_Mom_Soll_gefiltert 1022 "Init" ;
VAL_ 167 MO_Mom_Schub 510 "Init" ;
VAL_ 167 MO_Status_Normalbetrieb_01 0 "kein_Normalbetrieb" 1 "Normalbetrieb_erreicht" ;
VAL_ 167 MO_erste_Ungenauschwelle 0 "genau" 1 "Momente ungenauer >8%" ;
VAL_ 167 MO_QBit_Motormomente 0 "gueltiger_Wert" 1 "Ersatz_Init_oder_Fehlerwert" ;
VAL_ 168 MO_Mom_neg_verfuegbar 510 "Init" 511 "Fehler" ;
VAL_ 168 MO_Mom_Begr_stat 510 "Init" ;
VAL_ 168 MO_Mom_Begr_dyn 1022 "Init" ;
VAL_ 168 MO_QBit_Drehzahl_01 0 "gueltiger_Wert" 1 "Ersatz_Init_oder_Fehlerwert" ;
VAL_ 958 MO_StartStopp_Status 0 "System_in_diesem_KL15_Zyklus_nicht_verfuegbar" 1 "System_aktiv_keine_Freigabe_durch_StartStop_Koordinator" 2 "System_aktiv_alle_Freigaben_liegen_vor" 3 "System_aktiv_mindestens_eine_Freigabe_fehlt" ;
VAL_ 958 MO_StartStopp_Wiederstart 0 "Wiederstart_inaktiv" 1 "Wiederstart_aktiv" ;
VAL_ 958 MO_StartStopp_Motorstopp 0 "Motor_Stop_inaktiv" 1 "Motor_Stop_aktiv" ;
VAL_ 958 MO_Freig_Reku 0 "Rekuperations-Modus aus" 1 "Empfehlung Spannungsanhebung" 2 "Empfehlung Spannungsabsenkung" 3 "Rekuperationsmodus aktiv, Spannungsvariation nicht notwendig" ;
VAL_ 958 MO_Kl_75 0 "Aus" 1 "Ein" ;
VAL_ 958 MO_Kl_50 0 "aus" 1 "KL50_ein_Startausfuehrung_Fahrer" ;
VAL_ 958 MO_Gangposition 0 "Gang_N" 1 "Gang_1" 2 "Gang_2" 3 "Gang_3" 4 "Gang_4" 5 "Gang_5" 6 "Gang_6" 7 "Gang_7" 8 "Gang_8" 9 "Automat_P" 10 "Automat_Vorwaerts_S" 11 "Automat_Vorwaerts_D/E" 12 "Zwischenstellung" 13 "Gang_R" 14 "Istgang_nicht_definiert" 15 "Fehler" ;
VAL_ 958 MO_StartStopp_Fahrerwunsch 0 "Init" 1 "Stoppverbot_durch_Fahrer" 2 "Stoppfreigabe_durch_Fahrer" 3 "Stoppanforderung_durch_Fahrer" ;
VAL_ 958 MO_HYB_Fahrbereitschaft 0 "keine_Fahrbereitschaft" 1 "Fahrbereitschaft" ;
VAL_ 958 MO_Ext_E_Fahrt_aktiv 0 "Rueckmeldung_E_Taster_aus" 1 "Rueckmeldung_E_Taster_ein" ;
VAL_ 958 MO_Fahrer_bremst 0 "kein_Bremsen" 1 "Bremse_betaetigt" ;
VAL_ 958 MO_QBit_Fahrer_bremst 0 "gueltiger_Wert" 1 "Ersatz_Init_oder_Fehlerwert" ;
VAL_ 958 MO_BLS 0 "kein_Bremsen" 1 "Bremse_betaetigt" ;
VAL_ 958 MO_Konsistenz_Bremsped 0 "Bremspedalinformation_plausibel" 1 "Bremspedalinformation_unplausibel" ;
VAL_ 958 MO_KomFehler_ESP 0 "kein_Fehler" 1 "Fehler" ;
VAL_ 958 MO_Klima_Eingr 0 "kein Eingriff" 1 "Klimakompressor ausschalten" 2 "Klimakompressor Leistungsreduzierung" 3 "Klimakompressor aufgrund der Heissleuchtenvorwarnung ausschalten" ;
VAL_ 958 MO_Aussp_Anlass 0 "Anlasser_darf_angesteuert_werden" 1 "Anlasser_ausspuren__Ansteuerung_nicht_moeglich" ;
VAL_ 958 MO_Freig_Anlass 0 "Start_nicht_zulaessig" 1 "Startfreigabe" ;
VAL_ 958 MO_Kuppl_schalter 0 "Schalter_sagt_ausgekuppelt" 1 "Schalter_sagt_eingekuppelt" ;
VAL_ 958 MO_Interlock 0 "Interlockschalter_nicht_betaetigt" 1 "Interlockschalter_betaetigt" ;
VAL_ 958 MO_Motor_laeuft 0 "Motor_laeuft_nicht" 1 "Motor_laeuft_autark_und_stabil_und_darf_mechanisch_belastet_werden" ;
VAL_ 958 MO_Kickdown 0 "kein_Kickdown" 1 "Kickdown" ;
VAL_ 958 MO_QBit_KL_75 0 "gueltiger_Wert" 1 "Ersatz_Init_oder_Fehlerwert" ;
VAL_ 958 MO_EKlKomLeiRed 0 "keine_Leistungsbegr" 1 "Leistungsbegr_75" 2 "Leistungsbegr_50" 3 "Leistungsbegr_25" ;
VAL_ 958 MO_Handshake_STH 0 "keine EKP-Ansteuerung durch STH-Anforderung" 1 "EKP-Ansteuerung durch STH-Anforderung" ;
VAL_ 958 MO_BKV_Unterdruckwarnung 0 "Unterdruckhaushalt_iO" 1 "Unterdruckhaushalt_niO" ;
VAL_ 958 MO_Freigabe_Segeln 0 "Segelbetrieb_nicht_freigegeben" 1 "Segelbetrieb_freigegeben" ;
VAL_ 958 MO_PTC_Status 0 "nicht_unterstuetzt" 1 "Stufe_0" 2 "Stufe_1" 3 "Stufe_2" 4 "Stufe_3" 7 "PTC_am_BCM" ;
VAL_ 958 MO_QBit_Gangposition 0 "gueltiger_Wert" 1 "Ersatz_Init_oder_Fehlerwert" ;
VAL_ 958 MO_Signalquelle_Gangposition 0 "Sensorsignal" 1 "Modellsignal" ;
VAL_ 958 MO_Remotestart_Betrieb 0 "MSG_nicht_bereit_fuer_RS_Betrieb" 1 "MSG_bereit_fuer_oder_im_RS_Betrieb" ;
VAL_ 958 MO_Remotestart_moeglich 0 "Remotestart_nicht_moeglich" 1 "Remotestart_moeglich" ;
VAL_ 958 MO_Text_Geschw_red 0 "keine_Anzeige" 1 "Anzeige_Geschwindigkeitsred" ;
VAL_ 958 MO_FMAus_aktiv 0 "inaktiv" 1 "Segeln_mit_Motor_aus_aktiv" ;
VAL_ 958 MO_FMAus_Startvariante 0 "kein_Motorstart" 1 "Motorstart_elektrischer_Starter" 2 "GetriebeAnschleppstart" 3 "GetriebeNotAnschleppstart" ;
VAL_ 958 MO_BMS_NV_Anf_stuetzen 0 "nicht_notwendig" 1 "notwendig" ;
VAL_ 958 MO_Zylinderabschaltung 0 "Vollmotorbetrieb_VMB" 1 "Uebergang_HMB_in_VMB" 2 "Uebergang_VMB_in_HMB" 3 "Halbmotorbetrieb_HMB" ;
VAL_ 958 MO_HYB_VM_aktiv 0 "VM_nicht_aktiv" 1 "VM_aktiv" ;
VAL_ 958 MO_StartVorauss_erfuellt 0 "Signal_nicht_bedient" 1 "StartVorauss_nicht_ueberpruefbar" 2 "StartVorauss_nicht_erfuellt" 3 "StartVorauss_erfuellt" ;
VAL_ 1648 MO_ANC_Kennfeld_Anf 0 "Kennfeld_1" 1 "Uebergang_Kennfeld_2_nach_1" 2 "Uebergang_Kennfeld_1_nach_2" 3 "Kennfeld_2" ;
VAL_ 1648 MO_Bremslicht_Reku 0 "Aus" 1 "Ein" ;
VAL_ 1648 MO_StartStopp_PopUp 0 "Statuswechsel_ohne_Taster (Init)" 1 "StSt_per_Taster_deaktiviert" 2 "StSt_per_Taster_aktiviert" 3 "nicht verwendet" ;
VAL_ 1648 MO1_Sperr_Info_WFS 0 "nicht_gesperrt" 1 "gesperrt" ;
VAL_ 1648 MO1_Freigabe_Info_WFS 0 "ungueltig" 1 "gueltig" ;
VAL_ 1648 MO_EPCL 0 "EPCL_aus_kein_Text" 1 "EPCL_gelb_Stoerung" 2 "EPCL_gelb_Leistungsbeschraenkung" 3 "EPCL_rot_Fzg_sicher_abstellen" ;
VAL_ 1648 MO_Zylabsch_Texte_02 0 "ein_ZAS_generell_keine_ZAS_Anzeigen" 1 "ZAS_im_VMB" 2 "ZAS_im_ASB_1_Zyl_aktiv" 3 "ZAS_im_ASB_2_Zyl_aktiv" 4 "ZAS_im_ASB_3_Zyl_aktiv" 5 "ZAS_im_ASB_4_Zyl_aktiv" 6 "ZAS_im_ASB_5_Zyl_aktiv" 7 "ZAS_im_ASB_6_Zyl_aktiv" 8 "ZAS_im_ASB_8_Zyl_aktiv" 9 "ZAS_im_ASB_12_Zyl_aktiv" 13 "Uebergangsbetrieb" 14 "keine_ZAS_Anzeige_ggf_Stopp_Schub_Betrieb" 15 "ZAS_Stoerungs_Anzeige" ;
VAL_ 1648 MO_Fahrzeugtyp 0 "Verbrenner_Fahrzeug" 1 "Hybrid" 2 "E_Fahrzeug" 3 "E_Fahrzeug_mit_Range_Extender" 4 "Brennstoffzellenfahrzeug" 5 "tbd" 6 "tbd" 7 "tbd" ;
VAL_ 1648 MO_Abstellzeit 254 "Init" 255 "reserviert" ;
VAL_ 1648 MO_Abstellzeit_Status 0 "Abstellzeit_nicht_berechnet" 1 "Abstellzeit_berechnet" 2 "Abstellzeit_Minimalwert" 3 "Abstellzeit_ungueltig" ;
VAL_ 1648 MO1_Freigabe_Verfallsinfo_WFS 0 "verfaellt_nicht" 1 "verfaellt" ;
VAL_ 1648 MO_Hybrid_StartStopp_LED 0 "LED_aus_und_Blinken_aus" 1 "LED_ein_und_Blinken_aus" 2 "LED_ein_und_Blinken_ein_50_percent" 3 "reserviert" ;
VAL_ 1648 MO_Fehler_Zylabsch 0 "kein_Fehler" 1 "Notlauf_Vollmotorbetrieb" 2 "Notlauf_mindestens_einem_abgesch_Zylinder" ;
VAL_ 1648 MO_Anzahl_Abgesch_Zyl 0 "Vollmotorbetrieb" 1 "1_Zylinder_abgeschaltet" 2 "2_Zylinder_abgeschaltet" 3 "3_Zylinder_abgeschaltet" 4 "4_Zylinder_abgeschaltet" 5 "5_Zylinder_abgeschaltet" 6 "6_Zylinder_abgeschaltet" 7 "8_Zylinder_abgeschaltet" ;
VAL_ 1648 MO_Zylabsch_Texte 0 "keine_Texte" 1 "Zylinderabschaltung_deaktivieren" 2 "Zylinderabschaltung_aktivieren" 3 "Zylinderabschaltung_unruhig" ;
VAL_ 1648 MO_Ethanol_BS_Texte 0 "kein_Text" 1 "E85_Warm_Up" 2 "FlexFuel_Warnung_Stufe_3" 3 "Warmfahrempfehlung_MQB__FlexFuel_Warnung_Stufe_1" 4 "FlexFuel_Warnung_Stufe_2" 5 "FlexFuel_Warnung_Stufe_4" 6 "E25_Warm_Up" ;
VAL_ 1648 MO_Drehzahl_Warnung 0 "keinen_Warnhinweis_anzeigen" 1 "Warnhinweis_anzeigen" ;
VAL_ 1648 MO_obere_Drehzahlgrenze 0 "Init" ;
VAL_ 1010 MO_SCR_Heizkreis_3_Leistung 254 "Init" ;
VAL_ 1010 MO_SCR_Tankheizkreis_Leistung 254 "Init" ;
VAL_ 1010 MO_SCR_Heizkreis_3 0 "Heizung_aus" 1 "Heizung_ein" ;
VAL_ 1010 MO_SCR_Tankheizung 0 "Heizung_aus" 1 "Heizung_ein" ;
VAL_ 1010 MO_SCR_Dosierpumpe_Zustand 0 "Pumpe_Stop" 1 "Drehzahlregelung" 2 "Druckregelung_langsam" 3 "Druckregelung_schnell" 4 "frei" 5 "Rueckwaertsbetrieb" 6 "verzoegerter_Rueckwaertsbetrieb" 7 "Pumpe_heizen" ;
VAL_ 1010 MO_SCR_Leitungsheizung 0 "Heizung_aus" 1 "Heizung_ein" ;
VAL_ 1010 MO_SCR_Dosierpumpe_Wartezeit 125 "nicht_verbaut" 126 "Init" 127 "Fehler" ;
VAL_ 1010 MO_SCR_Transferpumpe 0 "Pumpe_aus" 1 "Pumpe_ein" ;
VAL_ 289 MO_Fahrpedalrohwert_01 255 "Fehler" ;
VAL_ 289 MO_QBit_Fahrpedalwerte_01 0 "gueltiger_Wert" 1 "Ersatz_Init_oder_Fehlerwert" ;
VAL_ 289 MO_Fahrpedalgradient 255 "Fehler" ;
VAL_ 289 MO_Sig_Fahrpedalgradient 0 "Fahrpedalgradient positiv" 1 "Fahrpedalgradient negativ" ;
VAL_ 289 MO_rel_Saugrohrdruck 0 "Init_Ueberdruck" 63 "Fehler" ;
VAL_ 289 MO_rel_Saugrohrdruck_gem_err 0 "errechnet" 1 "gemessen" ;
VAL_ 289 MO_Moment_im_Leerlauf 0 "kein_Leergas" 1 "Leergas" ;
VAL_ 289 MO_Schubabschaltung 0 "keine_Schubabschaltung" 1 "Schubabschaltung_aktiv" ;
VAL_ 289 MO_StartStopp_StoppVorbereitung 0 "Motorstopp_nicht_in_Vorbereitung" 1 "Motorstopp_in_Vorbereitung" ;
VAL_ 289 MO_Entkopplung_Sollschlupf 125 "Notoeffnen_Anfahrelement" 126 "Init" ;
VAL_ 289 MO_temporaere_Fahrerabwesenheit 0 "nicht_erkannt" 1 "erkannt" ;
VAL_ 289 TSK_a_Soll_gradientenbegrenzt 127 "Init_oder_nicht_aktiv" ;
VAL_ 815 MO_Anzeige_Rekuperation 0 "Init_und_nicht_verbaut" ;
VAL_ 815 PEA_Fortschrittsanzeige 127 "Neutralwert" ;
VAL_ 815 MO_Anzeige_Fahrbereitschaft 0 "OFF" 1 "READY" ;
VAL_ 815 MO_Boost_verfuegbar 0 "Init" 253 "Nicht_verbaut" 254 "Funktion_deaktiv" 255 "Fehler" ;
VAL_ 815 MO_Overboost 0 "inaktiv" 1 "aktiv" ;
VAL_ 815 MO_Boost_aktiv 0 "kein_Boost_aktiv" 1 "Boost_aktiv" ;
VAL_ 815 MO_Anzeige_Betriebsmodus 0 "Init_keine_Anzeige" 1 "EV" 2 "Auto" 3 "Hold" 4 "Charge" 5 "GTE" 6 "ECO" 7 "SPORT" 8 "Auto_praediktiv" 9 "Manuell_SOC_erhoehen" 10 "Manuell_SOC_halten" 11 "Manuell_SOC_verringern" ;
VAL_ 815 PEA_Hinweis 0 "keine_Anzeige" 1 "Anzeige_Fusssymbol_1" 2 "Anzeige_Fusssymbol_2" 3 "Anzeige_Auskuppeln" ;
VAL_ 815 PEA_Ereignisanzeige 0 "keine_Anzeige" 1 "Linkskurve_voraus" 2 "Rechtskurve_voraus" 3 "Kreuzung_voraus" 4 "Gefaelle_voraus" 5 "Kreisverkehr_voraus" 6 "Fahrzeug_voraus" 7 "Tempolimit_voraus" 8 "Ereignis_voraus" 9 "Autobahnabfahrt_voraus" 10 "Autobahnauffahrt_voraus" 11 "Abbiegung_links_voraus" 12 "Abbiegung_rechts_voraus" 13 "Ortseinfahrt_voraus" 14 "Autobahnabfahrt_links_voraus" ;
VAL_ 815 PEA_Ereignisanzeige_temporaer 0 "keine_Anzeige" 1 "Anzeige_temporaer" ;
VAL_ 815 PEA_Abschalttexte 0 "keine_Anzeige" 1 "PEA_ausserhalb_Einsatzgebiet" 2 "PEA_temporaer_nicht_verfuegbar" 3 "PEA_vom_Fahrer_deaktiviert" ;
VAL_ 815 PEA_Zielgeschw_Einheit 0 "km_h" 1 "mph" ;
VAL_ 815 PEA_Zielgeschw 0 "keine_Anzeige" 1 "Wert_5" 2 "Wert_10" 3 "Wert_15" 4 "Wert_20" 5 "Wert_25" 6 "Wert_30" 7 "Wert_35" 8 "Wert_40" 9 "Wert_45" 10 "50" 11 "Wert_55" 12 "Wert_60" 13 "Wert_65" 14 "Wert_70" 15 "Wert_75" 16 "Wert_80" 17 "Wert_85" 18 "Wert_90" 19 "Wert_95" 20 "Wert_100" 21 "Wert_105" 22 "Wert_110" 23 "Wert_115" 24 "Wert_120" 25 "Wert_125" 26 "Wert_130" 27 "Wert_140" 28 "Wert_150" 29 "Wert_160" ;
VAL_ 815 MO_Antriebsstrang_Warnung_HS 0 "Keine_Anzeige" 1 "Fehlereskalationsstufe_I" 2 "Fehlereskalationsstufe_II" 3 "Fehlereskalationsstufe_III" ;
VAL_ 1423 MO_ITM_Status 0 "stehendes_Wasser" 1 "kein_stehendes_Wasser" 2 "Entnahmegrenze_20_Grad_Celsius" 3 "Entnahmegrenze_30_Grad_Celsius" 4 "Entnahmegrenze_40_Grad_Celsius" 5 "Entnahmegrenze_50_Grad_Celsius" 6 "Entnahmegrenze_60_Grad_Celsius" 7 "keine_Entahme_erlaubt" 14 "Init" 15 "Fehler" ;
VAL_ 1423 MO_Tankdruck 254 "Init" 255 "Fehler" ;
VAL_ 1423 MO_Kuehlmittel_Temp_Rohwert 254 "Init" 255 "Fehler" ;
VAL_ 1423 MO_Oel_Temp_Radsatz 254 "Initialwert" 255 "Fehler" ;
VAL_ 1423 MO_KJS_LLK_Pos_Summe 14 "Init" 15 "Pos_Frontendverschl_ungenau" ;
VAL_ 1423 MO_FSA_Sensorheizung 0 "inaktiv" 1 "aktiv" ;
VAL_ 1423 FSA_Fehlerpfade_Initialisieren 0 "inaktiv" 1 "aktiv" ;
VAL_ 1423 MO_SABody_PosLe 0 "Init_nicht_verbaut" 7 "Pos_ungenau" ;
VAL_ 1423 MO_SABody_PosRi 0 "Init_nicht_verbaut" 7 "Pos_ungenau" ;
VAL_ 1423 MO_MMTR_Status 0 "Nicht_verfuegbar" 1 "Inaktiv" 2 "Aktiv_TrackSession" 3 "Aktiv_Endurance" 4 "Aktiv_HotLap" 5 "Nicht_verfuegbar_HotLap" 14 "Init" 15 "Fehler" ;
VAL_ 340 MO_IstMoment_VKM 1022 "Init" ;
VAL_ 340 MO_Mom_Begr_Schalt 1022 "Init" ;
VAL_ 340 MO_Mom_Begr_Schalt_Min 1022 "Init" ;
VAL_ 340 MO_Fehlerstatus_Antrieb_FDR 0 "FDR_Normalbetrieb" 1 "FDR_abschalten" 2 "FDR_Regelung_beenden" 3 "FDR_abschalten_temporaer" 4 "FDR_Regelung_temporaer_beenden" ;
VAL_ 340 MO_Primaerachse_Anforderung 0 "Init_Freilaufsteuerung_MSG" 1 "Anforderung_Abkoppeln" 2 "Anforderung_Ankoppeln" 3 "Anforderung_Abkoppeln_Katheizen" ;
VAL_ 1601 MO_Faktor_Momente_02 0 "nicht_belegt" ;
VAL_ 1601 MO_Hybridfahrzeug 0 "kein_Hybridfahrzeug" 1 "Mild_Hybrid" 2 "Full_Hybrid" 3 "PlugIn_Hybrid" ;
VAL_ 1601 MO_Getriebe_Code 0 "Init" 2 "DL501" 3 "DL800" 4 "VL381" 5 "DL382_Front" 6 "DL382_Allrad" 7 "DL702" 8 "AL552_Allrad" 9 "AL552_Front" 10 "AL651" 11 "AL551__AL951__AL1000_8A" 12 "PDK_PAG" 13 "AL551_Hybrid" 15 "Handschalter_konventionell" 16 "AQ250_160" 17 "AQ450" 18 "DQ200" 19 "DQ250" 20 "DQ500" 21 "SQ100" 22 "SQ200" 23 "DQ400E" 24 "DQ381" 25 "AL550" 26 "AQ300" 31 "DL800E" 32 "Single_Gear__ohne_GSG_WH_am_MSG" 33 "EQ550_2P" ;
VAL_ 1601 MO_StartStopp_Codiert 0 "Start_Stopp_nicht_verbaut" 1 "Start_Stopp_verbaut" ;
VAL_ 1601 MO_Anzeige_StSt_gueltig 0 "MO_Text_Motorstart_gueltig" 1 "Signale_MO_Anzeige_StSt_gueltig" ;
VAL_ 1601 MO_Anzahl_Zyl 0 "kein_Zylinder" 1 "1_Zylinder" 2 "2_Zylinder" 3 "3_Zylinder" 4 "4_Zylinder" 5 "5_Zylinder" 6 "6_Zylinder" 7 "7_Zylinder" 8 "8_Zylinder" 9 "9_Zylinder" 10 "10_Zylinder" 11 "11_Zylinder" 12 "12_Zylinder" 13 "15_Zylinder" 14 "16_Zylinder" 15 "18_Zylinder" ;
VAL_ 1601 MO_Kraftstoffart 0 "Diesel" 1 "Benzin_inkl_E25_E85" 2 "CNG" 3 "LPG" 4 "Wasserstoff" 5 "E100_Ethanol" 15 "kein_Verbrennungskraftstoff" ;
VAL_ 1601 MO_Ansaugsystem 0 "Turbo" 1 "Sauger" ;
VAL_ 1601 MO_OBD_Typ 0 "NoOBD_RdW" 1 "EOBD" 2 "US_OBD" 3 "reserviert" ;
VAL_ 1601 MO_DPF_verbaut 0 "kein_DPF_verbaut" 1 "DPF_verbaut" ;
VAL_ 1601 TSK_Codierung 0 "kein_Fahrgeschwindigkeitsregler" 1 "GRA" 2 "GRA_Plus" 3 "Basis_ACC" 4 "ACC_Follow_to_Stop" 5 "ACC_Stop_and_Go" 7 "Codierung_in_Plausibilisierungsphase" ;
VAL_ 305 MO_ePowermeter 0 "Init_keine_Anzeige" 254 "Funktion_deaktiv_Anzeige_ausgegraut" 255 "Fehler_keine_Anzeige" ;
VAL_ 305 MO_ePerformance 0 "Init" 254 "Funktion_deaktiv_Anz_ausgegraut" 255 "Fehler" ;
VAL_ 305 MO_Zust_Antrieb 0 "VM bzw. Brennstoffz. aktiv" 1 "EM aktiv" 2 "VM bzw. Brennstoffz. u. EM aktiv" 3 "Segeln oder Reku aktiv" ;
VAL_ 305 MO_Zust_Betriebsstrategie 0 "Kein Hybrid" 1 "Depleting" 2 "Soft-Depleting " 3 "Sustaining" 4 "Increasing" 5 "Fremdgesteuert" ;
VAL_ 305 Ladezustand_02 254 "Init" 255 "Fehler" ;
VAL_ 305 MO_Powermeter_Elm_02 0 "nicht_verbaut" 4094 "Init" ;
VAL_ 305 MO_Powermeter 4093 "Off" ;
VAL_ 394 MO_Ablaufstatus 0 "keine_Aktion" 1 "Aktion_regulaerer_Uebergang" 2 "Aktion_regulaerer_Uebergang" 3 "Aktion_regulaerer_Uebergang" 4 "Aktion_regulaerer_Uebergang" 5 "Aktion_regulaerer_Uebergang" 6 "Aktion_regulaerer_Uebergang" 7 "Aktion_regulaerer_Uebergang" 8 "regulaerer_Uebergang_fertig" 9 "Aktion_Abbruch_Uebergang" 10 "Aktion_Abbruch_Uebergang" 11 "Aktion_Abbruch_Uebergang" 12 "Aktion_Abbruch_Uebergang" 13 "Aktion_Abbruch_Uebergang" 14 "Abbruch_Uebergang_fertig" 15 "Fehler" ;
VAL_ 394 MO_Ablaufstrg_Betriebszustand 0 "Init_Nicht_Betriebsbereit" 1 "Betriebsbereitschaft" 2 "Fahrbetrieb" 7 "Fehler" ;
VAL_ 394 MO_Ablaufstrg_Zustand_VKM_Ist 0 "VKM_aus" 1 "VKM_ein" ;
VAL_ 394 MO_Ablaufstrg_Kraftschluss_Ist 0 "kein_Kraftschluss" 1 "Kraftschluss" ;
VAL_ 394 MO_Ablaufstrg_Zustand_K0_Ist 0 "K0_Kupplung_auf" 1 "K0_Kupplung_zu" ;
VAL_ 394 MO_Ablaufstrg_Kraftschluss2_Ist 0 "Sekundärachse abgekoppelt" 1 "Sekundärachse angekoppelt" ;
VAL_ 394 MO_HYB_LowSpeedModus 0 "LowSpeed_mit_LLDZ" 1 "LowSpeed_ohne_LLDZ" ;
VAL_ 394 MO_Ablaufstrg_Zustand_VKM_Ziel 0 "VKM_aus" 1 "VKM_ein" ;
VAL_ 394 MO_Ablaufstrg_Kraftschluss_Ziel 0 "kein_Kraftschluss" 1 "Kraftschluss" ;
VAL_ 394 MO_Ablaufstrg_Zustand_K0_Ziel 0 "K0_Kupplung_auf" 1 "K0_Kupplung_zu" ;
VAL_ 394 MO_Ablaufstrg_Kraftschluss2_Ziel 0 "Anforderung Sekundaerachse abkoppeln" 1 "Anforderung Sekundaerachse ankoppeln" ;
VAL_ 394 MO_HYB_Stoppmodus 0 "Softstopp" 1 "Dynamikstopp" ;
VAL_ 394 MO_Auth_Aufforderung_WFS 0 "Aus" 1 "Ein" ;
VAL_ 394 MO_Start_Dynamik 0 "Kein_Start" 1 "VKM_IDLE_Start" 2 "Softstart_Schubankoppeln_unbefeu" 3 "Komfortstart_befeuert" 4 "Dynamikstart_befeuert" 5 "Sportstart_befeuert" 6 "plausibilisierter_Schleppstart" 7 "Notstart" ;
VAL_ 394 MO_Start_Art 0 "Init" 1 "Zustarteinrichtung" 2 "Schlupfstart" 3 "Schleppstart" ;
VAL_ 394 MO_Abstellposition_02 255 "Abstellposition_ungenau" ;
VAL_ 394 MO_Mom_Freiheit_Sekundaerachse 0 "Sekundaerachse ist nicht momentenfrei" 1 "Sekundaerachse ist momentenfrei" ;
VAL_ 394 MO_Tankklappensteuerung 0 "Init_nicht_verbaut" 1 "Tankklappe_soll_entriegeln" 2 "Tankklappe_soll_verriegeln" 3 "keine_Aktion" ;
VAL_ 394 MO_HYB_E_Faktor 0 "null" 1 "plus_1" 2 "plus_2" 3 "plus_3" 4 "plus_4" 5 "plus_5" 6 "plus_6" 7 "plus_7" 8 "minus_8" 9 "minus_7" 10 "minus_6" 11 "minus_5" 12 "minus_4" 13 "minus_3" 14 "minus_2" 15 "minus_1" ;
VAL_ 394 MO_HYB_EMode_Info 0 "Normal_Mode" 1 "Depleting_Mode" 2 "Charge_Mode" 3 "Sonder_Schaltprogramm" ;
VAL_ 394 MO_HYB_Adaption_aktiv 0 "Keine_Adaption_aktiv" 1 "Adaption_aktiv" ;
VAL_ 234 TS_Status_MomRad_Ist 0 "FuSi_hohe_Genauigkeit" 1 "FuSi_niedrige_Genauigkeit" 2 "QM_fehlerfrei" 3 "QM_mit_Fehlern" ;
VAL_ 234 TS_Allrad_Anteil_sek 510 "Init" 511 "Fehler" ;
VAL_ 234 TS_MomRad_verfuegb_maxReku_Summe 4094 "Init" ;
VAL_ 234 TS_MomRad_Ist 8190 "Init" ;
VAL_ 234 TS_MomRad_Ist_sek 8190 "Init" ;
VAL_ 849 MRR_HL_ASW_System_aktiv 0 "nicht_aktiv_Init" 1 "aktiv" ;
VAL_ 849 ASW_Warnung_HL 0 "keine_Warnung" 1 "Warnung" ;
VAL_ 849 MRR_HL_QualFaktorAutoKalib 0 "unbekannt" 1 "genau" 2 "ungenau" 3 "fehlerhaft" ;
VAL_ 849 MRR_HL_ASW_Modus 0 "kein_Fehler_KL15" 1 "kein_Fehler_KL30" 2 "reserve" 3 "Anhaengerbetrieb" 4 "init_nicht_codiert" 5 "keine_Sensorsicht_Blindheit" 6 "zur_Zeit_nicht_verfuegbar_temp_F" 7 "Systemstoerung_dauer_Fehler" ;
VAL_ 849 MRR_HL_Performance_Status 0 "kein_Fehler" 1 "volle_Funktion" 2 "Reichweite_eingeschraenkt" ;
VAL_ 849 MRR_HL_Kalibriermodus 0 "aus" 1 "auto" 2 "kurzer_track" 3 "service" 4 "spc_wiederaufnehmen" 5 "stationaer" 6 "ueberschreiben" 7 "Init" ;
VAL_ 849 MRR_HL_ASW_Status 0 "Passiv" 1 "Aktiv" 2 "Fehler" 3 "Aus" ;
VAL_ 849 MRR_HL_Sensor_Kl_Status 0 "Aus" 1 "Kl_30" 2 "Kl_15" ;
VAL_ 849 MRR_HL_Sensor_Fehler 0 "Fehlerfrei" 1 "Systemstoerung" 2 "Systemfehler" 3 "Systemfehler_und_Systemstoerung" ;
VAL_ 2463978596 MRR_HL_Info1 0 "Init" ;
VAL_ 848 MRR_HR_ASW_System_aktiv 0 "nicht_aktiv_Init" 1 "aktiv" ;
VAL_ 848 MRR_HR_QualFaktorAutoKalib 0 "unbekannt" 1 "genau" 2 "ungenau" 3 "fehlerhaft" ;
VAL_ 848 MRR_HR_Kalibriermodus 0 "aus" 1 "auto" 2 "kurzer_track" 3 "service" 4 "spc_wiederaufnehmen" 5 "stationaer" 6 "ueberschreiben" 7 "Init" ;
VAL_ 848 MRR_HR_Performance_Status 0 "kein_Fehler" 1 "volle_Funktion" 2 "Reichweite_eingeschraenkt" ;
VAL_ 848 MRR_HR_Info_Anf 0 "kein_Request" 1 "SW_Version" 2 "DS_Strukturversion1" 3 "DS_Strukturversion2" 4 "DS_Strukturversion3" 5 "Codierung" 6 "Teilenummer" ;
VAL_ 848 MRR_HR_Blindness_Anf 0 "nicht_angefordert" 1 "angefordert" ;
VAL_ 1696 NV_aktiv 0 "NV nicht aktiv" 1 "NV aktiv" ;
VAL_ 1696 NV_Texte 0 "Init" 1 "Abblendlicht_einschalten" 2 "Fussgaengermarkierung_n_v" 3 "zur_Zeit_nicht_verfuegbar" 4 "Systemfehler" 5 "Fussgaengermarkierung_deakt" 6 "Blindheit_erkannt" 7 "kein_Text" ;
VAL_ 1696 NV_Gong 0 "kein_Gong" 1 "Gong_leise" 2 "Gong_mittel" 3 "Gong_laut" ;
VAL_ 1696 NV_Symbol 0 "kein_Symbol_anzeigen" 1 "Symbol_fuer_erkanntes_Objekt_anzeigen" ;
VAL_ 1696 NV_Hinweise 0 "keine_Anzeige" 1 "Disclaimer" 2 "Fussgaenger_Markierung_nicht_verfuegbar" 3 "Nachtsichtsystem_wird_initialisiert" ;
VAL_ 1696 NV_Piktogramm_aktiv 0 "keine_Anzeigenprioritaet" 1 "Anzeigenprioritaet" ;
VAL_ 1696 NV_Akustik_deaktiviert_Icon 0 "aus" 1 "ein" ;
VAL_ 1696 NV_FGM_deaktiviert_Icon 0 "aus" 1 "ein" ;
VAL_ 1696 NV_Markierungslicht_links 0 "Aus" 1 "Ein" ;
VAL_ 1696 NV_Markierungslicht_rechts 0 "Aus" 1 "Ein" ;
VAL_ 1696 NV_Symbol_Tierwarnung 0 "Aus" 1 "Ein" ;
VAL_ 1696 NV_Anf_Prefill 0 "nicht_angefordert" 1 "angefordert" ;
VAL_ 1696 NV_HBA_Parameter 0 "Defaultparametersatz" 1 "Parametersatz_mit_leicht_erhoehter_Empfindlichkeit" 2 "Parametersatz_mit_erhoehter_Empfindlichkeit" 3 "Parametersatz_mit_hoechster_Empfindlichkeit" ;
VAL_ 1696 NV_LED_Leiste 0 "AUS_keine_Anzeige" 1 "Stufe_1_glimmen" 2 "Stufe_2_leuchten" 3 "Stufe_3_blinken" ;
VAL_ 1696 NV_PreSense_Status 0 "Init" 1 "verfuegbar" 2 "nicht_verfuegbar" ;
VAL_ 1696 NV_PreSense_Modus_System 0 "deaktiviert" 1 "aktiviert" ;
VAL_ 1696 NV_PreSense_Modus_Warnung 0 "Aus" 1 "Setting_2" 2 "Setting_3" 3 "Setting_4" 4 "Setting_5" 5 "Ein" ;
VAL_ 1696 NV_FAS_Fkt_Status 0 "Init" 1 "Funktion_Ist_Ein" 2 "Funktion_Ist_Aus" 3 "Fehler" ;
VAL_ 1696 NV_Akt_Status_MMI 0 "deaktiviert" 1 "aktiviert" 3 "Init" ;
VAL_ 1696 NV_AnforderungBildaufschaltung 0 "KeineBildaufschaltung" 1 "Bildaufschaltung" ;
VAL_ 2600468496 NM_Gateway_SNI 16 "Gateway" ;
VAL_ 2600468496 NM_Gateway_CBV_AWB 0 "Passiver_WakeUp" 1 "Aktiver_WakeUp" ;
VAL_ 2600468496 NM_Gateway_CBV_CRI 0 "NM_ohne_Clusteranforderungen" 1 "NM_mit_Clusteranforderungen" ;
VAL_ 2600468496 NM_Gateway_NM_State 0 "Init" 1 "NM_RM_aus_BSM" 2 "NM_RM_aus_PBSM" 4 "NM_NO_aus_RM" 8 "NM_NO_aus_RS" 16 "reserved" 32 "reserved" ;
VAL_ 2600468496 NM_Gateway_Car_Wakeup 0 "Inaktiv" 1 "Car_Wakeup" ;
VAL_ 2600468496 NM_Gateway_UDS_CC 0 "Inaktiv" 1 "CC_aktiv" ;
VAL_ 2600468496 NM_Gateway_NM_aktiv_KL15 0 "Inaktiv" 1 "KL15_EIN" ;
VAL_ 2600468496 NM_Gateway_NM_aktiv_Diagnose 0 "Init" 1 "Diagnose_aktiv" ;
VAL_ 2600468496 NM_Gateway_NM_aktiv_Tmin 0 "Inaktiv" 1 "Mindestaktivzeit" ;
VAL_ 2600468496 NM_Gateway_NM_aktiv_CWU 0 "kein_CWU_gesetzt" 1 "CWU_gesetzt" ;
VAL_ 2600468496 NM_Gateway_NM_aktiv_FC 0 "kein_FC_gesetzt" 1 "FC_gesetzt" ;
VAL_ 2600468496 NM_Gateway_NM_aktiv_Connect 0 "inaktiv" 1 "Nachlauf_aufgrund_Connect" ;
VAL_ 2600468496 NM_Gateway_NM_aktiv_EM 0 "inaktiv" 1 "Nachlauf_aufgrund_Energiemanagement" ;
VAL_ 2600468496 NM_Gateway_NM_aktiv_OBDC 0 "kein_Nachlauf" 1 "Nachlauf_aufgrund_OBDC" ;
VAL_ 2600468496 NM_Gateway_NM_aktiv_Buskopplung 0 "inaktiv" 1 "Nachlauf_aufgrund_Buskopplung" ;
VAL_ 2600468496 NM_Gateway_NM_aktiv_LIN2 0 "Inaktiv" 1 "LIN2_aktiv" ;
VAL_ 2600468496 NM_Gateway_NM_aktiv_Fremdladung 0 "inaktiv" 1 "Nachlauf_aufgrund_Connect" ;
VAL_ 2600468496 NM_Gateway_CAB 0 "inaktiv" 1 "CAB_01__Tueren" 2 "CAB_02__Anhaenger_KCAN" 4 "CAB_03__Nightvision" 8 "CAB_04__Sitzverstellung" 16 "CAB_05__Klappen" 32 "CAB_06__Infotainment" 64 "CAB_07__Sub_Infotainment" 128 "CAB_08__Anzeige" 256 "CAB_09__Laden_HCAN" 512 "CAB_10__Klima" 1024 "CAB_11__FlexRay" 262144 "CAB_19__VLAN_RemoteFC" 524288 "CAB_20__VLAN_Komfort" 1048576 "CAB_21__VLAN_Internet" 2097152 "CAB_22__VLAN_Connect" 4194304 "CAB_23__VLAN_Infotainment" 8388608 "CAB_24__VLAN_FAS" ;
VAL_ 2600468519 NM_Nightvision_SNI 39 "Nightvision" ;
VAL_ 2600468519 NM_Nightvision_CBV_AWB 0 "Passiver_WakeUp" 1 "Aktiver_WakeUp" ;
VAL_ 2600468519 NM_Nightvision_CBV_CRI 0 "Standard_Layout" 1 "TNB_Layout" ;
VAL_ 2600468519 NM_Nightvision_NM_State 1 "NM_RM_aus_BSM" 2 "NM_RM_aus_PBSM" 4 "NM_NO_aus_RM" 8 "NM_NO_aus_RS" 16 "NM_RM_aus_RS" 32 "NM_RM_aus_NO" ;
VAL_ 2600468519 NM_Nightvision_Car_Wakeup 0 "Inaktiv" 1 "Car_Wakeup" ;
VAL_ 2600468519 NM_Nightvision_UDS_CC 0 "Init" 1 "CC_aktiv" ;
VAL_ 2600468519 NM_Nightvision_NM_aktiv_KL15 0 "Inaktiv" 1 "KL15_EIN" ;
VAL_ 2600468519 NM_Nightvision_NM_aktiv_Diagnose 0 "Init" 1 "Diagnose_aktiv" ;
VAL_ 2600468519 NM_Nightvision_NM_aktiv_Tmin 0 "Inaktiv" 1 "Mindestaktivzeit" ;
VAL_ 2600468519 NM_Nightvision_NM_aktiv_ON 0 "NV_nicht_aktiviert" 1 "NV_aktiviert" ;
VAL_ 2600468519 NM_Nightvision_NM_aktiv_defekt 0 "inaktiv" 1 "NV_defekt" ;
VAL_ 2600468519 NM_Nightvision_CAB 0 "inaktiv" 1 "CAB_01__Tueren" 2 "CAB_02__Anhaenger_KCAN" 4 "CAB_03__Nightvision" 8 "CAB_04__Sitzverstellung" 16 "CAB_05__Klappen" 32 "CAB_06__Infotainment" 64 "CAB_07__Sub_Infotainment" 128 "CAB_08__Anzeige" 256 "CAB_09__Laden_HCAN" 512 "CAB_10__Klima" 1024 "CAB_11__FlexRay" 262144 "CAB_19__VLAN_RemoteFC" 524288 "CAB_20__VLAN_Komfort" 1048576 "CAB_21__VLAN_Internet" 2097152 "CAB_22__VLAN_Connect" 4194304 "CAB_23__VLAN_Infotainment" 8388608 "CAB_24__VLAN_FAS" ;
VAL_ 2600468491 NM_RDK_SNI 11 "RDK" ;
VAL_ 2600468491 NM_RDK_CBV_AWB 0 "Passiver_WakeUp" 1 "Aktiver_WakeUp" ;
VAL_ 2600468491 NM_RDK_CBV_CRI 0 "NM_ohne_Clusteranforderungen" 1 "NM_mit_Clusteranforderungen" ;
VAL_ 2600468491 NM_RDK_NM_State 0 "Init" 1 "NM_RM_aus_BSM" 2 "NM_RM_aus_PBSM" 4 "NM_NO_aus_RM" 8 "NM_NO_aus_RS" 16 "reserved" 32 "reserved" ;
VAL_ 2600468491 NM_RDK_Car_Wakeup 0 "Inaktiv" 1 "Car_Wakeup" ;
VAL_ 2600468491 NM_RDK_UDS_CC 0 "Inaktiv" 1 "CC_aktiv" ;
VAL_ 2600468491 NM_RDK_NM_aktiv_KL15 0 "Inaktiv" 1 "KL15_EIN" ;
VAL_ 2600468491 NM_RDK_NM_aktiv_Diagnose 0 "Init" 1 "Diagnose_aktiv" ;
VAL_ 2600468491 NM_RDK_NM_aktiv_Tmin 0 "Inaktiv" 1 "Mindestaktivzeit" ;
VAL_ 2600468491 NM_RDK_CAB 0 "inaktiv" 1 "CAB_01__Tueren" 2 "CAB_02__Anhaenger_KCAN" 4 "CAB_03__Nightvision" 8 "CAB_04__Sitzverstellung" 16 "CAB_05__Klappen" 32 "CAB_06__Infotainment" 64 "CAB_07__Sub_Infotainment" 128 "CAB_08__Anzeige" 256 "CAB_09__Laden_HCAN" 512 "CAB_10__Klima" 1024 "CAB_11__FlexRay" 262144 "CAB_19__VLAN_RemoteFC" 524288 "CAB_20__VLAN_Komfort" 1048576 "CAB_21__VLAN_Internet" 2097152 "CAB_22__VLAN_Connect" 4194304 "CAB_23__VLAN_Infotainment" 8388608 "CAB_24__VLAN_FAS" ;
